VERSION ""

NS_ :

BS_:

BU_: ECM

BO_ 1483 ELATCH9: 32 Vector__XXX
 SG_ Ajar : 1|1@0+ (1,0) [0|1] "" ECM
 SG_ CRC_ELATCH9 : 191|8@0+ (1,0) [0|255] "-" ECM
 SG_ MessageCounter_ELATCH9 : 179|4@0+ (1,0) [0|15] "-" ECM
 SG_ Pawl : 15|1@0+ (1,0) [0|1] "" ECM
 SG_ Pre_Rest : 0|1@0+ (1,0) [0|1] "" ECM
 SG_ Rewind : 14|1@0+ (1,0) [0|1] "" ECM

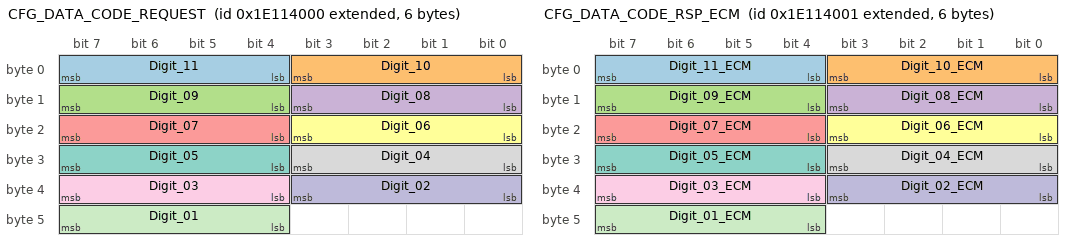
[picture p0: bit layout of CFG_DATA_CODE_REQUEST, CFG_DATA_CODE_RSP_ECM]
BO_ 2651930624 CFG_DATA_CODE_REQUEST: 6 Vector__XXX
 SG_ Digit_11 : 7|4@0+ (1,0) [0|15] "" ECM
 SG_ Digit_10 : 3|4@0+ (1,0) [0|15] "" ECM
 SG_ Digit_09 : 15|4@0+ (1,0) [0|15] "" ECM
 SG_ Digit_08 : 11|4@0+ (1,0) [0|15] "" ECM
 SG_ Digit_07 : 23|4@0+ (1,0) [0|15] "" ECM
 SG_ Digit_06 : 19|4@0+ (1,0) [0|15] "" ECM
 SG_ Digit_05 : 31|4@0+ (1,0) [0|15] "" ECM
 SG_ Digit_04 : 27|4@0+ (1,0) [0|15] "" ECM
 SG_ Digit_03 : 39|4@0+ (1,0) [0|15] "" ECM
 SG_ Digit_02 : 35|4@0+ (1,0) [0|15] "" ECM
 SG_ Digit_01 : 47|4@0+ (1,0) [0|15] "" ECM

BO_ 2651930625 CFG_DATA_CODE_RSP_ECM: 6 ECM
 SG_ Digit_11_ECM : 7|4@0+ (1,0) [0|15] "-"  Vector__XXX
 SG_ Digit_10_ECM : 3|4@0+ (1,0) [0|15] "-"  Vector__XXX
 SG_ Digit_09_ECM : 15|4@0+ (1,0) [0|15] "-"  Vector__XXX
 SG_ Digit_08_ECM : 11|4@0+ (1,0) [0|15] "-"  Vector__XXX
 SG_ Digit_07_ECM : 23|4@0+ (1,0) [0|15] "-"  Vector__XXX
 SG_ Digit_06_ECM : 19|4@0+ (1,0) [0|15] "-"  Vector__XXX
 SG_ Digit_05_ECM : 31|4@0+ (1,0) [0|15] "-"  Vector__XXX
 SG_ Digit_04_ECM : 27|4@0+ (1,0) [0|15] "-"  Vector__XXX
 SG_ Digit_03_ECM : 39|4@0+ (1,0) [0|15] "-"  Vector__XXX
 SG_ Digit_02_ECM : 35|4@0+ (1,0) [0|15] "-"  Vector__XXX
 SG_ Digit_01_ECM : 47|4@0+ (1,0) [0|15] "-"  Vector__XXX

BO_ 2564428017 DIAGNOSTIC_REQUEST_ECM: 8 Vector__XXX
 SG_ N_PDU_18DA10F1 : 7|64@0+ (1,0) [0|0] "" ECM

BO_ 2564554481 DIAGNOSTIC_REQUEST_FUNCTIONAL: 8 Vector__XXX
 SG_ N_PDU_18DBFEF1 : 7|64@0+ (1,0) [0|0] "" ECM

BO_ 2564502513 DIAGNOSTIC_REQUEST_FUNC_OBD: 8 Vector__XXX
 SG_ N_PDU_18DB33F1 : 7|64@0+ (1,0) [0|0] "" ECM

BO_ 2564485392 DIAGNOSTIC_RESPONSE_ECM: 8 ECM
 SG_ N_PDU_18DAF110 : 7|64@0+ (1,0) [0|0] "" Vector__XXX

BO_ 1053 VIN: 32 Vector__XXX
 SG_ VIN_MSG : 75|2@0+ (1,0) [0|3] "" ECM
 SG_ VIN_DATA : 87|56@0+ (1,0) [0|72057594037927900] "" ECM

BO_ 1450 TRANSM_FD_4: 32 Vector__XXX
 SG_ TxDisengaged : 126|1@0+ (1,0) [0|1] "-"  ECM
 SG_ TransmissionFailSts : 87|1@0+ (1,0) [0|1] "-"  ECM
 SG_ ShiftModeSts : 94|1@0+ (1,0) [0|1] "-"  ECM
 SG_ ShiftLeverPosition : 111|4@0+ (1,0) [0|15] "-"  ECM
 SG_ ShiftInProgress : 114|1@0+ (1,0) [0|1] "-"  ECM
 SG_ MIReq : 127|1@0+ (1,0) [0|1] "-"  ECM
 SG_ LimpHomeSts : 112|1@0+ (1,0) [0|1] "-"  ECM
 SG_ GearEngaged : 107|4@0+ (1,0) [0|15] "-"  ECM
 SG_ CrankEnable : 113|1@0+ (1,0) [0|1] "-"  ECM
 SG_ ShiftMapNotAchieved : 121|1@0+ (1,0) [0|1] "-"  ECM
 SG_ MessageCounter_TRANSM4 : 179|4@0+ (1,0) [0|15] "-"  ECM
 SG_ CRC_TRANSM4 : 191|8@0+ (1,0) [0|255] "-"  ECM
 SG_ TxDisengaged_Fault : 118|1@0+ (1,0) [0|1] "-"  ECM
 SG_ Low_Mode_Sts : 181|2@0+ (1,0) [0|3] "" ECM

BO_ 520 TRANSM_FD_2: 32 Vector__XXX
 SG_ TurbineSpeed : 111|16@0+ (1,0) [0|65534] "RPM"  ECM
 SG_ TRNS_StpSt_FLT : 125|1@0+ (1,0) [0|1] "-"  ECM
 SG_ Trns_EMCC_Achvd : 96|1@0+ (1,0) [0|1] "-"  ECM
 SG_ TransReadyForESS : 124|1@0+ (1,0) [0|1] "-"  ECM
 SG_ TransmissionTemperature : 103|6@0+ (3,-40) [-40|149] "°C"  ECM
 SG_ OUTPUT_SPEED : 87|16@0+ (1,0) [0|65534] "RPM"  ECM
 SG_ APCM_Rq : 135|2@0+ (1,0) [0|2] "-"  ECM
 SG_ MessageCounter_TRANSM2 : 179|4@0+ (1,0) [0|15] "-"  ECM
 SG_ EngShutOffRq_TCM : 123|1@0+ (1,0) [0|1] "-"  ECM
 SG_ CRC_TRANSM2 : 191|8@0+ (1,0) [0|255] "-"  ECM
 SG_ Trans_ESS_Inhibit : 2|1@0+ (1,0) [0|1] "-"  ECM
 SG_ GearEngagedForDisplay : 15|5@0+ (1,0) [0|30] "-"  ECM
 SG_ AirFlowRequest_TCM : 22|7@0+ (1,0) [0|100] "%"  ECM

BO_ 1428 TELEMATIC_FD_5: 32 Vector__XXX
 SG_ GlobDrvMdRq : 7|5@0+ (1,0) [0|31] "" ECM

BO_ 156 TELEMATIC_FD_1: 32 Vector__XXX
 SG_ Year4_TLM : 127|4@0+ (1,0) [0|9] "-"  ECM
 SG_ Year3_TLM : 115|4@0+ (1,0) [0|9] "-"  ECM
 SG_ Year2_TLM : 119|4@0+ (1,0) [0|9] "-"  ECM
 SG_ Year1_TLM : 107|4@0+ (1,0) [0|2] "-"  ECM
 SG_ Month2_TLM : 111|4@0+ (1,0) [0|9] "-"  ECM
 SG_ Month1_TLM : 99|4@0+ (1,0) [0|1] "-"  ECM
 SG_ Minute2_TLM : 103|4@0+ (1,0) [0|9] "-"  ECM
 SG_ Minute1_TLM : 91|4@0+ (1,0) [0|5] "-"  ECM
 SG_ Hour2_TLM : 95|4@0+ (1,0) [0|9] "-"  ECM
 SG_ Hour1_TLM : 83|4@0+ (1,0) [0|2] "-"  ECM
 SG_ Day2_TLM : 87|4@0+ (1,0) [0|9] "-"  ECM
 SG_ Day1_TLM : 75|4@0+ (1,0) [0|3] "-"  ECM

BO_ 519 RFHUB_FD_1: 32 Vector__XXX
 SG_ IgnPosSts : 85|3@0+ (1,0) [0|6] "-"  ECM
 SG_ MessageCounter_RFHUB1 : 179|4@0+ (1,0) [0|15] "-"  ECM
 SG_ CRC_RFHUB1 : 191|8@0+ (1,0) [0|255] "-"  ECM

BO_ 274 ORC_FD_3: 32 Vector__XXX
 SG_ LongAcceleration : 131|12@0+ (0.02,-40.96) [-40.96|40.92] "m/s^2"  ECM
 SG_ LatAcceleration : 147|12@0+ (0.02,-40.96) [-40.96|40.92] "m/s^2"  ECM
 SG_ MessageCounter_ORC3 : 179|4@0+ (1,0) [0|15] "-"  ECM
 SG_ LongAccelerationFailSts : 183|1@0+ (1,0) [0|1] "-"  ECM
 SG_ LatAccelerationFailSts : 182|1@0+ (1,0) [0|1] "-"  ECM
 SG_ CRC_ORC3 : 191|8@0+ (1,0) [0|255] "-"  ECM

BO_ 1954 ORC_FD_2: 32 Vector__XXX
 SG_ MessageCounter_ORC2 : 179|4@0+ (1,0) [0|15] "-"  ECM
 SG_ CRC_ORC2 : 191|8@0+ (1,0) [0|255] "-"  ECM
 SG_ DrvSbltUnFltr_1 : 119|8@0+ (0.1,0) [0|25.5] "mA"  ECM

BO_ 1058 OBD_CONTENT_FRAME: 32 ECM
 SG_ LoadOBD : 87|8@0+ (0.3922,0) [0|100] "%"  Vector__XXX
 SG_ InputsGDFail : 94|1@0+ (1,0) [0|1] "-"  Vector__XXX
 SG_ Inp_ICC_Fail : 117|1@0+ (1,0) [0|1] "-"  Vector__XXX
 SG_ IgnCntrTrue : 118|1@0+ (1,0) [0|1] "-"  Vector__XXX
 SG_ GenDenominator : 95|1@0+ (1,0) [0|1] "-"  Vector__XXX
 SG_ EngineOFFTime : 89|10@0+ (1,0) [0|1022] "min"  Vector__XXX
 SG_ CldStrtDenominator : 116|1@0+ (1,0) [0|1] "-"  Vector__XXX
 SG_ CarbWarmUp : 93|1@0+ (1,0) [0|1] "-"  Vector__XXX
 SG_ CARB_PERM : 119|1@0+ (1,0) [0|1] "-"  Vector__XXX
 SG_ AccelPdlPosn_OBD : 111|8@0+ (0.3922,0) [0|100] "%"  Vector__XXX
 SG_ OAT_PT_EstV : 60|1@0+ (1,0) [0|0] "-"  Vector__XXX
 SG_ OAT_PT_Est : 55|8@0+ (1,-64) [-64|191] "°C"  Vector__XXX
 SG_ LgsDiagStndCondMet : 59|1@0+ (1,0) [0|0] "-"  Vector__XXX
 SG_ LgsDiagStndCondFltPrs : 58|1@0+ (1,0) [0|0] "-"  Vector__XXX
 SG_ LgsDiagCldStrtCndMet : 57|1@0+ (1,0) [0|0] "-"  Vector__XXX
 SG_ LgsDiagCldStrtCndFltPr : 56|1@0+ (1,0) [0|0] "-"  Vector__XXX
 SG_ InpICCFuelEng_Fail : 7|1@0+ (1,0) [0|0] "-"  Vector__XXX
 SG_ IgnCntrFuelEngTrue : 6|1@0+ (1,0) [0|0] "-"  Vector__XXX
 SG_ EstCatCnvTmp : 47|8@0+ (5,0) [0|1270] "°C"  Vector__XXX
 SG_ EngOffTmPTV : 5|1@0+ (1,0) [0|0] "-"  Vector__XXX
 SG_ EngOffTmPT : 3|12@0+ (0.5,0) [0.5|2047.5] "min"  Vector__XXX
 SG_ EngLoad_OBD_ePT : 31|8@0+ (0.3922,0) [0|100] "%"  Vector__XXX
 SG_ EngIntAirTmpV : 4|1@0+ (1,0) [0|0] "-"  Vector__XXX
 SG_ EngIntAirTmp : 23|8@0+ (1,-40) [-40|214] "°C"  Vector__XXX
 SG_ ECM_HoodAjar : 91|2@0+ (1,0) [0|3] "-"  Vector__XXX
 SG_ BarPrsAbsV : 92|1@0+ (1,0) [0|0] "-"  Vector__XXX
 SG_ BarPrsAbs : 39|8@0+ (0.5,0) [0|127.5] "kPa"  Vector__XXX
 SG_ MessageCounter_OBDCONTENTFRAME : 179|4@0+ (1,0) [0|15] "-"  Vector__XXX
 SG_ CRC_OBDCONTENTFRAME : 191|8@0+ (1,0) [0|255] "-"  Vector__XXX

BO_ 600 IPC_FD_4: 32 Vector__XXX
 SG_ OilChgRst : 162|1@0+ (1,0) [0|1] "" ECM
 SG_ DisplayedSpeedLimSts : 119|8@0+ (1,0) [0|255] "" ECM

BO_ 1829 IPC_FD_1: 32 Vector__XXX
 SG_ TotalOdometer : 75|20@0+ (1,0) [0|1048575] "km"  ECM
 SG_ MessageCounter_IPC1 : 179|4@0+ (1,0) [0|15] "-"  ECM
 SG_ CRC_IPC1 : 191|8@0+ (1,0) [0|255] "-"  ECM

BO_ 1626 IMPACT_INFO: 32 Vector__XXX
 SG_ IMPACTConfirm : 81|1@0+ (1,0) [0|1] "-"  ECM
 SG_ IMPACTCommand : 80|1@0+ (1,0) [0|1] "-"  ECM
 SG_ IMPACTThreshold : 103|1@0+ (1,0) [0|1] "-"  ECM

BO_ 104 IMMO_CODE_RESPONSE: 32 Vector__XXX
 SG_ MKKey2org22 : 103|8@0+ (1,0) [0|255] "-"  ECM
 SG_ MKKey1org21 : 95|8@0+ (1,0) [0|255] "-"  ECM
 SG_ MKKey_6 : 135|8@0+ (1,0) [0|255] "-"  ECM
 SG_ MKKey_5 : 127|8@0+ (1,0) [0|255] "-"  ECM
 SG_ MKKey_4 : 119|8@0+ (1,0) [0|255] "-"  ECM
 SG_ MKKey_3 : 111|8@0+ (1,0) [0|255] "-"  ECM
 SG_ ControlEncodingRsp : 87|8@0+ (1,0) [0|255] "-"  ECM

BO_ 100 IMMO_CODE_REQUEST: 32 ECM
 SG_ rnd_4 : 135|8@0+ (1,0) [0|255] "-"  Vector__XXX
 SG_ rnd_3 : 127|8@0+ (1,0) [0|255] "-"  Vector__XXX
 SG_ rnd_2 : 119|8@0+ (1,0) [0|255] "-"  Vector__XXX
 SG_ rnd_1 : 111|8@0+ (1,0) [0|255] "-"  Vector__XXX
 SG_ f1_2 : 103|8@0+ (1,0) [0|255] "-"  Vector__XXX
 SG_ f1_1 : 95|8@0+ (1,0) [0|255] "-"  Vector__XXX
 SG_ ControlEncodingReq : 87|8@0+ (1,0) [0|255] "-"  Vector__XXX

BO_ 1955 IBS3_DATA_2: 32 Vector__XXX
 SG_ IBS3_T_BATT : 95|8@0+ (1,-40) [-40|105] "°C"  ECM
 SG_ IBS3_SOH_Q : 110|7@0+ (2,0) [0|252] "Ah"  ECM
 SG_ IBS3_SOC : 86|7@0+ (1,0) [0|100] "%"  ECM
 SG_ IBS3_TempFailStatus : 111|1@0+ (1,0) [0|1] "" ECM
 SG_ IBS3_SOH_Q_Accuracy : 119|1@0+ (1,0) [0|1] "" ECM
 SG_ IBS3_SOC_Accuracy : 87|1@0+ (1,0) [0|1] "" ECM
 SG_ IBS3_FLAG_DISCONNECT : 117|1@0+ (1,0) [0|1] "" ECM

BO_ 264 EPS_FD_1: 32 Vector__XXX
 SG_ LwsAngle : 7|16@0+ (0.1,-720) [-720|720] "°"  ECM
 SG_ LwsSpeed : 19|12@0+ (1,-2000) [-2000|2094] "°/s"  ECM
 SG_ MessageCounter_EPS1 : 179|4@0+ (1,0) [0|15] "-"  ECM
 SG_ CRC_EPS1 : 191|8@0+ (1,0) [0|255] "-"  ECM
 SG_ EngineFanRequestActivation : 38|1@0+ (1,0) [0|1] "-"  ECM

CM_ "Project_WL25_ProjectStandard_FD-CAN3 [CS00155_FD]";
CM_ SG_ 1483 Ajar "Driver Door Ajar Sensor for e-Latch.";
CM_ SG_ 1483 CRC_ELATCH9 "CRC according to SAE J1850 standard at each frame transmission.";
CM_ SG_ 1483 MessageCounter_ELATCH9 "This signal is a counter used for safety checks strategies. This counter is incremented of 1 (one) unit at each frame transmission.";
CM_ SG_ 1483 Pawl "Pawl Driver Door Sensor for e-Latch.";
CM_ SG_ 1483 Pre_Rest "Pre Rest Driver Door Sensor for e-Latch.";
CM_ SG_ 1483 Rewind "Pawl Driver Door Sensor for e-Latch.";
CM_ SG_ 100 ControlEncodingReq "This signal is used for IMMO communication";
CM_ SG_ 100 f1_1 "This signal is used for IMMO communication";
CM_ SG_ 100 f1_2 "This signal is used for IMMO communication";
CM_ SG_ 100 rnd_1 "This signal is used for IMMO communication";
CM_ SG_ 100 rnd_2 "This signal is used for IMMO communication";
CM_ SG_ 100 rnd_3 "This signal is used for IMMO communication";
CM_ SG_ 100 rnd_4 "This signal is used for IMMO communication";
CM_ SG_ 1058 AccelPdlPosn_OBD "Pedal value for OBD (ISO 15031-5.4 PID 49)";
CM_ SG_ 1058 CARB_PERM "Fault code for diagnostics.";
CM_ SG_ 1058 CarbWarmUp "CARB warmup criteria true.  The engine controller will set this bit when the engine coolant temp achieves the CARB warm-up criteria.";
CM_ SG_ 1058 CldStrtDenominator "Cold start denominator conditions are met [1]";
CM_ SG_ 1058 OAT_PT_EstV "Outside air temperature powertrain estimated validity; Invalid = [1]";
CM_ SG_ 1058 InpICCFuelEng_Fail "Second Ignition Cycle Counter Fault Present";
CM_ SG_ 1058 LgsDiagCldStrtCndFltPr "Legislated diagnostics cold start conditions fault present; true = [1]";
CM_ SG_ 1058 LgsDiagCldStrtCndMet "Legislated diagnostics cold start conditions met; true = [1]";
CM_ SG_ 1058 LgsDiagStndCondFltPrs "Legislated diagnostics standard conditions fault present";
CM_ SG_ 1058 LgsDiagStndCondMet "Legislated diagnostics standard conditions met";
CM_ SG_ 1058 OAT_PT_Est "Outside air temperature powertrain estimated";
CM_ SG_ 1058 EngIntAirTmpV "Engine Intake Air Temperature Validity; Invalid = [1]";
CM_ SG_ 1058 EngLoad_OBD_ePT "Load value for OBD (ISO 15031-5.4 PID 4)";
CM_ SG_ 1058 EngOffTmPT "Engine off time powertrain";
CM_ SG_ 1058 EngOffTmPTV "Engine off time powertrain validity (1=invalid)";
CM_ SG_ 1058 EstCatCnvTmp "Estimated catalytic converter temperature";
CM_ SG_ 1058 IgnCntrFuelEngTrue "Second Ignition Cycle Counter";
CM_ SG_ 1058 BarPrsAbs "Barometric pressure absolute";
CM_ SG_ 1058 BarPrsAbsV "Barometric Pressure Absolute Validity; Invalid = [1]";
CM_ SG_ 1058 ECM_HoodAjar "Diagnosed hood status for HVIL.";
CM_ SG_ 1058 EngIntAirTmp "Engine Intake Air Temperature";
CM_ SG_ 1058 MessageCounter_OBDCONTENTFRAME "This signal is a counter used for safety checks strategies. This counter is incremented of 1 (one) unit at each frame transmission.";
CM_ SG_ 264 EngineFanRequestActivation "This signal is used to activate the cooling fun by the electric power steering.";
CM_ SG_ 264 CRC_EPS1 "CRC according to SAE J1850 standard at each frame transmission.";
CM_ SG_ 264 MessageCounter_EPS1 "This signal is a counter used for safety checks strategies. This counter is incremented of 1 (one) unit at each frame transmission.";
CM_ SG_ 1058 CRC_OBDCONTENTFRAME "CRC according to SAE J1850 standard at each frame transmission.";
CM_ SG_ 1058 EngineOFFTime "The number of minutes the engine was off.";
CM_ SG_ 1058 GenDenominator "General denominator conditions are met.  The engine controller will set this bit when the conditions for setting the General Denominator are met for rate based diagnostics.";
CM_ SG_ 1058 IgnCntrTrue "Ignition cycle counter is true [1]";
CM_ SG_ 1058 Inp_ICC_Fail "Inputs to the Ign Cycle Cntr are in a Pend or MIL cond.";
CM_ SG_ 1058 InputsGDFail "General Denominator Requirements Achieved Validity. The engine controller sets this bit when any of the inputs to the General Denominator are in a pending or MIL fault.";
CM_ SG_ 1058 LoadOBD "Engine calculated load value in percentage of load.";
CM_ SG_ 2564485392 N_PDU_18DAF110 "This signal is used for diagnostic purposes";
CM_ SG_ 519 CRC_RFHUB1 "CRC according to SAE J1850 standard at each frame transmission.";
CM_ SG_ 519 MessageCounter_RFHUB1 "This signal is a counter used for safety checks strategies. This counter is incremented of 1 (one) unit at each frame transmission.";
CM_ SG_ 519 IgnPosSts "-";
CM_ SG_ 1428 GlobDrvMdRq "Global drive mode radio request";
CM_ SG_ 264 LwsSpeed "This signal indicates the steering speed value, counterclockwise positive.";
CM_ SG_ 264 LwsAngle "This signal indicates the steering angle value, counterclockwise positive.";
CM_ SG_ 1955 IBS3_FLAG_DISCONNECT "Battery disconnection flag";
CM_ SG_ 1955 IBS3_SOC_Accuracy "SOC accuracy status";
CM_ SG_ 1955 IBS3_SOH_Q_Accuracy "SOH_Q accuracy status";
CM_ SG_ 1955 IBS3_TempFailStatus "Failure of ASIC Temperature meas. (internal defect)";
CM_ SG_ 1955 IBS3_SOC "State of charge";
CM_ SG_ 1955 IBS3_SOH_Q "State of health related to capacity (energy)";
CM_ SG_ 1955 IBS3_T_BATT "Battery temperature";
CM_ SG_ 104 ControlEncodingRsp "This signal is used for IMMO communication";
CM_ SG_ 104 MKKey_3 "This signal is used for IMMO communication";
CM_ SG_ 104 MKKey_4 "This signal is used for IMMO communication";
CM_ SG_ 104 MKKey_5 "This signal is used for IMMO communication";
CM_ SG_ 104 MKKey_6 "This signal is used for IMMO communication";
CM_ SG_ 104 MKKey1org21 "This signal is used for IMMO communication";
CM_ SG_ 104 MKKey2org22 "This signal is used for IMMO communication";
CM_ SG_ 1626 IMPACTThreshold "Upon a crash, the ORC Calibration Threshold was either \"Met\" or \"Not_Met\".";
CM_ SG_ 1626 IMPACTCommand "This signal is used to indicate that a crash happened";
CM_ SG_ 1626 IMPACTConfirm "This signal is used to confirm that a crash happened";
CM_ SG_ 1829 CRC_IPC1 "CRC according to SAE J1850 standard at each frame transmission.";
CM_ SG_ 1829 MessageCounter_IPC1 "This signal is a counter used for safety checks strategies. This counter is incremented of 1 (one) unit at each frame transmission.";
CM_ SG_ 1829 TotalOdometer "Used to give information about the total odometer value in km.";
CM_ SG_ 600 DisplayedSpeedLimSts "This signal indicates the road sign of vehicle speed limit displayed by IPC";
CM_ SG_ 600 OilChgRst "This signal sends the reset command via the EVIC.";
CM_ SG_ 1954 DrvSbltUnFltr_1 "Driver seatbelt fault status - unfiltered";
CM_ SG_ 1954 CRC_ORC2 "CRC according to SAE J1850 standard at each frame transmission.";
CM_ SG_ 1954 MessageCounter_ORC2 "This signal is a counter used for safety checks strategies. This counter is incremented of 1 (one) unit at each frame transmission.";
CM_ SG_ 274 CRC_ORC3 "CRC according to SAE J1850 standard at each frame transmission.";
CM_ SG_ 274 LatAccelerationFailSts "This signal indicates the status of Lateral Acceleration Signal";
CM_ SG_ 274 LongAccelerationFailSts "This signal indicates the status of Longitudinal acceleration signal";
CM_ SG_ 274 MessageCounter_ORC3 "This signal is a counter used for safety checks strategies. This counter is incremented of 1 (one) unit at each frame transmission.";
CM_ SG_ 274 LatAcceleration "This signal indicates the Lateral Acceleration Value";
CM_ SG_ 274 LongAcceleration "This signal indicates the Longitudinal Acceleration Value";
CM_ SG_ 520 APCM_Rq "Auto position correction mode request";
CM_ SG_ 520 OUTPUT_SPEED "Activation request flag for P2 speed  profile";
CM_ SG_ 520 MessageCounter_TRANSM2 "This signal is a counter used for safety checks strategies. This counter is incremented of 1 (one) unit at each frame transmission.";
CM_ SG_ 520 CRC_TRANSM2 "CRC according to SAE J1850 standard at each frame transmission.";
CM_ SG_ 520 EngShutOffRq_TCM "TCM request engine shut off";
CM_ SG_ 520 AirFlowRequest_TCM "Request from TCM to activate AGS,Rad Fan";
CM_ SG_ 520 GearEngagedForDisplay "Transmission Gear engaged signal for Display on cluster.";
CM_ SG_ 520 Trans_ESS_Inhibit "ESS inhibit flag from transmission related to temperature warnings.";
CM_ SG_ 520 TransmissionTemperature "-";
CM_ SG_ 520 TransReadyForESS "-";
CM_ SG_ 520 Trns_EMCC_Achvd "-";
CM_ SG_ 520 TRNS_StpSt_FLT "-";
CM_ SG_ 520 TurbineSpeed "-";
CM_ SG_ 1450 Low_Mode_Sts "Signal Indicating L Mode Status";
CM_ SG_ 1450 MessageCounter_TRANSM4 "This signal is a counter used for safety checks strategies. This counter is incremented of 1 (one) unit at each frame transmission.";
CM_ SG_ 1450 ShiftMapNotAchieved "Transmission shift in progress";
CM_ SG_ 1450 CrankEnable "This signal is used to enable the cranking in safety condition";
CM_ SG_ 1450 GearEngaged "Current engaged gear.";
CM_ SG_ 1450 LimpHomeSts "This signal is used in case of those gearbox faults that limit the higher usable gear.";
CM_ SG_ 1450 TxDisengaged_Fault "Transmission is disengaged";
CM_ SG_ 1450 CRC_TRANSM4 "CRC according to SAE J1850 standard at each frame transmission.";
CM_ SG_ 1450 MIReq "This signal indicates that the gearbox has any EOBD errors.";
CM_ SG_ 1450 ShiftInProgress "Transmission shift in progress";
CM_ SG_ 1450 ShiftLeverPosition "This signal indicates the executed shift lever position.";
CM_ SG_ 1450 ShiftModeSts "This signal indicates the gear selector modality selected by driver (Manual or Automatic).";
CM_ SG_ 1450 TransmissionFailSts "This signal indicates if the TCM currently detects the failure or not (for TCM)";
CM_ SG_ 1450 TxDisengaged "Transmission is disengaged";
CM_ SG_ 1053 VIN_DATA "VIN Digits (8 bit ascii encoded)";
CM_ SG_ 1053 VIN_MSG "VIN Message Information";
CM_ SG_ 2564502513 N_PDU_18DB33F1 "This signal is used for diagnostic purposes";
CM_ SG_ 2564554481 N_PDU_18DBFEF1 "This signal is used for diagnostic purposes";
CM_ SG_ 2564428017 N_PDU_18DA10F1 "This signal is used for diagnostic purposes";
BA_DEF_ SG_ "GenSigTimeoutTime_ADCAM" INT 0 65535;
BA_DEF_ SG_ "GenSigTimeoutTime_EVCU2" INT 0 65535;
BA_DEF_ SG_ "GenSigTimeoutTime_VDCM" INT 0 65535;
BA_DEF_ SG_ "GenSigStartValue" INT 0 2147483647;
BA_DEF_ SG_ "GenSigInactiveValue" INT 0 2147483647;
BA_DEF_ SG_ "GenSigSendType" ENUM "NotUsed","OnWrite","OnWriteWithRepetition","OnChange","OnChangeWithRepetition","IfActive","IfActiveWithRepetition","NoSigSendType";
BA_DEF_ SG_ "SystemSignalLongSymbol" STRING ;
BA_DEF_ SG_ "GenSigTimeoutTime_AGSM" INT 0 65535;
BA_DEF_ SG_ "GenSigTimeoutTime_ASBS" INT 0 65535;
BA_DEF_ SG_ "GenSigTimeoutTime_BCM" INT 0 65535;
BA_DEF_ SG_ "GenSigTimeoutTime_BSM" INT 0 65535;
BA_DEF_ SG_ "GenSigTimeoutTime_CADM" INT 0 65535;
BA_DEF_ SG_ "GenSigTimeoutTime_DMSM" INT 0 65535;
BA_DEF_ SG_ "GenSigTimeoutTime_DTCM" INT 0 65535;
BA_DEF_ SG_ "GenSigTimeoutTime_ECM" INT 0 65535;
BA_DEF_ SG_ "GenSigTimeoutTime_ELSDM" INT 0 65535;
BA_DEF_ SG_ "GenSigTimeoutTime_ESL" INT 0 65535;
BA_DEF_ SG_ "GenSigTimeoutTime_GNMM" INT 0 65535;
BA_DEF_ SG_ "GenSigTimeoutTime_HCP" INT 0 65535;
BA_DEF_ SG_ "GenSigTimeoutTime_IPC" INT 0 65535;
BA_DEF_ SG_ "GenSigTimeoutTime_RFHM" INT 0 65535;
BA_DEF_ SG_ "GenSigTimeoutTime_SGW" INT 0 65535;
BA_DEF_ SG_ "GenSigTimeoutTime_TCM" INT 0 65535;
BA_DEF_ BO_ "DiagRequest" ENUM "No","Yes";
BA_DEF_ BO_ "Type" ENUM "P","C","PE","COC","PE_Cntrl","E","E_Cntrl","OC","S","BAF","DC","EM","MM","ISO-TP","-";
BA_DEF_ BO_ "DiagResponse" ENUM "No","Yes";
BA_DEF_ BO_ "NmMessage" ENUM "No","Yes";
BA_DEF_ BO_ "GenMsgSendType" ENUM "Cyclic","NotUsed","NotUsed","NotUsed","NotUsed","NotUsed","NotUsed","NotUsed","NoMsgSendType";
BA_DEF_ BO_ "GenMsgNrOfRepetition" INT 0 255;
BA_DEF_ BO_ "GenMsgILSupport" ENUM "No","Yes";
BA_DEF_ BO_ "GenMsgStartDelayTime" INT 0 65535;
BA_DEF_ BO_ "GenMsgCycleTimeFast" INT 0 65535;
BA_DEF_ BO_ "GenMsgCycleTime" INT 0 65535;
BA_DEF_ BO_ "GenMsgDelayTime" INT 0 65535;
BA_DEF_ BO_ "NmAsrMessage" ENUM "No","Yes";
BA_DEF_ BO_ "DiagState" ENUM "No","Yes";
BA_DEF_ BO_ "DiagConnection" HEX 0 65535;
BA_DEF_ BO_ "VFrameFormat" ENUM "StandardCAN","ExtendedCAN","reserved","reserved","reserved","reserved","reserved","reserved","reserved","reserved","reserved","reserved","reserved","reserved","StandardCAN_FD","ExtendedCAN_FD";
BA_DEF_ BO_ "CANFD_BRS" ENUM "0","1";
BA_DEF_ "Manufacturer" ENUM "DBAG","VAG","BWVAG","PAG","GM";
BA_DEF_ "NmType" STRING ;
BA_DEF_ "BusType" STRING ;
BA_DEF_ "Baudrate" INT 0 1000000;
BA_DEF_ "DBName" STRING ;
BA_DEF_ "NmAsrTimeoutTime" INT 1 65535;
BA_DEF_ "NmAsrWaitBusSleepTime" INT 1 65535;
BA_DEF_ "NmAsrRepeatMessageTime" INT 1 65535;
BA_DEF_ "NmAsrMessageCount" INT 1 256;
BA_DEF_ "NmAsrBaseAddress" HEX 235487232 2147483647;
BA_DEF_ "NmAsrCanMsgCycleTime" INT 1 65535;
BA_DEF_ "Version" HEX 0 255;
BA_DEF_ "VersionWeek" INT 0 53;
BA_DEF_ "VersionYear" INT 0 99;
BA_DEF_ BU_ "Description" STRING ;
BA_DEF_ BU_ "NmStationAddress" HEX 0 255;
BA_DEF_ BU_ "NmNode" ENUM "No","Yes";
BA_DEF_ BU_ "NmAsrNode" ENUM "No","Yes";
BA_DEF_ BU_ "NmAsrNodeIdentifier" HEX 0 255;
BA_DEF_ BU_ "NmAsrCanMsgReducedTime" INT 1 65535;
BA_DEF_ BU_ "NmNodeType" ENUM "+15_NotWakeable","+30_Wakeable","+30_NotWakeable","kMaster","kSlave15","kSlave30","none";
BA_DEF_ BU_ "NwmNodeType" ENUM "+15_NotWakeable","+30_Wakeable","+30_NotWakeable","kMaster","kSlave15","kSlave30","none";
BA_DEF_DEF_ "GenSigTimeoutTime_ADCAM" 2500;
BA_DEF_DEF_ "GenSigTimeoutTime_EVCU2" 2500;
BA_DEF_DEF_ "GenSigTimeoutTime_VDCM" 2500;
BA_DEF_DEF_ "GenSigStartValue" 0;
BA_DEF_DEF_ "GenSigInactiveValue" 0;
BA_DEF_DEF_ "GenSigSendType" "NoSigSendType";
BA_DEF_DEF_ "SystemSignalLongSymbol" "";
BA_DEF_DEF_ "GenSigTimeoutTime_AGSM" 2500;
BA_DEF_DEF_ "GenSigTimeoutTime_ASBS" 2500;
BA_DEF_DEF_ "GenSigTimeoutTime_BCM" 2500;
BA_DEF_DEF_ "GenSigTimeoutTime_BSM" 2500;
BA_DEF_DEF_ "GenSigTimeoutTime_CADM" 2500;
BA_DEF_DEF_ "GenSigTimeoutTime_DMSM" 2500;
BA_DEF_DEF_ "GenSigTimeoutTime_DTCM" 2500;
BA_DEF_DEF_ "GenSigTimeoutTime_ECM" 2500;
BA_DEF_DEF_ "GenSigTimeoutTime_ELSDM" 2500;
BA_DEF_DEF_ "GenSigTimeoutTime_ESL" 2500;
BA_DEF_DEF_ "GenSigTimeoutTime_GNMM" 2500;
BA_DEF_DEF_ "GenSigTimeoutTime_HCP" 2500;
BA_DEF_DEF_ "GenSigTimeoutTime_IPC" 2500;
BA_DEF_DEF_ "GenSigTimeoutTime_RFHM" 2500;
BA_DEF_DEF_ "GenSigTimeoutTime_SGW" 2500;
BA_DEF_DEF_ "GenSigTimeoutTime_TCM" 2500;
BA_DEF_DEF_ "DiagRequest" "No";
BA_DEF_DEF_ "Type" "-";
BA_DEF_DEF_ "DiagResponse" "No";
BA_DEF_DEF_ "NmMessage" "No";
BA_DEF_DEF_ "GenMsgSendType" "NoMsgSendType";
BA_DEF_DEF_ "GenMsgNrOfRepetition" 0;
BA_DEF_DEF_ "GenMsgILSupport" "No";
BA_DEF_DEF_ "GenMsgStartDelayTime" 0;
BA_DEF_DEF_ "GenMsgCycleTimeFast" 0;
BA_DEF_DEF_ "GenMsgCycleTime" 0;
BA_DEF_DEF_ "GenMsgDelayTime" 0;
BA_DEF_DEF_ "NmAsrMessage" "No";
BA_DEF_DEF_ "DiagState" "No";
BA_DEF_DEF_ "DiagConnection" 0;
BA_DEF_DEF_ "VFrameFormat" "StandardCAN_FD";
BA_DEF_DEF_ "CANFD_BRS" "0";
BA_DEF_DEF_ "Manufacturer" "DBAG";
BA_DEF_DEF_ "NmType" "";
BA_DEF_DEF_ "BusType" "CAN";
BA_DEF_DEF_ "Baudrate" 500000;
BA_DEF_DEF_ "DBName" "CAN";
BA_DEF_DEF_ "NmAsrTimeoutTime" 1000;
BA_DEF_DEF_ "NmAsrWaitBusSleepTime" 750;
BA_DEF_DEF_ "NmAsrRepeatMessageTime" 800;
BA_DEF_DEF_ "NmAsrMessageCount" 256;
BA_DEF_DEF_ "NmAsrBaseAddress" 506724352;
BA_DEF_DEF_ "NmAsrCanMsgCycleTime" 200;
BA_DEF_DEF_ "Version" 160;
BA_DEF_DEF_ "VersionWeek" 34;
BA_DEF_DEF_ "VersionYear" 25;
BA_DEF_DEF_ "Description" "";
BA_DEF_DEF_ "NmStationAddress" 0;
BA_DEF_DEF_ "NmNode" "Yes";
BA_DEF_DEF_ "NmAsrNode" "Yes";
BA_DEF_DEF_ "NmAsrNodeIdentifier" 0;
BA_DEF_DEF_ "NmAsrCanMsgReducedTime" 100;
BA_DEF_DEF_ "NmNodeType" "none";
BA_DEF_DEF_ "NwmNodeType" "none";
BA_ "NmType" "NmAsr";
BA_ "BusType" "CAN FD";
BA_ "DBName" "FDCAN3";
BA_ "NmAsrTimeoutTime" 8000;
BA_ "NmAsrWaitBusSleepTime" 1000;
BA_ "NmAsrRepeatMessageTime" 5000;
BA_ "NmAsrBaseAddress" 507002880;
BA_ "NmAsrCanMsgCycleTime" 1000;
BA_ "Description" BU_ ECM "Engine Control Module";
BA_ "NmStationAddress" BU_ ECM 1;
BA_ "NmAsrNodeIdentifier" BU_ ECM 1;
BA_ "NmAsrCanMsgReducedTime" BU_ ECM 575;
BA_ "NmNodeType" BU_ ECM 1;
BA_ "NwmNodeType" BU_ ECM 1;
BA_ "Type" BO_ 1483 3;
BA_ "GenMsgSendType" BO_ 1483 0;
BA_ "GenMsgNrOfRepetition" BO_ 1483 2;
BA_ "GenMsgILSupport" BO_ 1483 1;
BA_ "GenMsgCycleTime" BO_ 1483 1000;
BA_ "GenMsgDelayTime" BO_ 1483 20;
BA_ "CANFD_BRS" BO_ 1483 1;
BA_ "Type" BO_ 264 1;
BA_ "GenMsgSendType" BO_ 264 0;
BA_ "GenMsgILSupport" BO_ 264 1;
BA_ "GenMsgStartDelayTime" BO_ 264 5;
BA_ "GenMsgCycleTime" BO_ 264 10;
BA_ "CANFD_BRS" BO_ 264 1;
BA_ "Type" BO_ 1955 1;
BA_ "GenMsgSendType" BO_ 1955 0;
BA_ "GenMsgILSupport" BO_ 1955 1;
BA_ "GenMsgStartDelayTime" BO_ 1955 420;
BA_ "GenMsgCycleTime" BO_ 1955 1000;
BA_ "CANFD_BRS" BO_ 1955 1;
BA_ "Type" BO_ 104 11;
BA_ "GenMsgILSupport" BO_ 104 1;
BA_ "CANFD_BRS" BO_ 104 1;
BA_ "Type" BO_ 1626 10;
BA_ "GenMsgSendType" BO_ 1626 0;
BA_ "GenMsgILSupport" BO_ 1626 1;
BA_ "GenMsgStartDelayTime" BO_ 1626 55;
BA_ "GenMsgCycleTimeFast" BO_ 1626 10;
BA_ "GenMsgCycleTime" BO_ 1626 500;
BA_ "CANFD_BRS" BO_ 1626 1;
BA_ "Type" BO_ 1829 1;
BA_ "GenMsgSendType" BO_ 1829 0;
BA_ "GenMsgILSupport" BO_ 1829 1;
BA_ "GenMsgCycleTime" BO_ 1829 1000;
BA_ "CANFD_BRS" BO_ 1829 1;
BA_ "Type" BO_ 600 3;
BA_ "GenMsgSendType" BO_ 600 0;
BA_ "GenMsgNrOfRepetition" BO_ 600 2;
BA_ "GenMsgILSupport" BO_ 600 1;
BA_ "GenMsgCycleTimeFast" BO_ 600 20;
BA_ "GenMsgCycleTime" BO_ 600 100;
BA_ "GenMsgDelayTime" BO_ 600 20;
BA_ "CANFD_BRS" BO_ 600 1;
BA_ "Type" BO_ 1954 3;
BA_ "GenMsgSendType" BO_ 1954 0;
BA_ "GenMsgILSupport" BO_ 1954 1;
BA_ "GenMsgStartDelayTime" BO_ 1954 425;
BA_ "GenMsgCycleTime" BO_ 1954 1000;
BA_ "CANFD_BRS" BO_ 1954 1;
BA_ "Type" BO_ 274 1;
BA_ "GenMsgSendType" BO_ 274 0;
BA_ "GenMsgILSupport" BO_ 274 1;
BA_ "GenMsgStartDelayTime" BO_ 274 5;
BA_ "GenMsgCycleTime" BO_ 274 10;
BA_ "CANFD_BRS" BO_ 274 1;
BA_ "Type" BO_ 156 8;
BA_ "GenMsgILSupport" BO_ 156 1;
BA_ "CANFD_BRS" BO_ 156 1;
BA_ "Type" BO_ 520 1;
BA_ "GenMsgSendType" BO_ 520 0;
BA_ "GenMsgILSupport" BO_ 520 1;
BA_ "GenMsgCycleTime" BO_ 520 20;
BA_ "CANFD_BRS" BO_ 520 1;
BA_ "Type" BO_ 1450 3;
BA_ "GenMsgSendType" BO_ 1450 0;
BA_ "GenMsgNrOfRepetition" BO_ 1450 2;
BA_ "GenMsgILSupport" BO_ 1450 1;
BA_ "GenMsgCycleTimeFast" BO_ 1450 20;
BA_ "GenMsgCycleTime" BO_ 1450 1000;
BA_ "GenMsgDelayTime" BO_ 1450 20;
BA_ "CANFD_BRS" BO_ 1450 1;
BA_ "Type" BO_ 1053 1;
BA_ "GenMsgSendType" BO_ 1053 0;
BA_ "GenMsgILSupport" BO_ 1053 1;
BA_ "GenMsgStartDelayTime" BO_ 1053 95;
BA_ "GenMsgCycleTime" BO_ 1053 100;
BA_ "CANFD_BRS" BO_ 1053 1;
BA_ "Type" BO_ 2564502513 8;
BA_ "DiagState" BO_ 2564502513 1;
BA_ "DiagConnection" BO_ 2564502513 61747;
BA_ "VFrameFormat" BO_ 2564502513 1;
BA_ "Type" BO_ 2564554481 8;
BA_ "DiagState" BO_ 2564554481 1;
BA_ "DiagConnection" BO_ 2564554481 61950;
BA_ "VFrameFormat" BO_ 2564554481 1;
BA_ "DiagRequest" BO_ 2564428017 1;
BA_ "Type" BO_ 2564428017 8;
BA_ "DiagConnection" BO_ 2564428017 61712;
BA_ "VFrameFormat" BO_ 2564428017 1;
BA_ "Type" BO_ 2651930624 8;
BA_ "GenMsgILSupport" BO_ 2651930624 1;
BA_ "GenMsgDelayTime" BO_ 2651930624 10;
BA_ "VFrameFormat" BO_ 2651930624 15;
BA_ "CANFD_BRS" BO_ 2651930624 1;
BA_ "Type" BO_ 519 1;
BA_ "GenMsgSendType" BO_ 519 0;
BA_ "GenMsgILSupport" BO_ 519 1;
BA_ "GenMsgCycleTime" BO_ 519 20;
BA_ "CANFD_BRS" BO_ 519 1;
BA_ "Type" BO_ 1428 3;
BA_ "GenMsgSendType" BO_ 1428 0;
BA_ "GenMsgNrOfRepetition" BO_ 1428 2;
BA_ "GenMsgILSupport" BO_ 1428 1;
BA_ "GenMsgStartDelayTime" BO_ 1428 35;
BA_ "GenMsgCycleTimeFast" BO_ 1428 20;
BA_ "GenMsgCycleTime" BO_ 1428 1000;
BA_ "GenMsgDelayTime" BO_ 1428 20;
BA_ "CANFD_BRS" BO_ 1428 1;
BA_ "GenMsgILSupport" BO_ 2651930625 1;
BA_ "VFrameFormat" BO_ 2651930625 15;
BA_ "CANFD_BRS" BO_ 2651930625 1;
BA_ "Type" BO_ 100 8;
BA_ "GenMsgNrOfRepetition" BO_ 100 2;
BA_ "GenMsgILSupport" BO_ 100 1;
BA_ "GenMsgCycleTimeFast" BO_ 100 20;
BA_ "GenMsgDelayTime" BO_ 100 20;
BA_ "CANFD_BRS" BO_ 100 1;
BA_ "Type" BO_ 1058 1;
BA_ "GenMsgSendType" BO_ 1058 0;
BA_ "GenMsgILSupport" BO_ 1058 1;
BA_ "GenMsgCycleTime" BO_ 1058 100;
BA_ "CANFD_BRS" BO_ 1058 1;
BA_ "Type" BO_ 2564485392 8;
BA_ "DiagResponse" BO_ 2564485392 1;
BA_ "DiagConnection" BO_ 2564485392 61712;
BA_ "VFrameFormat" BO_ 2564485392 1;
BA_ "Type" BO_ 2651930625 11;
BA_ "GenSigSendType" SG_ 1483 Ajar 3;
BA_ "GenSigSendType" SG_ 1483 Pawl 3;
BA_ "GenSigSendType" SG_ 1483 Pre_Rest 3;
BA_ "GenSigSendType" SG_ 1483 Rewind 3;
BA_ "GenSigTimeoutTime_ADCAM" SG_ 1058 GenDenominator 0;
BA_ "GenSigTimeoutTime_EVCU2" SG_ 1058 GenDenominator 0;
BA_ "GenSigTimeoutTime_VDCM" SG_ 1058 GenDenominator 0;
BA_ "GenSigTimeoutTime_TCM" SG_ 1058 GenDenominator 0;
BA_ "GenSigTimeoutTime_ADCAM" SG_ 1058 IgnCntrTrue 0;
BA_ "GenSigTimeoutTime_EVCU2" SG_ 1058 IgnCntrTrue 0;
BA_ "GenSigTimeoutTime_VDCM" SG_ 1058 IgnCntrTrue 0;
BA_ "GenSigTimeoutTime_TCM" SG_ 1058 IgnCntrTrue 0;
BA_ "GenSigTimeoutTime_ADCAM" SG_ 1058 Inp_ICC_Fail 0;
BA_ "GenSigTimeoutTime_EVCU2" SG_ 1058 Inp_ICC_Fail 0;
BA_ "GenSigTimeoutTime_VDCM" SG_ 1058 Inp_ICC_Fail 0;
BA_ "GenSigTimeoutTime_TCM" SG_ 1058 Inp_ICC_Fail 0;
BA_ "GenSigTimeoutTime_ADCAM" SG_ 1058 InputsGDFail 0;
BA_ "GenSigTimeoutTime_EVCU2" SG_ 1058 InputsGDFail 0;
BA_ "GenSigTimeoutTime_VDCM" SG_ 1058 InputsGDFail 0;
BA_ "GenSigTimeoutTime_TCM" SG_ 1058 InputsGDFail 0;
BA_ "GenSigTimeoutTime_ADCAM" SG_ 1058 LoadOBD 0;
BA_ "GenSigTimeoutTime_EVCU2" SG_ 1058 LoadOBD 0;
BA_ "GenSigTimeoutTime_VDCM" SG_ 1058 LoadOBD 0;
BA_ "GenSigTimeoutTime_TCM" SG_ 1058 LoadOBD 0;
BA_ "GenSigTimeoutTime_AGSM" SG_ 1058 AccelPdlPosn_OBD 0;
BA_ "GenSigTimeoutTime_ASBS" SG_ 1058 AccelPdlPosn_OBD 0;
BA_ "GenSigTimeoutTime_BCM" SG_ 1058 AccelPdlPosn_OBD 0;
BA_ "GenSigTimeoutTime_CADM" SG_ 1058 AccelPdlPosn_OBD 0;
BA_ "GenSigTimeoutTime_DMSM" SG_ 1058 AccelPdlPosn_OBD 0;
BA_ "GenSigTimeoutTime_DTCM" SG_ 1058 AccelPdlPosn_OBD 0;
BA_ "GenSigTimeoutTime_ECM" SG_ 1058 AccelPdlPosn_OBD 0;
BA_ "GenSigTimeoutTime_ELSDM" SG_ 1058 AccelPdlPosn_OBD 0;
BA_ "GenSigTimeoutTime_ESL" SG_ 1058 AccelPdlPosn_OBD 0;
BA_ "GenSigTimeoutTime_GNMM" SG_ 1058 AccelPdlPosn_OBD 0;
BA_ "GenSigTimeoutTime_IPC" SG_ 1058 AccelPdlPosn_OBD 0;
BA_ "GenSigTimeoutTime_RFHM" SG_ 1058 AccelPdlPosn_OBD 0;
BA_ "GenSigTimeoutTime_AGSM" SG_ 1058 CARB_PERM 0;
BA_ "GenSigTimeoutTime_ASBS" SG_ 1058 CARB_PERM 0;
BA_ "GenSigTimeoutTime_BCM" SG_ 1058 CARB_PERM 0;
BA_ "GenSigTimeoutTime_CADM" SG_ 1058 CARB_PERM 0;
BA_ "GenSigTimeoutTime_DMSM" SG_ 1058 CARB_PERM 0;
BA_ "GenSigTimeoutTime_DTCM" SG_ 1058 CARB_PERM 0;
BA_ "GenSigTimeoutTime_ECM" SG_ 1058 CARB_PERM 0;
BA_ "GenSigTimeoutTime_ELSDM" SG_ 1058 CARB_PERM 0;
BA_ "GenSigTimeoutTime_ESL" SG_ 1058 CARB_PERM 0;
BA_ "GenSigTimeoutTime_GNMM" SG_ 1058 CARB_PERM 0;
BA_ "GenSigTimeoutTime_IPC" SG_ 1058 CARB_PERM 0;
BA_ "GenSigTimeoutTime_RFHM" SG_ 1058 CARB_PERM 0;
BA_ "GenSigTimeoutTime_SGW" SG_ 1058 CARB_PERM 0;
BA_ "GenSigTimeoutTime_AGSM" SG_ 1058 CarbWarmUp 0;
BA_ "GenSigTimeoutTime_ASBS" SG_ 1058 CarbWarmUp 0;
BA_ "GenSigTimeoutTime_BCM" SG_ 1058 CarbWarmUp 0;
BA_ "GenSigTimeoutTime_BSM" SG_ 1058 CarbWarmUp 0;
BA_ "GenSigTimeoutTime_CADM" SG_ 1058 CarbWarmUp 0;
BA_ "GenSigTimeoutTime_DMSM" SG_ 1058 CarbWarmUp 0;
BA_ "GenSigTimeoutTime_DTCM" SG_ 1058 CarbWarmUp 0;
BA_ "GenSigTimeoutTime_ECM" SG_ 1058 CarbWarmUp 0;
BA_ "GenSigTimeoutTime_ELSDM" SG_ 1058 CarbWarmUp 0;
BA_ "GenSigTimeoutTime_ESL" SG_ 1058 CarbWarmUp 0;
BA_ "GenSigTimeoutTime_GNMM" SG_ 1058 CarbWarmUp 0;
BA_ "GenSigTimeoutTime_HCP" SG_ 1058 CarbWarmUp 0;
BA_ "GenSigTimeoutTime_IPC" SG_ 1058 CarbWarmUp 0;
BA_ "GenSigTimeoutTime_RFHM" SG_ 1058 CarbWarmUp 0;
BA_ "GenSigTimeoutTime_SGW" SG_ 1058 CarbWarmUp 0;
BA_ "GenSigTimeoutTime_AGSM" SG_ 1058 CldStrtDenominator 0;
BA_ "GenSigTimeoutTime_ASBS" SG_ 1058 CldStrtDenominator 0;
BA_ "GenSigTimeoutTime_BCM" SG_ 1058 CldStrtDenominator 0;
BA_ "GenSigTimeoutTime_BSM" SG_ 1058 CldStrtDenominator 0;
BA_ "GenSigTimeoutTime_CADM" SG_ 1058 CldStrtDenominator 0;
BA_ "GenSigTimeoutTime_DMSM" SG_ 1058 CldStrtDenominator 0;
BA_ "GenSigTimeoutTime_DTCM" SG_ 1058 CldStrtDenominator 0;
BA_ "GenSigTimeoutTime_ECM" SG_ 1058 CldStrtDenominator 0;
BA_ "GenSigTimeoutTime_ELSDM" SG_ 1058 CldStrtDenominator 0;
BA_ "GenSigTimeoutTime_ESL" SG_ 1058 CldStrtDenominator 0;
BA_ "GenSigTimeoutTime_GNMM" SG_ 1058 CldStrtDenominator 0;
BA_ "GenSigTimeoutTime_HCP" SG_ 1058 CldStrtDenominator 0;
BA_ "GenSigTimeoutTime_IPC" SG_ 1058 CldStrtDenominator 0;
BA_ "GenSigTimeoutTime_RFHM" SG_ 1058 CldStrtDenominator 0;
BA_ "GenSigTimeoutTime_SGW" SG_ 1058 CldStrtDenominator 0;
BA_ "GenSigTimeoutTime_TCM" SG_ 1058 CldStrtDenominator 0;
BA_ "GenSigTimeoutTime_AGSM" SG_ 1058 OAT_PT_EstV 0;
BA_ "GenSigTimeoutTime_ASBS" SG_ 1058 OAT_PT_EstV 0;
BA_ "GenSigTimeoutTime_BCM" SG_ 1058 OAT_PT_EstV 0;
BA_ "GenSigTimeoutTime_BSM" SG_ 1058 OAT_PT_EstV 0;
BA_ "GenSigTimeoutTime_CADM" SG_ 1058 OAT_PT_EstV 0;
BA_ "GenSigTimeoutTime_DMSM" SG_ 1058 OAT_PT_EstV 0;
BA_ "GenSigTimeoutTime_DTCM" SG_ 1058 OAT_PT_EstV 0;
BA_ "GenSigTimeoutTime_ECM" SG_ 1058 OAT_PT_EstV 0;
BA_ "GenSigTimeoutTime_ELSDM" SG_ 1058 OAT_PT_EstV 0;
BA_ "GenSigTimeoutTime_ESL" SG_ 1058 OAT_PT_EstV 0;
BA_ "GenSigTimeoutTime_GNMM" SG_ 1058 OAT_PT_EstV 0;
BA_ "GenSigTimeoutTime_IPC" SG_ 1058 OAT_PT_EstV 0;
BA_ "GenSigTimeoutTime_RFHM" SG_ 1058 OAT_PT_EstV 0;
BA_ "GenSigTimeoutTime_SGW" SG_ 1058 OAT_PT_EstV 0;
BA_ "GenSigTimeoutTime_TCM" SG_ 1058 OAT_PT_EstV 0;
BA_ "GenSigTimeoutTime_AGSM" SG_ 1058 InpICCFuelEng_Fail 0;
BA_ "GenSigTimeoutTime_ASBS" SG_ 1058 InpICCFuelEng_Fail 0;
BA_ "GenSigTimeoutTime_BCM" SG_ 1058 InpICCFuelEng_Fail 0;
BA_ "GenSigTimeoutTime_BSM" SG_ 1058 InpICCFuelEng_Fail 0;
BA_ "GenSigTimeoutTime_CADM" SG_ 1058 InpICCFuelEng_Fail 0;
BA_ "GenSigTimeoutTime_DMSM" SG_ 1058 InpICCFuelEng_Fail 0;
BA_ "GenSigTimeoutTime_DTCM" SG_ 1058 InpICCFuelEng_Fail 0;
BA_ "GenSigTimeoutTime_ECM" SG_ 1058 InpICCFuelEng_Fail 0;
BA_ "GenSigTimeoutTime_ELSDM" SG_ 1058 InpICCFuelEng_Fail 0;
BA_ "GenSigTimeoutTime_ESL" SG_ 1058 InpICCFuelEng_Fail 0;
BA_ "GenSigTimeoutTime_GNMM" SG_ 1058 InpICCFuelEng_Fail 0;
BA_ "GenSigTimeoutTime_IPC" SG_ 1058 InpICCFuelEng_Fail 0;
BA_ "GenSigTimeoutTime_RFHM" SG_ 1058 InpICCFuelEng_Fail 0;
BA_ "GenSigTimeoutTime_SGW" SG_ 1058 InpICCFuelEng_Fail 0;
BA_ "GenSigTimeoutTime_TCM" SG_ 1058 InpICCFuelEng_Fail 0;
BA_ "GenSigTimeoutTime_AGSM" SG_ 1058 LgsDiagCldStrtCndFltPr 0;
BA_ "GenSigTimeoutTime_ASBS" SG_ 1058 LgsDiagCldStrtCndFltPr 0;
BA_ "GenSigTimeoutTime_BCM" SG_ 1058 LgsDiagCldStrtCndFltPr 0;
BA_ "GenSigTimeoutTime_BSM" SG_ 1058 LgsDiagCldStrtCndFltPr 0;
BA_ "GenSigTimeoutTime_CADM" SG_ 1058 LgsDiagCldStrtCndFltPr 0;
BA_ "GenSigTimeoutTime_DMSM" SG_ 1058 LgsDiagCldStrtCndFltPr 0;
BA_ "GenSigTimeoutTime_DTCM" SG_ 1058 LgsDiagCldStrtCndFltPr 0;
BA_ "GenSigTimeoutTime_ECM" SG_ 1058 LgsDiagCldStrtCndFltPr 0;
BA_ "GenSigTimeoutTime_ELSDM" SG_ 1058 LgsDiagCldStrtCndFltPr 0;
BA_ "GenSigTimeoutTime_ESL" SG_ 1058 LgsDiagCldStrtCndFltPr 0;
BA_ "GenSigTimeoutTime_GNMM" SG_ 1058 LgsDiagCldStrtCndFltPr 0;
BA_ "GenSigTimeoutTime_IPC" SG_ 1058 LgsDiagCldStrtCndFltPr 0;
BA_ "GenSigTimeoutTime_RFHM" SG_ 1058 LgsDiagCldStrtCndFltPr 0;
BA_ "GenSigTimeoutTime_SGW" SG_ 1058 LgsDiagCldStrtCndFltPr 0;
BA_ "GenSigTimeoutTime_TCM" SG_ 1058 LgsDiagCldStrtCndFltPr 0;
BA_ "GenSigTimeoutTime_AGSM" SG_ 1058 LgsDiagCldStrtCndMet 0;
BA_ "GenSigTimeoutTime_ASBS" SG_ 1058 LgsDiagCldStrtCndMet 0;
BA_ "GenSigTimeoutTime_BCM" SG_ 1058 LgsDiagCldStrtCndMet 0;
BA_ "GenSigTimeoutTime_BSM" SG_ 1058 LgsDiagCldStrtCndMet 0;
BA_ "GenSigTimeoutTime_CADM" SG_ 1058 LgsDiagCldStrtCndMet 0;
BA_ "GenSigTimeoutTime_DMSM" SG_ 1058 LgsDiagCldStrtCndMet 0;
BA_ "GenSigTimeoutTime_DTCM" SG_ 1058 LgsDiagCldStrtCndMet 0;
BA_ "GenSigTimeoutTime_ECM" SG_ 1058 LgsDiagCldStrtCndMet 0;
BA_ "GenSigTimeoutTime_ELSDM" SG_ 1058 LgsDiagCldStrtCndMet 0;
BA_ "GenSigTimeoutTime_ESL" SG_ 1058 LgsDiagCldStrtCndMet 0;
BA_ "GenSigTimeoutTime_GNMM" SG_ 1058 LgsDiagCldStrtCndMet 0;
BA_ "GenSigTimeoutTime_IPC" SG_ 1058 LgsDiagCldStrtCndMet 0;
BA_ "GenSigTimeoutTime_RFHM" SG_ 1058 LgsDiagCldStrtCndMet 0;
BA_ "GenSigTimeoutTime_SGW" SG_ 1058 LgsDiagCldStrtCndMet 0;
BA_ "GenSigTimeoutTime_TCM" SG_ 1058 LgsDiagCldStrtCndMet 0;
BA_ "GenSigTimeoutTime_AGSM" SG_ 1058 LgsDiagStndCondFltPrs 0;
BA_ "GenSigTimeoutTime_ASBS" SG_ 1058 LgsDiagStndCondFltPrs 0;
BA_ "GenSigTimeoutTime_BCM" SG_ 1058 LgsDiagStndCondFltPrs 0;
BA_ "GenSigTimeoutTime_BSM" SG_ 1058 LgsDiagStndCondFltPrs 0;
BA_ "GenSigTimeoutTime_CADM" SG_ 1058 LgsDiagStndCondFltPrs 0;
BA_ "GenSigTimeoutTime_DMSM" SG_ 1058 LgsDiagStndCondFltPrs 0;
BA_ "GenSigTimeoutTime_DTCM" SG_ 1058 LgsDiagStndCondFltPrs 0;
BA_ "GenSigTimeoutTime_ECM" SG_ 1058 LgsDiagStndCondFltPrs 0;
BA_ "GenSigTimeoutTime_ELSDM" SG_ 1058 LgsDiagStndCondFltPrs 0;
BA_ "GenSigTimeoutTime_ESL" SG_ 1058 LgsDiagStndCondFltPrs 0;
BA_ "GenSigTimeoutTime_GNMM" SG_ 1058 LgsDiagStndCondFltPrs 0;
BA_ "GenSigTimeoutTime_IPC" SG_ 1058 LgsDiagStndCondFltPrs 0;
BA_ "GenSigTimeoutTime_RFHM" SG_ 1058 LgsDiagStndCondFltPrs 0;
BA_ "GenSigTimeoutTime_SGW" SG_ 1058 LgsDiagStndCondFltPrs 0;
BA_ "GenSigTimeoutTime_TCM" SG_ 1058 LgsDiagStndCondFltPrs 0;
BA_ "GenSigTimeoutTime_AGSM" SG_ 1058 LgsDiagStndCondMet 0;
BA_ "GenSigTimeoutTime_ASBS" SG_ 1058 LgsDiagStndCondMet 0;
BA_ "GenSigTimeoutTime_BCM" SG_ 1058 LgsDiagStndCondMet 0;
BA_ "GenSigTimeoutTime_BSM" SG_ 1058 LgsDiagStndCondMet 0;
BA_ "GenSigTimeoutTime_CADM" SG_ 1058 LgsDiagStndCondMet 0;
BA_ "GenSigTimeoutTime_DMSM" SG_ 1058 LgsDiagStndCondMet 0;
BA_ "GenSigTimeoutTime_DTCM" SG_ 1058 LgsDiagStndCondMet 0;
BA_ "GenSigTimeoutTime_ECM" SG_ 1058 LgsDiagStndCondMet 0;
BA_ "GenSigTimeoutTime_ELSDM" SG_ 1058 LgsDiagStndCondMet 0;
BA_ "GenSigTimeoutTime_ESL" SG_ 1058 LgsDiagStndCondMet 0;
BA_ "GenSigTimeoutTime_GNMM" SG_ 1058 LgsDiagStndCondMet 0;
BA_ "GenSigTimeoutTime_IPC" SG_ 1058 LgsDiagStndCondMet 0;
BA_ "GenSigTimeoutTime_RFHM" SG_ 1058 LgsDiagStndCondMet 0;
BA_ "GenSigTimeoutTime_SGW" SG_ 1058 LgsDiagStndCondMet 0;
BA_ "GenSigTimeoutTime_TCM" SG_ 1058 LgsDiagStndCondMet 0;
BA_ "GenSigTimeoutTime_AGSM" SG_ 1058 OAT_PT_Est 0;
BA_ "GenSigTimeoutTime_ASBS" SG_ 1058 OAT_PT_Est 0;
BA_ "GenSigTimeoutTime_BCM" SG_ 1058 OAT_PT_Est 0;
BA_ "GenSigTimeoutTime_BSM" SG_ 1058 OAT_PT_Est 0;
BA_ "GenSigTimeoutTime_CADM" SG_ 1058 OAT_PT_Est 0;
BA_ "GenSigTimeoutTime_DMSM" SG_ 1058 OAT_PT_Est 0;
BA_ "GenSigTimeoutTime_DTCM" SG_ 1058 OAT_PT_Est 0;
BA_ "GenSigTimeoutTime_ECM" SG_ 1058 OAT_PT_Est 0;
BA_ "GenSigTimeoutTime_ELSDM" SG_ 1058 OAT_PT_Est 0;
BA_ "GenSigTimeoutTime_ESL" SG_ 1058 OAT_PT_Est 0;
BA_ "GenSigTimeoutTime_GNMM" SG_ 1058 OAT_PT_Est 0;
BA_ "GenSigTimeoutTime_IPC" SG_ 1058 OAT_PT_Est 0;
BA_ "GenSigTimeoutTime_RFHM" SG_ 1058 OAT_PT_Est 0;
BA_ "GenSigTimeoutTime_SGW" SG_ 1058 OAT_PT_Est 0;
BA_ "GenSigTimeoutTime_TCM" SG_ 1058 OAT_PT_Est 0;
BA_ "GenSigTimeoutTime_AGSM" SG_ 1058 EngIntAirTmpV 0;
BA_ "GenSigTimeoutTime_ASBS" SG_ 1058 EngIntAirTmpV 0;
BA_ "GenSigTimeoutTime_BCM" SG_ 1058 EngIntAirTmpV 0;
BA_ "GenSigTimeoutTime_BSM" SG_ 1058 EngIntAirTmpV 0;
BA_ "GenSigTimeoutTime_CADM" SG_ 1058 EngIntAirTmpV 0;
BA_ "GenSigTimeoutTime_DMSM" SG_ 1058 EngIntAirTmpV 0;
BA_ "GenSigTimeoutTime_DTCM" SG_ 1058 EngIntAirTmpV 0;
BA_ "GenSigTimeoutTime_ECM" SG_ 1058 EngIntAirTmpV 0;
BA_ "GenSigTimeoutTime_ELSDM" SG_ 1058 EngIntAirTmpV 0;
BA_ "GenSigTimeoutTime_ESL" SG_ 1058 EngIntAirTmpV 0;
BA_ "GenSigTimeoutTime_GNMM" SG_ 1058 EngIntAirTmpV 0;
BA_ "GenSigTimeoutTime_IPC" SG_ 1058 EngIntAirTmpV 0;
BA_ "GenSigTimeoutTime_RFHM" SG_ 1058 EngIntAirTmpV 0;
BA_ "GenSigTimeoutTime_SGW" SG_ 1058 EngIntAirTmpV 0;
BA_ "GenSigTimeoutTime_TCM" SG_ 1058 EngIntAirTmpV 0;
BA_ "GenSigTimeoutTime_AGSM" SG_ 1058 EngLoad_OBD_ePT 0;
BA_ "GenSigTimeoutTime_ASBS" SG_ 1058 EngLoad_OBD_ePT 0;
BA_ "GenSigTimeoutTime_BCM" SG_ 1058 EngLoad_OBD_ePT 0;
BA_ "GenSigTimeoutTime_BSM" SG_ 1058 EngLoad_OBD_ePT 0;
BA_ "GenSigTimeoutTime_CADM" SG_ 1058 EngLoad_OBD_ePT 0;
BA_ "GenSigTimeoutTime_DMSM" SG_ 1058 EngLoad_OBD_ePT 0;
BA_ "GenSigTimeoutTime_DTCM" SG_ 1058 EngLoad_OBD_ePT 0;
BA_ "GenSigTimeoutTime_ECM" SG_ 1058 EngLoad_OBD_ePT 0;
BA_ "GenSigTimeoutTime_ELSDM" SG_ 1058 EngLoad_OBD_ePT 0;
BA_ "GenSigTimeoutTime_ESL" SG_ 1058 EngLoad_OBD_ePT 0;
BA_ "GenSigTimeoutTime_GNMM" SG_ 1058 EngLoad_OBD_ePT 0;
BA_ "GenSigTimeoutTime_IPC" SG_ 1058 EngLoad_OBD_ePT 0;
BA_ "GenSigTimeoutTime_RFHM" SG_ 1058 EngLoad_OBD_ePT 0;
BA_ "GenSigTimeoutTime_SGW" SG_ 1058 EngLoad_OBD_ePT 0;
BA_ "GenSigTimeoutTime_TCM" SG_ 1058 EngLoad_OBD_ePT 0;
BA_ "GenSigTimeoutTime_AGSM" SG_ 1058 EngOffTmPT 0;
BA_ "GenSigTimeoutTime_ASBS" SG_ 1058 EngOffTmPT 0;
BA_ "GenSigTimeoutTime_BCM" SG_ 1058 EngOffTmPT 0;
BA_ "GenSigTimeoutTime_BSM" SG_ 1058 EngOffTmPT 0;
BA_ "GenSigTimeoutTime_CADM" SG_ 1058 EngOffTmPT 0;
BA_ "GenSigTimeoutTime_DMSM" SG_ 1058 EngOffTmPT 0;
BA_ "GenSigTimeoutTime_DTCM" SG_ 1058 EngOffTmPT 0;
BA_ "GenSigTimeoutTime_ECM" SG_ 1058 EngOffTmPT 0;
BA_ "GenSigTimeoutTime_ELSDM" SG_ 1058 EngOffTmPT 0;
BA_ "GenSigTimeoutTime_ESL" SG_ 1058 EngOffTmPT 0;
BA_ "GenSigTimeoutTime_GNMM" SG_ 1058 EngOffTmPT 0;
BA_ "GenSigTimeoutTime_IPC" SG_ 1058 EngOffTmPT 0;
BA_ "GenSigTimeoutTime_RFHM" SG_ 1058 EngOffTmPT 0;
BA_ "GenSigTimeoutTime_SGW" SG_ 1058 EngOffTmPT 0;
BA_ "GenSigTimeoutTime_TCM" SG_ 1058 EngOffTmPT 0;
BA_ "GenSigStartValue" SG_ 1058 EngOffTmPTV 1;
BA_ "GenSigTimeoutTime_AGSM" SG_ 1058 EngOffTmPTV 0;
BA_ "GenSigTimeoutTime_ASBS" SG_ 1058 EngOffTmPTV 0;
BA_ "GenSigTimeoutTime_BCM" SG_ 1058 EngOffTmPTV 0;
BA_ "GenSigTimeoutTime_BSM" SG_ 1058 EngOffTmPTV 0;
BA_ "GenSigTimeoutTime_CADM" SG_ 1058 EngOffTmPTV 0;
BA_ "GenSigTimeoutTime_DMSM" SG_ 1058 EngOffTmPTV 0;
BA_ "GenSigTimeoutTime_DTCM" SG_ 1058 EngOffTmPTV 0;
BA_ "GenSigTimeoutTime_ECM" SG_ 1058 EngOffTmPTV 0;
BA_ "GenSigTimeoutTime_ELSDM" SG_ 1058 EngOffTmPTV 0;
BA_ "GenSigTimeoutTime_ESL" SG_ 1058 EngOffTmPTV 0;
BA_ "GenSigTimeoutTime_GNMM" SG_ 1058 EngOffTmPTV 0;
BA_ "GenSigTimeoutTime_IPC" SG_ 1058 EngOffTmPTV 0;
BA_ "GenSigTimeoutTime_RFHM" SG_ 1058 EngOffTmPTV 0;
BA_ "GenSigTimeoutTime_SGW" SG_ 1058 EngOffTmPTV 0;
BA_ "GenSigTimeoutTime_TCM" SG_ 1058 EngOffTmPTV 0;
BA_ "GenSigTimeoutTime_AGSM" SG_ 1058 EstCatCnvTmp 0;
BA_ "GenSigTimeoutTime_ASBS" SG_ 1058 EstCatCnvTmp 0;
BA_ "GenSigTimeoutTime_BCM" SG_ 1058 EstCatCnvTmp 0;
BA_ "GenSigTimeoutTime_BSM" SG_ 1058 EstCatCnvTmp 0;
BA_ "GenSigTimeoutTime_CADM" SG_ 1058 EstCatCnvTmp 0;
BA_ "GenSigTimeoutTime_DMSM" SG_ 1058 EstCatCnvTmp 0;
BA_ "GenSigTimeoutTime_DTCM" SG_ 1058 EstCatCnvTmp 0;
BA_ "GenSigTimeoutTime_GNMM" SG_ 1955 IBS3_TempFailStatus 0;
BA_ "GenSigTimeoutTime_IPC" SG_ 1955 IBS3_TempFailStatus 0;
BA_ "GenSigTimeoutTime_RFHM" SG_ 1955 IBS3_TempFailStatus 0;
BA_ "GenSigTimeoutTime_TCM" SG_ 1955 IBS3_TempFailStatus 0;
BA_ "GenSigStartValue" SG_ 1955 IBS3_SOC 127;
BA_ "GenSigTimeoutTime_AGSM" SG_ 1955 IBS3_SOC 0;
BA_ "GenSigTimeoutTime_ASBS" SG_ 1955 IBS3_SOC 0;
BA_ "GenSigTimeoutTime_BCM" SG_ 1955 IBS3_SOC 0;
BA_ "GenSigTimeoutTime_BSM" SG_ 1955 IBS3_SOC 0;
BA_ "GenSigTimeoutTime_DMSM" SG_ 1955 IBS3_SOC 0;
BA_ "GenSigTimeoutTime_DTCM" SG_ 1955 IBS3_SOC 0;
BA_ "GenSigTimeoutTime_ELSDM" SG_ 1955 IBS3_SOC 0;
BA_ "GenSigTimeoutTime_ESL" SG_ 1955 IBS3_SOC 0;
BA_ "GenSigTimeoutTime_GNMM" SG_ 1955 IBS3_SOC 0;
BA_ "GenSigTimeoutTime_IPC" SG_ 1955 IBS3_SOC 0;
BA_ "GenSigTimeoutTime_TCM" SG_ 1955 IBS3_SOC 0;
BA_ "GenSigStartValue" SG_ 1955 IBS3_SOH_Q 127;
BA_ "GenSigTimeoutTime_AGSM" SG_ 1955 IBS3_SOH_Q 0;
BA_ "GenSigTimeoutTime_ASBS" SG_ 1955 IBS3_SOH_Q 0;
BA_ "GenSigTimeoutTime_BCM" SG_ 1955 IBS3_SOH_Q 0;
BA_ "GenSigTimeoutTime_BSM" SG_ 1955 IBS3_SOH_Q 0;
BA_ "GenSigTimeoutTime_CADM" SG_ 1955 IBS3_SOH_Q 0;
BA_ "GenSigTimeoutTime_DMSM" SG_ 1955 IBS3_SOH_Q 0;
BA_ "GenSigTimeoutTime_DTCM" SG_ 1955 IBS3_SOH_Q 0;
BA_ "GenSigTimeoutTime_ELSDM" SG_ 1955 IBS3_SOH_Q 0;
BA_ "GenSigTimeoutTime_ESL" SG_ 1955 IBS3_SOH_Q 0;
BA_ "GenSigTimeoutTime_GNMM" SG_ 1955 IBS3_SOH_Q 0;
BA_ "GenSigTimeoutTime_HCP" SG_ 1955 IBS3_SOH_Q 0;
BA_ "GenSigTimeoutTime_IPC" SG_ 1955 IBS3_SOH_Q 0;
BA_ "GenSigTimeoutTime_RFHM" SG_ 1955 IBS3_SOH_Q 0;
BA_ "GenSigTimeoutTime_SGW" SG_ 1955 IBS3_SOH_Q 0;
BA_ "GenSigTimeoutTime_TCM" SG_ 1955 IBS3_SOH_Q 0;
BA_ "GenSigStartValue" SG_ 1955 IBS3_T_BATT 255;
BA_ "GenSigTimeoutTime_AGSM" SG_ 1955 IBS3_T_BATT 0;
BA_ "GenSigTimeoutTime_ASBS" SG_ 1955 IBS3_T_BATT 0;
BA_ "GenSigTimeoutTime_BCM" SG_ 1955 IBS3_T_BATT 0;
BA_ "GenSigTimeoutTime_BSM" SG_ 1955 IBS3_T_BATT 0;
BA_ "GenSigTimeoutTime_CADM" SG_ 1955 IBS3_T_BATT 0;
BA_ "GenSigTimeoutTime_DMSM" SG_ 1955 IBS3_T_BATT 0;
BA_ "GenSigTimeoutTime_DTCM" SG_ 1955 IBS3_T_BATT 0;
BA_ "GenSigTimeoutTime_ELSDM" SG_ 1955 IBS3_T_BATT 0;
BA_ "GenSigTimeoutTime_ESL" SG_ 1955 IBS3_T_BATT 0;
BA_ "GenSigTimeoutTime_GNMM" SG_ 1955 IBS3_T_BATT 0;
BA_ "GenSigTimeoutTime_IPC" SG_ 1955 IBS3_T_BATT 0;
BA_ "GenSigTimeoutTime_RFHM" SG_ 1955 IBS3_T_BATT 0;
BA_ "GenSigTimeoutTime_TCM" SG_ 1955 IBS3_T_BATT 0;
BA_ "GenSigTimeoutTime_ADCAM" SG_ 104 ControlEncodingRsp 0;
BA_ "GenSigTimeoutTime_VDCM" SG_ 104 ControlEncodingRsp 0;
BA_ "GenSigTimeoutTime_ADCAM" SG_ 104 MKKey_3 0;
BA_ "GenSigTimeoutTime_VDCM" SG_ 104 MKKey_3 0;
BA_ "GenSigTimeoutTime_ADCAM" SG_ 104 MKKey_4 0;
BA_ "GenSigTimeoutTime_VDCM" SG_ 104 MKKey_4 0;
BA_ "GenSigTimeoutTime_ADCAM" SG_ 104 MKKey_5 0;
BA_ "GenSigTimeoutTime_VDCM" SG_ 104 MKKey_5 0;
BA_ "GenSigTimeoutTime_ADCAM" SG_ 104 MKKey_6 0;
BA_ "GenSigTimeoutTime_VDCM" SG_ 104 MKKey_6 0;
BA_ "GenSigTimeoutTime_ADCAM" SG_ 104 MKKey1org21 0;
BA_ "GenSigTimeoutTime_VDCM" SG_ 104 MKKey1org21 0;
BA_ "GenSigTimeoutTime_ADCAM" SG_ 104 MKKey2org22 0;
BA_ "GenSigTimeoutTime_VDCM" SG_ 104 MKKey2org22 0;
BA_ "GenSigSendType" SG_ 104 ControlEncodingRsp 1;
BA_ "GenSigTimeoutTime_AGSM" SG_ 104 ControlEncodingRsp 0;
BA_ "GenSigTimeoutTime_ASBS" SG_ 104 ControlEncodingRsp 0;
BA_ "GenSigTimeoutTime_BCM" SG_ 104 ControlEncodingRsp 0;
BA_ "GenSigTimeoutTime_BSM" SG_ 104 ControlEncodingRsp 0;
BA_ "GenSigTimeoutTime_CADM" SG_ 104 ControlEncodingRsp 0;
BA_ "GenSigTimeoutTime_DMSM" SG_ 104 ControlEncodingRsp 0;
BA_ "GenSigTimeoutTime_DTCM" SG_ 104 ControlEncodingRsp 0;
BA_ "GenSigTimeoutTime_ELSDM" SG_ 104 ControlEncodingRsp 0;
BA_ "GenSigTimeoutTime_ESL" SG_ 104 ControlEncodingRsp 0;
BA_ "GenSigTimeoutTime_GNMM" SG_ 104 ControlEncodingRsp 0;
BA_ "GenSigTimeoutTime_HCP" SG_ 104 ControlEncodingRsp 0;
BA_ "GenSigTimeoutTime_IPC" SG_ 104 ControlEncodingRsp 0;
BA_ "GenSigTimeoutTime_RFHM" SG_ 104 ControlEncodingRsp 0;
BA_ "GenSigTimeoutTime_SGW" SG_ 104 ControlEncodingRsp 0;
BA_ "GenSigTimeoutTime_TCM" SG_ 104 ControlEncodingRsp 0;
BA_ "GenSigTimeoutTime_AGSM" SG_ 104 MKKey_3 0;
BA_ "GenSigTimeoutTime_ASBS" SG_ 104 MKKey_3 0;
BA_ "GenSigTimeoutTime_BCM" SG_ 104 MKKey_3 0;
BA_ "GenSigTimeoutTime_BSM" SG_ 104 MKKey_3 0;
BA_ "GenSigTimeoutTime_CADM" SG_ 104 MKKey_3 0;
BA_ "GenSigTimeoutTime_DMSM" SG_ 104 MKKey_3 0;
BA_ "GenSigTimeoutTime_DTCM" SG_ 104 MKKey_3 0;
BA_ "GenSigTimeoutTime_ELSDM" SG_ 104 MKKey_3 0;
BA_ "GenSigTimeoutTime_ESL" SG_ 104 MKKey_3 0;
BA_ "GenSigTimeoutTime_GNMM" SG_ 104 MKKey_3 0;
BA_ "GenSigTimeoutTime_HCP" SG_ 104 MKKey_3 0;
BA_ "GenSigTimeoutTime_IPC" SG_ 104 MKKey_3 0;
BA_ "GenSigTimeoutTime_RFHM" SG_ 104 MKKey_3 0;
BA_ "GenSigTimeoutTime_SGW" SG_ 104 MKKey_3 0;
BA_ "GenSigTimeoutTime_TCM" SG_ 104 MKKey_3 0;
BA_ "GenSigTimeoutTime_AGSM" SG_ 104 MKKey_4 0;
BA_ "GenSigTimeoutTime_ASBS" SG_ 104 MKKey_4 0;
BA_ "GenSigTimeoutTime_BCM" SG_ 104 MKKey_4 0;
BA_ "GenSigTimeoutTime_BSM" SG_ 104 MKKey_4 0;
BA_ "GenSigTimeoutTime_CADM" SG_ 104 MKKey_4 0;
BA_ "GenSigTimeoutTime_DMSM" SG_ 104 MKKey_4 0;
BA_ "GenSigTimeoutTime_DTCM" SG_ 104 MKKey_4 0;
BA_ "GenSigTimeoutTime_CADM" SG_ 2564502513 N_PDU_18DB33F1 0;
BA_ "GenSigTimeoutTime_DMSM" SG_ 2564502513 N_PDU_18DB33F1 0;
BA_ "GenSigTimeoutTime_DTCM" SG_ 2564502513 N_PDU_18DB33F1 0;
BA_ "GenSigTimeoutTime_ECM" SG_ 2564502513 N_PDU_18DB33F1 0;
BA_ "GenSigTimeoutTime_ELSDM" SG_ 2564502513 N_PDU_18DB33F1 0;
BA_ "GenSigTimeoutTime_ESL" SG_ 2564502513 N_PDU_18DB33F1 0;
BA_ "GenSigTimeoutTime_GNMM" SG_ 2564502513 N_PDU_18DB33F1 0;
BA_ "GenSigTimeoutTime_HCP" SG_ 2564502513 N_PDU_18DB33F1 0;
BA_ "GenSigTimeoutTime_IPC" SG_ 2564502513 N_PDU_18DB33F1 0;
BA_ "GenSigTimeoutTime_RFHM" SG_ 2564502513 N_PDU_18DB33F1 0;
BA_ "GenSigTimeoutTime_SGW" SG_ 2564502513 N_PDU_18DB33F1 0;
BA_ "GenSigTimeoutTime_TCM" SG_ 2564502513 N_PDU_18DB33F1 0;
BA_ "GenSigTimeoutTime_ADCAM" SG_ 2564554481 N_PDU_18DBFEF1 0;
BA_ "GenSigTimeoutTime_EVCU2" SG_ 2564554481 N_PDU_18DBFEF1 0;
BA_ "GenSigTimeoutTime_VDCM" SG_ 2564554481 N_PDU_18DBFEF1 0;
BA_ "GenSigTimeoutTime_AGSM" SG_ 2564554481 N_PDU_18DBFEF1 0;
BA_ "GenSigTimeoutTime_ASBS" SG_ 2564554481 N_PDU_18DBFEF1 0;
BA_ "GenSigTimeoutTime_BCM" SG_ 2564554481 N_PDU_18DBFEF1 0;
BA_ "GenSigTimeoutTime_BSM" SG_ 2564554481 N_PDU_18DBFEF1 0;
BA_ "GenSigTimeoutTime_CADM" SG_ 2564554481 N_PDU_18DBFEF1 0;
BA_ "GenSigTimeoutTime_DMSM" SG_ 2564554481 N_PDU_18DBFEF1 0;
BA_ "GenSigTimeoutTime_DTCM" SG_ 2564554481 N_PDU_18DBFEF1 0;
BA_ "GenSigTimeoutTime_ECM" SG_ 2564554481 N_PDU_18DBFEF1 0;
BA_ "GenSigTimeoutTime_ELSDM" SG_ 2564554481 N_PDU_18DBFEF1 0;
BA_ "GenSigTimeoutTime_ESL" SG_ 2564554481 N_PDU_18DBFEF1 0;
BA_ "GenSigTimeoutTime_GNMM" SG_ 2564554481 N_PDU_18DBFEF1 0;
BA_ "GenSigTimeoutTime_HCP" SG_ 2564554481 N_PDU_18DBFEF1 0;
BA_ "GenSigTimeoutTime_IPC" SG_ 2564554481 N_PDU_18DBFEF1 0;
BA_ "GenSigTimeoutTime_RFHM" SG_ 2564554481 N_PDU_18DBFEF1 0;
BA_ "GenSigTimeoutTime_SGW" SG_ 2564554481 N_PDU_18DBFEF1 0;
BA_ "GenSigTimeoutTime_TCM" SG_ 2564554481 N_PDU_18DBFEF1 0;
BA_ "GenSigTimeoutTime_ADCAM" SG_ 2564428017 N_PDU_18DA10F1 0;
BA_ "GenSigTimeoutTime_EVCU2" SG_ 2564428017 N_PDU_18DA10F1 0;
BA_ "GenSigTimeoutTime_VDCM" SG_ 2564428017 N_PDU_18DA10F1 0;
BA_ "GenSigTimeoutTime_AGSM" SG_ 2564428017 N_PDU_18DA10F1 0;
BA_ "GenSigTimeoutTime_ASBS" SG_ 2564428017 N_PDU_18DA10F1 0;
BA_ "GenSigTimeoutTime_BCM" SG_ 2564428017 N_PDU_18DA10F1 0;
BA_ "GenSigTimeoutTime_BSM" SG_ 2564428017 N_PDU_18DA10F1 0;
BA_ "GenSigTimeoutTime_CADM" SG_ 2564428017 N_PDU_18DA10F1 0;
BA_ "GenSigTimeoutTime_DMSM" SG_ 2564428017 N_PDU_18DA10F1 0;
BA_ "GenSigTimeoutTime_DTCM" SG_ 2564428017 N_PDU_18DA10F1 0;
BA_ "GenSigTimeoutTime_ECM" SG_ 2564428017 N_PDU_18DA10F1 0;
BA_ "GenSigTimeoutTime_ELSDM" SG_ 2564428017 N_PDU_18DA10F1 0;
BA_ "GenSigTimeoutTime_ESL" SG_ 2564428017 N_PDU_18DA10F1 0;
BA_ "GenSigTimeoutTime_GNMM" SG_ 2564428017 N_PDU_18DA10F1 0;
BA_ "GenSigTimeoutTime_HCP" SG_ 2564428017 N_PDU_18DA10F1 0;
BA_ "GenSigTimeoutTime_IPC" SG_ 2564428017 N_PDU_18DA10F1 0;
BA_ "GenSigTimeoutTime_RFHM" SG_ 2564428017 N_PDU_18DA10F1 0;
BA_ "GenSigTimeoutTime_SGW" SG_ 2564428017 N_PDU_18DA10F1 0;
BA_ "GenSigTimeoutTime_TCM" SG_ 2564428017 N_PDU_18DA10F1 0;
BA_ "GenSigTimeoutTime_ESL" SG_ 2651930624 Digit_01 0;
BA_ "GenSigTimeoutTime_ESL" SG_ 2651930624 Digit_02 0;
BA_ "GenSigTimeoutTime_ESL" SG_ 2651930624 Digit_03 0;
BA_ "GenSigTimeoutTime_ESL" SG_ 2651930624 Digit_04 0;
BA_ "GenSigTimeoutTime_ESL" SG_ 2651930624 Digit_05 0;
BA_ "GenSigTimeoutTime_ESL" SG_ 2651930624 Digit_06 0;
BA_ "GenSigTimeoutTime_ESL" SG_ 2651930624 Digit_07 0;
BA_ "GenSigTimeoutTime_ESL" SG_ 2651930624 Digit_08 0;
BA_ "GenSigTimeoutTime_ESL" SG_ 2651930624 Digit_09 0;
BA_ "GenSigTimeoutTime_ESL" SG_ 2651930624 Digit_10 0;
BA_ "GenSigTimeoutTime_ESL" SG_ 2651930624 Digit_11 0;
BA_ "GenSigTimeoutTime_BCM" SG_ 2651930624 Digit_01 0;
BA_ "GenSigTimeoutTime_BCM" SG_ 2651930624 Digit_02 0;
BA_ "GenSigTimeoutTime_BCM" SG_ 2651930624 Digit_03 0;
BA_ "GenSigTimeoutTime_BCM" SG_ 2651930624 Digit_04 0;
BA_ "GenSigTimeoutTime_BCM" SG_ 2651930624 Digit_05 0;
BA_ "GenSigTimeoutTime_BCM" SG_ 2651930624 Digit_06 0;
BA_ "GenSigTimeoutTime_BCM" SG_ 2651930624 Digit_07 0;
BA_ "GenSigTimeoutTime_BCM" SG_ 2651930624 Digit_08 0;
BA_ "GenSigTimeoutTime_BCM" SG_ 2651930624 Digit_09 0;
BA_ "GenSigTimeoutTime_BCM" SG_ 2651930624 Digit_10 0;
BA_ "GenSigTimeoutTime_BCM" SG_ 2651930624 Digit_11 0;
BA_ "GenSigTimeoutTime_ADCAM" SG_ 100 ControlEncodingReq 0;
BA_ "GenSigTimeoutTime_EVCU2" SG_ 100 ControlEncodingReq 0;
BA_ "GenSigTimeoutTime_VDCM" SG_ 100 ControlEncodingReq 0;
BA_ "GenSigTimeoutTime_ADCAM" SG_ 100 f1_1 0;
BA_ "GenSigTimeoutTime_EVCU2" SG_ 100 f1_1 0;
BA_ "GenSigTimeoutTime_VDCM" SG_ 100 f1_1 0;
BA_ "GenSigTimeoutTime_ADCAM" SG_ 100 f1_2 0;
BA_ "GenSigTimeoutTime_EVCU2" SG_ 100 f1_2 0;
BA_ "GenSigTimeoutTime_VDCM" SG_ 100 f1_2 0;
BA_ "GenSigTimeoutTime_ADCAM" SG_ 100 rnd_1 0;
BA_ "GenSigTimeoutTime_EVCU2" SG_ 100 rnd_1 0;
BA_ "GenSigTimeoutTime_VDCM" SG_ 100 rnd_1 0;
BA_ "GenSigTimeoutTime_ADCAM" SG_ 100 rnd_2 0;
BA_ "GenSigTimeoutTime_EVCU2" SG_ 100 rnd_2 0;
BA_ "GenSigTimeoutTime_VDCM" SG_ 100 rnd_2 0;
BA_ "GenSigTimeoutTime_ADCAM" SG_ 100 rnd_3 0;
BA_ "GenSigTimeoutTime_EVCU2" SG_ 100 rnd_3 0;
BA_ "GenSigTimeoutTime_VDCM" SG_ 100 rnd_3 0;
BA_ "GenSigTimeoutTime_ADCAM" SG_ 100 rnd_4 0;
BA_ "GenSigTimeoutTime_EVCU2" SG_ 100 rnd_4 0;
BA_ "GenSigTimeoutTime_VDCM" SG_ 100 rnd_4 0;
BA_ "GenSigSendType" SG_ 100 ControlEncodingReq 1;
BA_ "GenSigTimeoutTime_AGSM" SG_ 100 ControlEncodingReq 0;
BA_ "GenSigTimeoutTime_ASBS" SG_ 100 ControlEncodingReq 0;
BA_ "GenSigTimeoutTime_BSM" SG_ 100 ControlEncodingReq 0;
BA_ "GenSigTimeoutTime_CADM" SG_ 100 ControlEncodingReq 0;
BA_ "GenSigTimeoutTime_DMSM" SG_ 100 ControlEncodingReq 0;
BA_ "GenSigTimeoutTime_DTCM" SG_ 100 ControlEncodingReq 0;
BA_ "GenSigTimeoutTime_ECM" SG_ 100 ControlEncodingReq 0;
BA_ "GenSigTimeoutTime_ELSDM" SG_ 100 ControlEncodingReq 0;
BA_ "GenSigTimeoutTime_ESL" SG_ 100 ControlEncodingReq 0;
BA_ "GenSigTimeoutTime_GNMM" SG_ 100 ControlEncodingReq 0;
BA_ "GenSigTimeoutTime_HCP" SG_ 100 ControlEncodingReq 0;
BA_ "GenSigTimeoutTime_IPC" SG_ 100 ControlEncodingReq 0;
BA_ "GenSigTimeoutTime_RFHM" SG_ 100 ControlEncodingReq 0;
BA_ "GenSigTimeoutTime_SGW" SG_ 100 ControlEncodingReq 0;
BA_ "GenSigTimeoutTime_TCM" SG_ 100 ControlEncodingReq 0;
BA_ "GenSigTimeoutTime_AGSM" SG_ 100 f1_1 0;
BA_ "GenSigTimeoutTime_ASBS" SG_ 100 f1_1 0;
BA_ "GenSigTimeoutTime_BSM" SG_ 100 f1_1 0;
BA_ "GenSigTimeoutTime_CADM" SG_ 100 f1_1 0;
BA_ "GenSigTimeoutTime_DMSM" SG_ 100 f1_1 0;
BA_ "GenSigTimeoutTime_DTCM" SG_ 100 f1_1 0;
BA_ "GenSigTimeoutTime_ECM" SG_ 100 f1_1 0;
BA_ "GenSigTimeoutTime_ELSDM" SG_ 100 f1_1 0;
BA_ "GenSigTimeoutTime_ESL" SG_ 100 f1_1 0;
BA_ "GenSigTimeoutTime_GNMM" SG_ 100 f1_1 0;
BA_ "GenSigTimeoutTime_HCP" SG_ 100 f1_1 0;
BA_ "GenSigTimeoutTime_IPC" SG_ 100 f1_1 0;
BA_ "GenSigTimeoutTime_RFHM" SG_ 100 f1_1 0;
BA_ "GenSigTimeoutTime_SGW" SG_ 100 f1_1 0;
BA_ "GenSigTimeoutTime_TCM" SG_ 100 f1_1 0;
BA_ "GenSigTimeoutTime_AGSM" SG_ 100 f1_2 0;
BA_ "GenSigTimeoutTime_ASBS" SG_ 100 f1_2 0;
BA_ "GenSigTimeoutTime_BSM" SG_ 100 f1_2 0;
BA_ "GenSigTimeoutTime_CADM" SG_ 100 f1_2 0;
BA_ "GenSigTimeoutTime_DMSM" SG_ 100 f1_2 0;
BA_ "GenSigTimeoutTime_DTCM" SG_ 100 f1_2 0;
BA_ "GenSigTimeoutTime_ECM" SG_ 100 f1_2 0;
BA_ "GenSigTimeoutTime_ELSDM" SG_ 100 f1_2 0;
BA_ "GenSigTimeoutTime_ESL" SG_ 100 f1_2 0;
BA_ "GenSigTimeoutTime_GNMM" SG_ 100 f1_2 0;
BA_ "GenSigTimeoutTime_HCP" SG_ 100 f1_2 0;
BA_ "GenSigTimeoutTime_IPC" SG_ 100 f1_2 0;
BA_ "GenSigTimeoutTime_RFHM" SG_ 100 f1_2 0;
BA_ "GenSigTimeoutTime_SGW" SG_ 100 f1_2 0;
BA_ "GenSigTimeoutTime_TCM" SG_ 100 f1_2 0;
BA_ "GenSigTimeoutTime_AGSM" SG_ 100 rnd_1 0;
BA_ "GenSigTimeoutTime_ASBS" SG_ 100 rnd_1 0;
BA_ "GenSigTimeoutTime_BSM" SG_ 100 rnd_1 0;
BA_ "GenSigTimeoutTime_CADM" SG_ 100 rnd_1 0;
BA_ "GenSigTimeoutTime_DMSM" SG_ 100 rnd_1 0;
BA_ "GenSigTimeoutTime_DTCM" SG_ 100 rnd_1 0;
BA_ "GenSigTimeoutTime_ECM" SG_ 100 rnd_1 0;
BA_ "GenSigTimeoutTime_ELSDM" SG_ 100 rnd_1 0;
BA_ "GenSigTimeoutTime_ESL" SG_ 100 rnd_1 0;
BA_ "GenSigTimeoutTime_GNMM" SG_ 100 rnd_1 0;
BA_ "GenSigTimeoutTime_HCP" SG_ 100 rnd_1 0;
BA_ "GenSigTimeoutTime_IPC" SG_ 100 rnd_1 0;
BA_ "GenSigTimeoutTime_RFHM" SG_ 100 rnd_1 0;
BA_ "GenSigTimeoutTime_SGW" SG_ 100 rnd_1 0;
BA_ "GenSigTimeoutTime_TCM" SG_ 100 rnd_1 0;
BA_ "GenSigTimeoutTime_AGSM" SG_ 100 rnd_2 0;
BA_ "GenSigTimeoutTime_ASBS" SG_ 100 rnd_2 0;
BA_ "GenSigTimeoutTime_BSM" SG_ 100 rnd_2 0;
BA_ "GenSigTimeoutTime_CADM" SG_ 100 rnd_2 0;
BA_ "GenSigTimeoutTime_DMSM" SG_ 100 rnd_2 0;
BA_ "GenSigTimeoutTime_DTCM" SG_ 100 rnd_2 0;
BA_ "GenSigTimeoutTime_ECM" SG_ 100 rnd_2 0;
BA_ "GenSigTimeoutTime_ELSDM" SG_ 100 rnd_2 0;
BA_ "GenSigTimeoutTime_ESL" SG_ 100 rnd_2 0;
BA_ "GenSigTimeoutTime_GNMM" SG_ 100 rnd_2 0;
BA_ "GenSigTimeoutTime_HCP" SG_ 100 rnd_2 0;
BA_ "GenSigTimeoutTime_IPC" SG_ 100 rnd_2 0;
BA_ "GenSigTimeoutTime_RFHM" SG_ 100 rnd_2 0;
BA_ "GenSigTimeoutTime_SGW" SG_ 100 rnd_2 0;
BA_ "GenSigTimeoutTime_TCM" SG_ 100 rnd_2 0;
BA_ "GenSigTimeoutTime_AGSM" SG_ 100 rnd_3 0;
BA_ "GenSigTimeoutTime_ASBS" SG_ 100 rnd_3 0;
BA_ "GenSigTimeoutTime_BSM" SG_ 100 rnd_3 0;
BA_ "GenSigTimeoutTime_CADM" SG_ 100 rnd_3 0;
BA_ "GenSigTimeoutTime_DMSM" SG_ 100 rnd_3 0;
BA_ "GenSigTimeoutTime_ADCAM" SG_ 519 CRC_RFHUB1 0;
BA_ "GenSigTimeoutTime_VDCM" SG_ 519 CRC_RFHUB1 0;
BA_ "GenSigTimeoutTime_AGSM" SG_ 519 CRC_RFHUB1 0;
BA_ "GenSigTimeoutTime_BCM" SG_ 519 CRC_RFHUB1 0;
BA_ "GenSigTimeoutTime_BSM" SG_ 519 CRC_RFHUB1 0;
BA_ "GenSigTimeoutTime_DTCM" SG_ 519 CRC_RFHUB1 0;
BA_ "GenSigTimeoutTime_ESL" SG_ 519 CRC_RFHUB1 0;
BA_ "GenSigTimeoutTime_IPC" SG_ 519 CRC_RFHUB1 0;
BA_ "GenSigTimeoutTime_RFHM" SG_ 519 CRC_RFHUB1 0;
BA_ "GenSigTimeoutTime_SGW" SG_ 519 CRC_RFHUB1 0;
BA_ "GenSigTimeoutTime_ADCAM" SG_ 519 MessageCounter_RFHUB1 0;
BA_ "GenSigTimeoutTime_VDCM" SG_ 519 MessageCounter_RFHUB1 0;
BA_ "GenSigTimeoutTime_AGSM" SG_ 519 MessageCounter_RFHUB1 0;
BA_ "GenSigTimeoutTime_BCM" SG_ 519 MessageCounter_RFHUB1 0;
BA_ "GenSigTimeoutTime_BSM" SG_ 519 MessageCounter_RFHUB1 0;
BA_ "GenSigTimeoutTime_DTCM" SG_ 519 MessageCounter_RFHUB1 0;
BA_ "GenSigTimeoutTime_ESL" SG_ 519 MessageCounter_RFHUB1 0;
BA_ "GenSigTimeoutTime_IPC" SG_ 519 MessageCounter_RFHUB1 0;
BA_ "GenSigTimeoutTime_RFHM" SG_ 519 MessageCounter_RFHUB1 0;
BA_ "GenSigTimeoutTime_SGW" SG_ 519 MessageCounter_RFHUB1 0;
BA_ "GenSigTimeoutTime_ADCAM" SG_ 519 IgnPosSts 0;
BA_ "GenSigTimeoutTime_EVCU2" SG_ 519 IgnPosSts 0;
BA_ "GenSigTimeoutTime_VDCM" SG_ 519 IgnPosSts 0;
BA_ "GenSigTimeoutTime_AGSM" SG_ 519 IgnPosSts 0;
BA_ "GenSigTimeoutTime_BSM" SG_ 519 IgnPosSts 0;
BA_ "GenSigTimeoutTime_DTCM" SG_ 519 IgnPosSts 0;
BA_ "GenSigTimeoutTime_ESL" SG_ 519 IgnPosSts 0;
BA_ "GenSigTimeoutTime_IPC" SG_ 519 IgnPosSts 0;
BA_ "GenSigTimeoutTime_RFHM" SG_ 519 IgnPosSts 0;
BA_ "GenSigTimeoutTime_TCM" SG_ 519 IgnPosSts 0;
BA_ "GenSigTimeoutTime_ADCAM" SG_ 1428 GlobDrvMdRq 0;
BA_ "GenSigTimeoutTime_VDCM" SG_ 1428 GlobDrvMdRq 0;
BA_ "GenSigSendType" SG_ 1428 GlobDrvMdRq 3;
BA_ "GenSigTimeoutTime_AGSM" SG_ 1428 GlobDrvMdRq 0;
BA_ "GenSigTimeoutTime_BCM" SG_ 1428 GlobDrvMdRq 0;
BA_ "GenSigTimeoutTime_BSM" SG_ 1428 GlobDrvMdRq 0;
BA_ "GenSigTimeoutTime_ESL" SG_ 1428 GlobDrvMdRq 0;
BA_ "GenSigTimeoutTime_IPC" SG_ 1428 GlobDrvMdRq 0;
BA_ "GenSigTimeoutTime_RFHM" SG_ 1428 GlobDrvMdRq 0;
BA_ "GenSigTimeoutTime_SGW" SG_ 1428 GlobDrvMdRq 0;
BA_ "GenSigTimeoutTime_TCM" SG_ 1428 GlobDrvMdRq 0;
BA_ "GenSigTimeoutTime_DTCM" SG_ 100 rnd_3 0;
BA_ "GenSigTimeoutTime_ECM" SG_ 100 rnd_3 0;
BA_ "GenSigTimeoutTime_ELSDM" SG_ 100 rnd_3 0;
BA_ "GenSigTimeoutTime_ESL" SG_ 100 rnd_3 0;
BA_ "GenSigTimeoutTime_GNMM" SG_ 100 rnd_3 0;
BA_ "GenSigTimeoutTime_HCP" SG_ 100 rnd_3 0;
BA_ "GenSigTimeoutTime_IPC" SG_ 100 rnd_3 0;
BA_ "GenSigTimeoutTime_RFHM" SG_ 100 rnd_3 0;
BA_ "GenSigTimeoutTime_SGW" SG_ 100 rnd_3 0;
BA_ "GenSigTimeoutTime_TCM" SG_ 100 rnd_3 0;
BA_ "GenSigTimeoutTime_AGSM" SG_ 100 rnd_4 0;
BA_ "GenSigTimeoutTime_ASBS" SG_ 100 rnd_4 0;
BA_ "GenSigTimeoutTime_BSM" SG_ 100 rnd_4 0;
BA_ "GenSigTimeoutTime_CADM" SG_ 100 rnd_4 0;
BA_ "GenSigTimeoutTime_DMSM" SG_ 100 rnd_4 0;
BA_ "GenSigTimeoutTime_DTCM" SG_ 100 rnd_4 0;
BA_ "GenSigTimeoutTime_ECM" SG_ 100 rnd_4 0;
BA_ "GenSigTimeoutTime_ELSDM" SG_ 100 rnd_4 0;
BA_ "GenSigTimeoutTime_ESL" SG_ 100 rnd_4 0;
BA_ "GenSigTimeoutTime_GNMM" SG_ 100 rnd_4 0;
BA_ "GenSigTimeoutTime_HCP" SG_ 100 rnd_4 0;
BA_ "GenSigTimeoutTime_IPC" SG_ 100 rnd_4 0;
BA_ "GenSigTimeoutTime_RFHM" SG_ 100 rnd_4 0;
BA_ "GenSigTimeoutTime_SGW" SG_ 100 rnd_4 0;
BA_ "GenSigTimeoutTime_TCM" SG_ 100 rnd_4 0;
BA_ "GenSigTimeoutTime_ADCAM" SG_ 1058 AccelPdlPosn_OBD 0;
BA_ "GenSigTimeoutTime_EVCU2" SG_ 1058 AccelPdlPosn_OBD 0;
BA_ "GenSigTimeoutTime_VDCM" SG_ 1058 AccelPdlPosn_OBD 0;
BA_ "GenSigTimeoutTime_SGW" SG_ 1058 AccelPdlPosn_OBD 0;
BA_ "GenSigTimeoutTime_TCM" SG_ 1058 AccelPdlPosn_OBD 0;
BA_ "GenSigTimeoutTime_ADCAM" SG_ 1058 CARB_PERM 0;
BA_ "GenSigTimeoutTime_EVCU2" SG_ 1058 CARB_PERM 0;
BA_ "GenSigTimeoutTime_VDCM" SG_ 1058 CARB_PERM 0;
BA_ "GenSigTimeoutTime_TCM" SG_ 1058 CARB_PERM 0;
BA_ "GenSigTimeoutTime_ADCAM" SG_ 1058 CarbWarmUp 0;
BA_ "GenSigTimeoutTime_VDCM" SG_ 1058 CarbWarmUp 0;
BA_ "GenSigTimeoutTime_TCM" SG_ 1058 CarbWarmUp 0;
BA_ "GenSigTimeoutTime_ADCAM" SG_ 1058 CldStrtDenominator 0;
BA_ "GenSigTimeoutTime_EVCU2" SG_ 1058 CldStrtDenominator 0;
BA_ "GenSigTimeoutTime_VDCM" SG_ 1058 CldStrtDenominator 0;
BA_ "GenSigTimeoutTime_ADCAM" SG_ 1058 LgsDiagCldStrtCndFltPr 0;
BA_ "GenSigTimeoutTime_VDCM" SG_ 1058 LgsDiagCldStrtCndFltPr 0;
BA_ "GenSigTimeoutTime_ADCAM" SG_ 1058 LgsDiagCldStrtCndMet 0;
BA_ "GenSigTimeoutTime_VDCM" SG_ 1058 LgsDiagCldStrtCndMet 0;
BA_ "GenSigTimeoutTime_ADCAM" SG_ 1058 MessageCounter_OBDCONTENTFRAME 0;
BA_ "GenSigTimeoutTime_EVCU2" SG_ 1058 MessageCounter_OBDCONTENTFRAME 0;
BA_ "GenSigTimeoutTime_VDCM" SG_ 1058 MessageCounter_OBDCONTENTFRAME 0;
BA_ "GenSigTimeoutTime_TCM" SG_ 1058 MessageCounter_OBDCONTENTFRAME 0;
BA_ "GenSigTimeoutTime_ADCAM" SG_ 1058 CRC_OBDCONTENTFRAME 0;
BA_ "GenSigTimeoutTime_EVCU2" SG_ 1058 CRC_OBDCONTENTFRAME 0;
BA_ "GenSigTimeoutTime_VDCM" SG_ 1058 CRC_OBDCONTENTFRAME 0;
BA_ "GenSigTimeoutTime_TCM" SG_ 1058 CRC_OBDCONTENTFRAME 0;
BA_ "GenSigTimeoutTime_ADCAM" SG_ 1058 EngineOFFTime 0;
BA_ "GenSigTimeoutTime_EVCU2" SG_ 1058 EngineOFFTime 0;
BA_ "GenSigTimeoutTime_VDCM" SG_ 1058 EngineOFFTime 0;
BA_ "GenSigTimeoutTime_TCM" SG_ 1058 EngineOFFTime 0;
BA_ "GenSigTimeoutTime_ECM" SG_ 1058 EstCatCnvTmp 0;
BA_ "GenSigTimeoutTime_ELSDM" SG_ 1058 EstCatCnvTmp 0;
BA_ "GenSigTimeoutTime_ESL" SG_ 1058 EstCatCnvTmp 0;
BA_ "GenSigTimeoutTime_GNMM" SG_ 1058 EstCatCnvTmp 0;
BA_ "GenSigTimeoutTime_IPC" SG_ 1058 EstCatCnvTmp 0;
BA_ "GenSigTimeoutTime_RFHM" SG_ 1058 EstCatCnvTmp 0;
BA_ "GenSigTimeoutTime_SGW" SG_ 1058 EstCatCnvTmp 0;
BA_ "GenSigTimeoutTime_TCM" SG_ 1058 EstCatCnvTmp 0;
BA_ "GenSigTimeoutTime_AGSM" SG_ 1058 IgnCntrFuelEngTrue 0;
BA_ "GenSigTimeoutTime_ASBS" SG_ 1058 IgnCntrFuelEngTrue 0;
BA_ "GenSigTimeoutTime_BCM" SG_ 1058 IgnCntrFuelEngTrue 0;
BA_ "GenSigTimeoutTime_BSM" SG_ 1058 IgnCntrFuelEngTrue 0;
BA_ "GenSigTimeoutTime_CADM" SG_ 1058 IgnCntrFuelEngTrue 0;
BA_ "GenSigTimeoutTime_DMSM" SG_ 1058 IgnCntrFuelEngTrue 0;
BA_ "GenSigTimeoutTime_DTCM" SG_ 1058 IgnCntrFuelEngTrue 0;
BA_ "GenSigTimeoutTime_ECM" SG_ 1058 IgnCntrFuelEngTrue 0;
BA_ "GenSigTimeoutTime_ELSDM" SG_ 1058 IgnCntrFuelEngTrue 0;
BA_ "GenSigTimeoutTime_ESL" SG_ 1058 IgnCntrFuelEngTrue 0;
BA_ "GenSigTimeoutTime_GNMM" SG_ 1058 IgnCntrFuelEngTrue 0;
BA_ "GenSigTimeoutTime_IPC" SG_ 1058 IgnCntrFuelEngTrue 0;
BA_ "GenSigTimeoutTime_RFHM" SG_ 1058 IgnCntrFuelEngTrue 0;
BA_ "GenSigTimeoutTime_SGW" SG_ 1058 IgnCntrFuelEngTrue 0;
BA_ "GenSigTimeoutTime_TCM" SG_ 1058 IgnCntrFuelEngTrue 0;
BA_ "GenSigTimeoutTime_AGSM" SG_ 1058 BarPrsAbs 0;
BA_ "GenSigTimeoutTime_ASBS" SG_ 1058 BarPrsAbs 0;
BA_ "GenSigTimeoutTime_BCM" SG_ 1058 BarPrsAbs 0;
BA_ "GenSigTimeoutTime_BSM" SG_ 1058 BarPrsAbs 0;
BA_ "GenSigTimeoutTime_CADM" SG_ 1058 BarPrsAbs 0;
BA_ "GenSigTimeoutTime_DMSM" SG_ 1058 BarPrsAbs 0;
BA_ "GenSigTimeoutTime_DTCM" SG_ 1058 BarPrsAbs 0;
BA_ "GenSigTimeoutTime_ECM" SG_ 1058 BarPrsAbs 0;
BA_ "GenSigTimeoutTime_ELSDM" SG_ 1058 BarPrsAbs 0;
BA_ "GenSigTimeoutTime_ESL" SG_ 1058 BarPrsAbs 0;
BA_ "GenSigTimeoutTime_GNMM" SG_ 1058 BarPrsAbs 0;
BA_ "GenSigTimeoutTime_IPC" SG_ 1058 BarPrsAbs 0;
BA_ "GenSigTimeoutTime_RFHM" SG_ 1058 BarPrsAbs 0;
BA_ "GenSigTimeoutTime_SGW" SG_ 1058 BarPrsAbs 0;
BA_ "GenSigTimeoutTime_TCM" SG_ 1058 BarPrsAbs 0;
BA_ "GenSigTimeoutTime_AGSM" SG_ 1058 BarPrsAbsV 0;
BA_ "GenSigTimeoutTime_ASBS" SG_ 1058 BarPrsAbsV 0;
BA_ "GenSigTimeoutTime_BCM" SG_ 1058 BarPrsAbsV 0;
BA_ "GenSigTimeoutTime_BSM" SG_ 1058 BarPrsAbsV 0;
BA_ "GenSigTimeoutTime_CADM" SG_ 1058 BarPrsAbsV 0;
BA_ "GenSigTimeoutTime_DMSM" SG_ 1058 BarPrsAbsV 0;
BA_ "GenSigTimeoutTime_DTCM" SG_ 1058 BarPrsAbsV 0;
BA_ "GenSigTimeoutTime_ECM" SG_ 1058 BarPrsAbsV 0;
BA_ "GenSigTimeoutTime_ELSDM" SG_ 1058 BarPrsAbsV 0;
BA_ "GenSigTimeoutTime_ESL" SG_ 1058 BarPrsAbsV 0;
BA_ "GenSigTimeoutTime_GNMM" SG_ 1058 BarPrsAbsV 0;
BA_ "GenSigTimeoutTime_IPC" SG_ 1058 BarPrsAbsV 0;
BA_ "GenSigTimeoutTime_RFHM" SG_ 1058 BarPrsAbsV 0;
BA_ "GenSigTimeoutTime_SGW" SG_ 1058 BarPrsAbsV 0;
BA_ "GenSigTimeoutTime_TCM" SG_ 1058 BarPrsAbsV 0;
BA_ "GenSigTimeoutTime_AGSM" SG_ 1058 ECM_HoodAjar 0;
BA_ "GenSigTimeoutTime_ASBS" SG_ 1058 ECM_HoodAjar 0;
BA_ "GenSigTimeoutTime_BCM" SG_ 1058 ECM_HoodAjar 0;
BA_ "GenSigTimeoutTime_BSM" SG_ 1058 ECM_HoodAjar 0;
BA_ "GenSigTimeoutTime_CADM" SG_ 1058 ECM_HoodAjar 0;
BA_ "GenSigTimeoutTime_DMSM" SG_ 1058 ECM_HoodAjar 0;
BA_ "GenSigTimeoutTime_DTCM" SG_ 1058 ECM_HoodAjar 0;
BA_ "GenSigTimeoutTime_ECM" SG_ 1058 ECM_HoodAjar 0;
BA_ "GenSigTimeoutTime_ELSDM" SG_ 1058 ECM_HoodAjar 0;
BA_ "GenSigTimeoutTime_ESL" SG_ 1058 ECM_HoodAjar 0;
BA_ "GenSigTimeoutTime_GNMM" SG_ 1058 ECM_HoodAjar 0;
BA_ "GenSigTimeoutTime_IPC" SG_ 1058 ECM_HoodAjar 0;
BA_ "GenSigTimeoutTime_RFHM" SG_ 1058 ECM_HoodAjar 0;
BA_ "GenSigTimeoutTime_SGW" SG_ 1058 ECM_HoodAjar 0;
BA_ "GenSigTimeoutTime_TCM" SG_ 1058 ECM_HoodAjar 0;
BA_ "GenSigTimeoutTime_AGSM" SG_ 1058 EngIntAirTmp 0;
BA_ "GenSigTimeoutTime_ASBS" SG_ 1058 EngIntAirTmp 0;
BA_ "GenSigTimeoutTime_BCM" SG_ 1058 EngIntAirTmp 0;
BA_ "GenSigTimeoutTime_BSM" SG_ 1058 EngIntAirTmp 0;
BA_ "GenSigTimeoutTime_CADM" SG_ 1058 EngIntAirTmp 0;
BA_ "GenSigTimeoutTime_DMSM" SG_ 1058 EngIntAirTmp 0;
BA_ "GenSigTimeoutTime_DTCM" SG_ 1058 EngIntAirTmp 0;
BA_ "GenSigTimeoutTime_ECM" SG_ 1058 EngIntAirTmp 0;
BA_ "GenSigTimeoutTime_ELSDM" SG_ 1058 EngIntAirTmp 0;
BA_ "GenSigTimeoutTime_ESL" SG_ 1058 EngIntAirTmp 0;
BA_ "GenSigTimeoutTime_GNMM" SG_ 1058 EngIntAirTmp 0;
BA_ "GenSigTimeoutTime_IPC" SG_ 1058 EngIntAirTmp 0;
BA_ "GenSigTimeoutTime_RFHM" SG_ 1058 EngIntAirTmp 0;
BA_ "GenSigTimeoutTime_SGW" SG_ 1058 EngIntAirTmp 0;
BA_ "GenSigTimeoutTime_TCM" SG_ 1058 EngIntAirTmp 0;
BA_ "GenSigTimeoutTime_AGSM" SG_ 1058 MessageCounter_OBDCONTENTFRAME 0;
BA_ "GenSigTimeoutTime_ASBS" SG_ 1058 MessageCounter_OBDCONTENTFRAME 0;
BA_ "GenSigTimeoutTime_BCM" SG_ 1058 MessageCounter_OBDCONTENTFRAME 0;
BA_ "GenSigTimeoutTime_CADM" SG_ 1058 MessageCounter_OBDCONTENTFRAME 0;
BA_ "GenSigTimeoutTime_DMSM" SG_ 1058 MessageCounter_OBDCONTENTFRAME 0;
BA_ "GenSigTimeoutTime_DTCM" SG_ 1058 MessageCounter_OBDCONTENTFRAME 0;
BA_ "GenSigTimeoutTime_ECM" SG_ 1058 MessageCounter_OBDCONTENTFRAME 0;
BA_ "GenSigTimeoutTime_ELSDM" SG_ 1058 MessageCounter_OBDCONTENTFRAME 0;
BA_ "GenSigTimeoutTime_ESL" SG_ 1058 MessageCounter_OBDCONTENTFRAME 0;
BA_ "GenSigTimeoutTime_GNMM" SG_ 1058 MessageCounter_OBDCONTENTFRAME 0;
BA_ "GenSigTimeoutTime_IPC" SG_ 1058 MessageCounter_OBDCONTENTFRAME 0;
BA_ "GenSigTimeoutTime_RFHM" SG_ 1058 MessageCounter_OBDCONTENTFRAME 0;
BA_ "GenSigTimeoutTime_SGW" SG_ 1058 MessageCounter_OBDCONTENTFRAME 0;
BA_ "GenSigTimeoutTime_AGSM" SG_ 1058 CRC_OBDCONTENTFRAME 0;
BA_ "GenSigTimeoutTime_ASBS" SG_ 1058 CRC_OBDCONTENTFRAME 0;
BA_ "GenSigTimeoutTime_BCM" SG_ 1058 CRC_OBDCONTENTFRAME 0;
BA_ "GenSigTimeoutTime_CADM" SG_ 1058 CRC_OBDCONTENTFRAME 0;
BA_ "GenSigTimeoutTime_DMSM" SG_ 1058 CRC_OBDCONTENTFRAME 0;
BA_ "GenSigTimeoutTime_DTCM" SG_ 1058 CRC_OBDCONTENTFRAME 0;
BA_ "GenSigTimeoutTime_ECM" SG_ 1058 CRC_OBDCONTENTFRAME 0;
BA_ "GenSigTimeoutTime_ELSDM" SG_ 1058 CRC_OBDCONTENTFRAME 0;
BA_ "GenSigTimeoutTime_ESL" SG_ 1058 CRC_OBDCONTENTFRAME 0;
BA_ "GenSigTimeoutTime_GNMM" SG_ 1058 CRC_OBDCONTENTFRAME 0;
BA_ "GenSigTimeoutTime_IPC" SG_ 1058 CRC_OBDCONTENTFRAME 0;
BA_ "GenSigTimeoutTime_RFHM" SG_ 1058 CRC_OBDCONTENTFRAME 0;
BA_ "GenSigTimeoutTime_SGW" SG_ 1058 CRC_OBDCONTENTFRAME 0;
BA_ "GenSigStartValue" SG_ 1058 EngineOFFTime 1023;
BA_ "GenSigTimeoutTime_AGSM" SG_ 1058 EngineOFFTime 0;
BA_ "GenSigTimeoutTime_ASBS" SG_ 1058 EngineOFFTime 0;
BA_ "GenSigTimeoutTime_BCM" SG_ 1058 EngineOFFTime 0;
BA_ "GenSigTimeoutTime_BSM" SG_ 1058 EngineOFFTime 0;
BA_ "GenSigTimeoutTime_CADM" SG_ 1058 EngineOFFTime 0;
BA_ "GenSigTimeoutTime_DMSM" SG_ 1058 EngineOFFTime 0;
BA_ "GenSigTimeoutTime_DTCM" SG_ 1058 EngineOFFTime 0;
BA_ "GenSigTimeoutTime_ECM" SG_ 1058 EngineOFFTime 0;
BA_ "GenSigTimeoutTime_ELSDM" SG_ 1058 EngineOFFTime 0;
BA_ "GenSigTimeoutTime_ESL" SG_ 1058 EngineOFFTime 0;
BA_ "GenSigTimeoutTime_GNMM" SG_ 1058 EngineOFFTime 0;
BA_ "GenSigTimeoutTime_HCP" SG_ 1058 EngineOFFTime 0;
BA_ "GenSigTimeoutTime_IPC" SG_ 1058 EngineOFFTime 0;
BA_ "GenSigTimeoutTime_RFHM" SG_ 1058 EngineOFFTime 0;
BA_ "GenSigTimeoutTime_SGW" SG_ 1058 EngineOFFTime 0;
BA_ "GenSigTimeoutTime_AGSM" SG_ 1058 GenDenominator 0;
BA_ "GenSigTimeoutTime_ASBS" SG_ 1058 GenDenominator 0;
BA_ "GenSigTimeoutTime_BCM" SG_ 1058 GenDenominator 0;
BA_ "GenSigTimeoutTime_BSM" SG_ 1058 GenDenominator 0;
BA_ "GenSigTimeoutTime_CADM" SG_ 1058 GenDenominator 0;
BA_ "GenSigTimeoutTime_DMSM" SG_ 1058 GenDenominator 0;
BA_ "GenSigTimeoutTime_DTCM" SG_ 1058 GenDenominator 0;
BA_ "GenSigTimeoutTime_ECM" SG_ 1058 GenDenominator 0;
BA_ "GenSigTimeoutTime_ELSDM" SG_ 1058 GenDenominator 0;
BA_ "GenSigTimeoutTime_ESL" SG_ 1058 GenDenominator 0;
BA_ "GenSigTimeoutTime_GNMM" SG_ 1058 GenDenominator 0;
BA_ "GenSigTimeoutTime_IPC" SG_ 1058 GenDenominator 0;
BA_ "GenSigTimeoutTime_RFHM" SG_ 1058 GenDenominator 0;
BA_ "GenSigTimeoutTime_SGW" SG_ 1058 GenDenominator 0;
BA_ "GenSigTimeoutTime_AGSM" SG_ 1058 IgnCntrTrue 0;
BA_ "GenSigTimeoutTime_ASBS" SG_ 1058 IgnCntrTrue 0;
BA_ "GenSigTimeoutTime_BCM" SG_ 1058 IgnCntrTrue 0;
BA_ "GenSigTimeoutTime_BSM" SG_ 1058 IgnCntrTrue 0;
BA_ "GenSigTimeoutTime_CADM" SG_ 1058 IgnCntrTrue 0;
BA_ "GenSigTimeoutTime_DMSM" SG_ 1058 IgnCntrTrue 0;
BA_ "GenSigTimeoutTime_DTCM" SG_ 1058 IgnCntrTrue 0;
BA_ "GenSigTimeoutTime_ECM" SG_ 1058 IgnCntrTrue 0;
BA_ "GenSigTimeoutTime_ELSDM" SG_ 1058 IgnCntrTrue 0;
BA_ "GenSigTimeoutTime_ESL" SG_ 1058 IgnCntrTrue 0;
BA_ "GenSigTimeoutTime_GNMM" SG_ 1058 IgnCntrTrue 0;
BA_ "GenSigTimeoutTime_IPC" SG_ 1058 IgnCntrTrue 0;
BA_ "GenSigTimeoutTime_RFHM" SG_ 1058 IgnCntrTrue 0;
BA_ "GenSigTimeoutTime_SGW" SG_ 1058 IgnCntrTrue 0;
BA_ "GenSigTimeoutTime_AGSM" SG_ 1058 Inp_ICC_Fail 0;
BA_ "GenSigTimeoutTime_ASBS" SG_ 1058 Inp_ICC_Fail 0;
BA_ "GenSigTimeoutTime_BCM" SG_ 1058 Inp_ICC_Fail 0;
BA_ "GenSigTimeoutTime_BSM" SG_ 1058 Inp_ICC_Fail 0;
BA_ "GenSigTimeoutTime_CADM" SG_ 1058 Inp_ICC_Fail 0;
BA_ "GenSigTimeoutTime_DMSM" SG_ 1058 Inp_ICC_Fail 0;
BA_ "GenSigTimeoutTime_DTCM" SG_ 1058 Inp_ICC_Fail 0;
BA_ "GenSigTimeoutTime_ECM" SG_ 1058 Inp_ICC_Fail 0;
BA_ "GenSigTimeoutTime_ELSDM" SG_ 1058 Inp_ICC_Fail 0;
BA_ "GenSigTimeoutTime_ESL" SG_ 1058 Inp_ICC_Fail 0;
BA_ "GenSigTimeoutTime_GNMM" SG_ 1058 Inp_ICC_Fail 0;
BA_ "GenSigTimeoutTime_IPC" SG_ 1058 Inp_ICC_Fail 0;
BA_ "GenSigTimeoutTime_RFHM" SG_ 1058 Inp_ICC_Fail 0;
BA_ "GenSigTimeoutTime_SGW" SG_ 1058 Inp_ICC_Fail 0;
BA_ "GenSigTimeoutTime_AGSM" SG_ 1058 InputsGDFail 0;
BA_ "GenSigTimeoutTime_ASBS" SG_ 1058 InputsGDFail 0;
BA_ "GenSigTimeoutTime_BCM" SG_ 1058 InputsGDFail 0;
BA_ "GenSigTimeoutTime_BSM" SG_ 1058 InputsGDFail 0;
BA_ "GenSigTimeoutTime_CADM" SG_ 1058 InputsGDFail 0;
BA_ "GenSigTimeoutTime_DMSM" SG_ 1058 InputsGDFail 0;
BA_ "GenSigTimeoutTime_DTCM" SG_ 1058 InputsGDFail 0;
BA_ "GenSigTimeoutTime_ECM" SG_ 1058 InputsGDFail 0;
BA_ "GenSigTimeoutTime_ELSDM" SG_ 1058 InputsGDFail 0;
BA_ "GenSigTimeoutTime_ESL" SG_ 1058 InputsGDFail 0;
BA_ "GenSigTimeoutTime_GNMM" SG_ 1058 InputsGDFail 0;
BA_ "GenSigTimeoutTime_HCP" SG_ 1058 InputsGDFail 0;
BA_ "GenSigTimeoutTime_IPC" SG_ 1058 InputsGDFail 0;
BA_ "GenSigTimeoutTime_RFHM" SG_ 1058 InputsGDFail 0;
BA_ "GenSigTimeoutTime_SGW" SG_ 1058 InputsGDFail 0;
BA_ "GenSigTimeoutTime_AGSM" SG_ 1058 LoadOBD 0;
BA_ "GenSigTimeoutTime_ASBS" SG_ 1058 LoadOBD 0;
BA_ "GenSigTimeoutTime_BCM" SG_ 1058 LoadOBD 0;
BA_ "GenSigTimeoutTime_CADM" SG_ 1058 LoadOBD 0;
BA_ "GenSigTimeoutTime_DMSM" SG_ 1058 LoadOBD 0;
BA_ "GenSigTimeoutTime_DTCM" SG_ 1058 LoadOBD 0;
BA_ "GenSigTimeoutTime_ECM" SG_ 1058 LoadOBD 0;
BA_ "GenSigTimeoutTime_ELSDM" SG_ 1058 LoadOBD 0;
BA_ "GenSigTimeoutTime_ESL" SG_ 1058 LoadOBD 0;
BA_ "GenSigTimeoutTime_GNMM" SG_ 1058 LoadOBD 0;
BA_ "GenSigTimeoutTime_IPC" SG_ 1058 LoadOBD 0;
BA_ "GenSigTimeoutTime_RFHM" SG_ 1058 LoadOBD 0;
BA_ "GenSigTimeoutTime_ADCAM" SG_ 2564485392 N_PDU_18DAF110 0;
BA_ "GenSigTimeoutTime_EVCU2" SG_ 2564485392 N_PDU_18DAF110 0;
BA_ "GenSigTimeoutTime_VDCM" SG_ 2564485392 N_PDU_18DAF110 0;
BA_ "GenSigTimeoutTime_AGSM" SG_ 2564485392 N_PDU_18DAF110 0;
BA_ "GenSigTimeoutTime_ASBS" SG_ 2564485392 N_PDU_18DAF110 0;
BA_ "GenSigTimeoutTime_BCM" SG_ 2564485392 N_PDU_18DAF110 0;
BA_ "GenSigTimeoutTime_BSM" SG_ 2564485392 N_PDU_18DAF110 0;
BA_ "GenSigTimeoutTime_CADM" SG_ 2564485392 N_PDU_18DAF110 0;
BA_ "GenSigTimeoutTime_DMSM" SG_ 2564485392 N_PDU_18DAF110 0;
BA_ "GenSigTimeoutTime_DTCM" SG_ 2564485392 N_PDU_18DAF110 0;
BA_ "GenSigTimeoutTime_ECM" SG_ 2564485392 N_PDU_18DAF110 0;
BA_ "GenSigTimeoutTime_ELSDM" SG_ 2564485392 N_PDU_18DAF110 0;
BA_ "GenSigTimeoutTime_ESL" SG_ 2564485392 N_PDU_18DAF110 0;
BA_ "GenSigTimeoutTime_GNMM" SG_ 2564485392 N_PDU_18DAF110 0;
BA_ "GenSigTimeoutTime_HCP" SG_ 2564485392 N_PDU_18DAF110 0;
BA_ "GenSigTimeoutTime_IPC" SG_ 2564485392 N_PDU_18DAF110 0;
BA_ "GenSigTimeoutTime_RFHM" SG_ 2564485392 N_PDU_18DAF110 0;
BA_ "GenSigTimeoutTime_SGW" SG_ 2564485392 N_PDU_18DAF110 0;
BA_ "GenSigTimeoutTime_TCM" SG_ 2564485392 N_PDU_18DAF110 0;
BA_ "GenSigTimeoutTime_ADCAM" SG_ 2651930625 Digit_01_ECM 0;
BA_ "GenSigTimeoutTime_EVCU2" SG_ 2651930625 Digit_01_ECM 0;
BA_ "GenSigTimeoutTime_VDCM" SG_ 2651930625 Digit_01_ECM 0;
BA_ "GenSigTimeoutTime_ADCAM" SG_ 2651930625 Digit_02_ECM 0;
BA_ "GenSigTimeoutTime_EVCU2" SG_ 2651930625 Digit_02_ECM 0;
BA_ "GenSigTimeoutTime_VDCM" SG_ 2651930625 Digit_02_ECM 0;
BA_ "GenSigTimeoutTime_ADCAM" SG_ 2651930625 Digit_03_ECM 0;
BA_ "GenSigTimeoutTime_EVCU2" SG_ 2651930625 Digit_03_ECM 0;
BA_ "GenSigTimeoutTime_VDCM" SG_ 2651930625 Digit_03_ECM 0;
BA_ "GenSigTimeoutTime_ADCAM" SG_ 2651930625 Digit_04_ECM 0;
BA_ "GenSigTimeoutTime_EVCU2" SG_ 2651930625 Digit_04_ECM 0;
BA_ "GenSigTimeoutTime_VDCM" SG_ 2651930625 Digit_04_ECM 0;
BA_ "GenSigTimeoutTime_ADCAM" SG_ 2651930625 Digit_05_ECM 0;
BA_ "GenSigTimeoutTime_EVCU2" SG_ 2651930625 Digit_05_ECM 0;
BA_ "GenSigTimeoutTime_VDCM" SG_ 2651930625 Digit_05_ECM 0;
BA_ "GenSigTimeoutTime_ADCAM" SG_ 2651930625 Digit_06_ECM 0;
BA_ "GenSigTimeoutTime_EVCU2" SG_ 2651930625 Digit_06_ECM 0;
BA_ "GenSigTimeoutTime_VDCM" SG_ 2651930625 Digit_06_ECM 0;
BA_ "GenSigTimeoutTime_ADCAM" SG_ 2651930625 Digit_07_ECM 0;
BA_ "GenSigTimeoutTime_EVCU2" SG_ 2651930625 Digit_07_ECM 0;
BA_ "GenSigTimeoutTime_VDCM" SG_ 2651930625 Digit_07_ECM 0;
BA_ "GenSigTimeoutTime_ADCAM" SG_ 2651930625 Digit_08_ECM 0;
BA_ "GenSigTimeoutTime_EVCU2" SG_ 2651930625 Digit_08_ECM 0;
BA_ "GenSigTimeoutTime_VDCM" SG_ 2651930625 Digit_08_ECM 0;
BA_ "GenSigTimeoutTime_ADCAM" SG_ 2651930625 Digit_09_ECM 0;
BA_ "GenSigTimeoutTime_EVCU2" SG_ 2651930625 Digit_09_ECM 0;
BA_ "GenSigTimeoutTime_VDCM" SG_ 2651930625 Digit_09_ECM 0;
BA_ "GenSigTimeoutTime_ADCAM" SG_ 2651930625 Digit_10_ECM 0;
BA_ "GenSigTimeoutTime_EVCU2" SG_ 2651930625 Digit_10_ECM 0;
BA_ "GenSigTimeoutTime_VDCM" SG_ 2651930625 Digit_10_ECM 0;
BA_ "GenSigTimeoutTime_ADCAM" SG_ 2651930625 Digit_11_ECM 0;
BA_ "GenSigTimeoutTime_EVCU2" SG_ 2651930625 Digit_11_ECM 0;
BA_ "GenSigTimeoutTime_VDCM" SG_ 2651930625 Digit_11_ECM 0;
BA_ "GenSigSendType" SG_ 2651930625 Digit_01_ECM 1;
BA_ "GenSigTimeoutTime_AGSM" SG_ 2651930625 Digit_01_ECM 0;
BA_ "GenSigTimeoutTime_ASBS" SG_ 2651930625 Digit_01_ECM 0;
BA_ "GenSigTimeoutTime_BSM" SG_ 2651930625 Digit_01_ECM 0;
BA_ "GenSigTimeoutTime_CADM" SG_ 2651930625 Digit_01_ECM 0;
BA_ "GenSigTimeoutTime_DMSM" SG_ 2651930625 Digit_01_ECM 0;
BA_ "GenSigTimeoutTime_DTCM" SG_ 2651930625 Digit_01_ECM 0;
BA_ "GenSigTimeoutTime_ECM" SG_ 2651930625 Digit_01_ECM 0;
BA_ "GenSigTimeoutTime_ELSDM" SG_ 2651930625 Digit_01_ECM 0;
BA_ "GenSigTimeoutTime_ESL" SG_ 2651930625 Digit_01_ECM 0;
BA_ "GenSigTimeoutTime_GNMM" SG_ 2651930625 Digit_01_ECM 0;
BA_ "GenSigTimeoutTime_HCP" SG_ 2651930625 Digit_01_ECM 0;
BA_ "GenSigTimeoutTime_IPC" SG_ 2651930625 Digit_01_ECM 0;
BA_ "GenSigTimeoutTime_RFHM" SG_ 2651930625 Digit_01_ECM 0;
BA_ "GenSigTimeoutTime_SGW" SG_ 2651930625 Digit_01_ECM 0;
BA_ "GenSigTimeoutTime_TCM" SG_ 2651930625 Digit_01_ECM 0;
BA_ "GenSigTimeoutTime_AGSM" SG_ 2651930625 Digit_02_ECM 0;
BA_ "GenSigTimeoutTime_ASBS" SG_ 2651930625 Digit_02_ECM 0;
BA_ "GenSigTimeoutTime_BSM" SG_ 2651930625 Digit_02_ECM 0;
BA_ "GenSigTimeoutTime_CADM" SG_ 2651930625 Digit_02_ECM 0;
BA_ "GenSigTimeoutTime_DMSM" SG_ 2651930625 Digit_02_ECM 0;
BA_ "GenSigTimeoutTime_DTCM" SG_ 2651930625 Digit_02_ECM 0;
BA_ "GenSigTimeoutTime_ECM" SG_ 2651930625 Digit_02_ECM 0;
BA_ "GenSigTimeoutTime_ELSDM" SG_ 2651930625 Digit_02_ECM 0;
BA_ "GenSigTimeoutTime_ESL" SG_ 2651930625 Digit_02_ECM 0;
BA_ "GenSigTimeoutTime_GNMM" SG_ 2651930625 Digit_02_ECM 0;
BA_ "GenSigTimeoutTime_HCP" SG_ 2651930625 Digit_02_ECM 0;
BA_ "GenSigTimeoutTime_IPC" SG_ 2651930625 Digit_02_ECM 0;
BA_ "GenSigTimeoutTime_RFHM" SG_ 2651930625 Digit_02_ECM 0;
BA_ "GenSigTimeoutTime_SGW" SG_ 2651930625 Digit_02_ECM 0;
BA_ "GenSigTimeoutTime_TCM" SG_ 2651930625 Digit_02_ECM 0;
BA_ "GenSigTimeoutTime_AGSM" SG_ 2651930625 Digit_03_ECM 0;
BA_ "GenSigTimeoutTime_ASBS" SG_ 2651930625 Digit_03_ECM 0;
BA_ "GenSigTimeoutTime_BSM" SG_ 2651930625 Digit_03_ECM 0;
BA_ "GenSigTimeoutTime_CADM" SG_ 2651930625 Digit_03_ECM 0;
BA_ "GenSigTimeoutTime_DMSM" SG_ 2651930625 Digit_03_ECM 0;
BA_ "GenSigTimeoutTime_DTCM" SG_ 2651930625 Digit_03_ECM 0;
BA_ "GenSigTimeoutTime_ECM" SG_ 2651930625 Digit_03_ECM 0;
BA_ "GenSigTimeoutTime_ELSDM" SG_ 2651930625 Digit_03_ECM 0;
BA_ "GenSigTimeoutTime_ESL" SG_ 2651930625 Digit_03_ECM 0;
BA_ "GenSigTimeoutTime_GNMM" SG_ 2651930625 Digit_03_ECM 0;
BA_ "GenSigTimeoutTime_HCP" SG_ 2651930625 Digit_03_ECM 0;
BA_ "GenSigTimeoutTime_IPC" SG_ 2651930625 Digit_03_ECM 0;
BA_ "GenSigTimeoutTime_RFHM" SG_ 2651930625 Digit_03_ECM 0;
BA_ "GenSigTimeoutTime_SGW" SG_ 2651930625 Digit_03_ECM 0;
BA_ "GenSigTimeoutTime_TCM" SG_ 2651930625 Digit_03_ECM 0;
BA_ "GenSigTimeoutTime_AGSM" SG_ 2651930625 Digit_04_ECM 0;
BA_ "GenSigTimeoutTime_ASBS" SG_ 2651930625 Digit_04_ECM 0;
BA_ "GenSigTimeoutTime_BSM" SG_ 2651930625 Digit_04_ECM 0;
BA_ "GenSigTimeoutTime_CADM" SG_ 2651930625 Digit_04_ECM 0;
BA_ "GenSigTimeoutTime_DMSM" SG_ 2651930625 Digit_04_ECM 0;
BA_ "GenSigTimeoutTime_DTCM" SG_ 2651930625 Digit_04_ECM 0;
BA_ "GenSigTimeoutTime_ECM" SG_ 2651930625 Digit_04_ECM 0;
BA_ "GenSigTimeoutTime_ELSDM" SG_ 2651930625 Digit_04_ECM 0;
BA_ "GenSigTimeoutTime_ESL" SG_ 2651930625 Digit_04_ECM 0;
BA_ "GenSigTimeoutTime_GNMM" SG_ 2651930625 Digit_04_ECM 0;
BA_ "GenSigTimeoutTime_HCP" SG_ 2651930625 Digit_04_ECM 0;
BA_ "GenSigTimeoutTime_IPC" SG_ 2651930625 Digit_04_ECM 0;
BA_ "GenSigTimeoutTime_RFHM" SG_ 2651930625 Digit_04_ECM 0;
BA_ "GenSigTimeoutTime_SGW" SG_ 2651930625 Digit_04_ECM 0;
BA_ "GenSigTimeoutTime_TCM" SG_ 2651930625 Digit_04_ECM 0;
BA_ "GenSigTimeoutTime_AGSM" SG_ 2651930625 Digit_05_ECM 0;
BA_ "GenSigTimeoutTime_ASBS" SG_ 2651930625 Digit_05_ECM 0;
BA_ "GenSigTimeoutTime_BSM" SG_ 2651930625 Digit_05_ECM 0;
BA_ "GenSigTimeoutTime_CADM" SG_ 2651930625 Digit_05_ECM 0;
BA_ "GenSigTimeoutTime_DMSM" SG_ 2651930625 Digit_05_ECM 0;
BA_ "GenSigTimeoutTime_DTCM" SG_ 2651930625 Digit_05_ECM 0;
BA_ "GenSigTimeoutTime_ECM" SG_ 2651930625 Digit_05_ECM 0;
BA_ "GenSigTimeoutTime_ELSDM" SG_ 2651930625 Digit_05_ECM 0;
BA_ "GenSigTimeoutTime_ESL" SG_ 2651930625 Digit_05_ECM 0;
BA_ "GenSigTimeoutTime_GNMM" SG_ 2651930625 Digit_05_ECM 0;
BA_ "GenSigTimeoutTime_HCP" SG_ 2651930625 Digit_05_ECM 0;
BA_ "GenSigTimeoutTime_IPC" SG_ 2651930625 Digit_05_ECM 0;
BA_ "GenSigTimeoutTime_RFHM" SG_ 2651930625 Digit_05_ECM 0;
BA_ "GenSigTimeoutTime_SGW" SG_ 2651930625 Digit_05_ECM 0;
BA_ "GenSigTimeoutTime_TCM" SG_ 2651930625 Digit_05_ECM 0;
BA_ "GenSigTimeoutTime_AGSM" SG_ 2651930625 Digit_06_ECM 0;
BA_ "GenSigTimeoutTime_ASBS" SG_ 2651930625 Digit_06_ECM 0;
BA_ "GenSigTimeoutTime_BSM" SG_ 2651930625 Digit_06_ECM 0;
BA_ "GenSigTimeoutTime_CADM" SG_ 2651930625 Digit_06_ECM 0;
BA_ "GenSigTimeoutTime_DMSM" SG_ 2651930625 Digit_06_ECM 0;
BA_ "GenSigTimeoutTime_DTCM" SG_ 2651930625 Digit_06_ECM 0;
BA_ "GenSigTimeoutTime_ECM" SG_ 2651930625 Digit_06_ECM 0;
BA_ "GenSigTimeoutTime_ELSDM" SG_ 2651930625 Digit_06_ECM 0;
BA_ "GenSigTimeoutTime_ESL" SG_ 2651930625 Digit_06_ECM 0;
BA_ "GenSigTimeoutTime_GNMM" SG_ 2651930625 Digit_06_ECM 0;
BA_ "GenSigTimeoutTime_HCP" SG_ 2651930625 Digit_06_ECM 0;
BA_ "GenSigTimeoutTime_IPC" SG_ 2651930625 Digit_06_ECM 0;
BA_ "GenSigTimeoutTime_RFHM" SG_ 2651930625 Digit_06_ECM 0;
BA_ "GenSigTimeoutTime_SGW" SG_ 2651930625 Digit_06_ECM 0;
BA_ "GenSigTimeoutTime_TCM" SG_ 2651930625 Digit_06_ECM 0;
BA_ "GenSigTimeoutTime_AGSM" SG_ 2651930625 Digit_07_ECM 0;
BA_ "GenSigTimeoutTime_ASBS" SG_ 2651930625 Digit_07_ECM 0;
BA_ "GenSigTimeoutTime_BSM" SG_ 2651930625 Digit_07_ECM 0;
BA_ "GenSigTimeoutTime_CADM" SG_ 2651930625 Digit_07_ECM 0;
BA_ "GenSigTimeoutTime_DMSM" SG_ 2651930625 Digit_07_ECM 0;
BA_ "GenSigTimeoutTime_DTCM" SG_ 2651930625 Digit_07_ECM 0;
BA_ "GenSigTimeoutTime_ECM" SG_ 2651930625 Digit_07_ECM 0;
BA_ "GenSigTimeoutTime_ELSDM" SG_ 2651930625 Digit_07_ECM 0;
BA_ "GenSigTimeoutTime_ESL" SG_ 2651930625 Digit_07_ECM 0;
BA_ "GenSigTimeoutTime_GNMM" SG_ 2651930625 Digit_07_ECM 0;
BA_ "GenSigTimeoutTime_HCP" SG_ 2651930625 Digit_07_ECM 0;
BA_ "GenSigTimeoutTime_IPC" SG_ 2651930625 Digit_07_ECM 0;
BA_ "GenSigTimeoutTime_RFHM" SG_ 2651930625 Digit_07_ECM 0;
BA_ "GenSigTimeoutTime_SGW" SG_ 2651930625 Digit_07_ECM 0;
BA_ "GenSigTimeoutTime_TCM" SG_ 2651930625 Digit_07_ECM 0;
BA_ "GenSigTimeoutTime_AGSM" SG_ 2651930625 Digit_08_ECM 0;
BA_ "GenSigTimeoutTime_ASBS" SG_ 2651930625 Digit_08_ECM 0;
BA_ "GenSigTimeoutTime_BSM" SG_ 2651930625 Digit_08_ECM 0;
BA_ "GenSigTimeoutTime_CADM" SG_ 2651930625 Digit_08_ECM 0;
BA_ "GenSigTimeoutTime_DMSM" SG_ 2651930625 Digit_08_ECM 0;
BA_ "GenSigTimeoutTime_DTCM" SG_ 2651930625 Digit_08_ECM 0;
BA_ "GenSigTimeoutTime_ECM" SG_ 2651930625 Digit_08_ECM 0;
BA_ "GenSigTimeoutTime_ELSDM" SG_ 2651930625 Digit_08_ECM 0;
BA_ "GenSigTimeoutTime_ESL" SG_ 2651930625 Digit_08_ECM 0;
BA_ "GenSigTimeoutTime_GNMM" SG_ 2651930625 Digit_08_ECM 0;
BA_ "GenSigTimeoutTime_HCP" SG_ 2651930625 Digit_08_ECM 0;
BA_ "GenSigTimeoutTime_IPC" SG_ 2651930625 Digit_08_ECM 0;
BA_ "GenSigTimeoutTime_RFHM" SG_ 2651930625 Digit_08_ECM 0;
BA_ "GenSigTimeoutTime_SGW" SG_ 2651930625 Digit_08_ECM 0;
BA_ "GenSigTimeoutTime_TCM" SG_ 2651930625 Digit_08_ECM 0;
BA_ "GenSigTimeoutTime_AGSM" SG_ 2651930625 Digit_09_ECM 0;
BA_ "GenSigTimeoutTime_ASBS" SG_ 2651930625 Digit_09_ECM 0;
BA_ "GenSigTimeoutTime_BSM" SG_ 2651930625 Digit_09_ECM 0;
BA_ "GenSigTimeoutTime_CADM" SG_ 2651930625 Digit_09_ECM 0;
BA_ "GenSigTimeoutTime_DMSM" SG_ 2651930625 Digit_09_ECM 0;
BA_ "GenSigTimeoutTime_DTCM" SG_ 2651930625 Digit_09_ECM 0;
BA_ "GenSigTimeoutTime_ECM" SG_ 2651930625 Digit_09_ECM 0;
BA_ "GenSigTimeoutTime_ELSDM" SG_ 2651930625 Digit_09_ECM 0;
BA_ "GenSigTimeoutTime_ESL" SG_ 2651930625 Digit_09_ECM 0;
BA_ "GenSigTimeoutTime_GNMM" SG_ 2651930625 Digit_09_ECM 0;
BA_ "GenSigTimeoutTime_HCP" SG_ 2651930625 Digit_09_ECM 0;
BA_ "GenSigTimeoutTime_IPC" SG_ 2651930625 Digit_09_ECM 0;
BA_ "GenSigTimeoutTime_RFHM" SG_ 2651930625 Digit_09_ECM 0;
BA_ "GenSigTimeoutTime_SGW" SG_ 2651930625 Digit_09_ECM 0;
BA_ "GenSigTimeoutTime_TCM" SG_ 2651930625 Digit_09_ECM 0;
BA_ "GenSigTimeoutTime_AGSM" SG_ 2651930625 Digit_10_ECM 0;
BA_ "GenSigTimeoutTime_ASBS" SG_ 2651930625 Digit_10_ECM 0;
BA_ "GenSigTimeoutTime_BSM" SG_ 2651930625 Digit_10_ECM 0;
BA_ "GenSigTimeoutTime_CADM" SG_ 2651930625 Digit_10_ECM 0;
BA_ "GenSigTimeoutTime_DMSM" SG_ 2651930625 Digit_10_ECM 0;
BA_ "GenSigTimeoutTime_DTCM" SG_ 2651930625 Digit_10_ECM 0;
BA_ "GenSigTimeoutTime_ECM" SG_ 2651930625 Digit_10_ECM 0;
BA_ "GenSigTimeoutTime_ELSDM" SG_ 2651930625 Digit_10_ECM 0;
BA_ "GenSigTimeoutTime_ESL" SG_ 2651930625 Digit_10_ECM 0;
BA_ "GenSigTimeoutTime_GNMM" SG_ 2651930625 Digit_10_ECM 0;
BA_ "GenSigTimeoutTime_HCP" SG_ 2651930625 Digit_10_ECM 0;
BA_ "GenSigTimeoutTime_IPC" SG_ 2651930625 Digit_10_ECM 0;
BA_ "GenSigTimeoutTime_RFHM" SG_ 2651930625 Digit_10_ECM 0;
BA_ "GenSigTimeoutTime_SGW" SG_ 2651930625 Digit_10_ECM 0;
BA_ "GenSigTimeoutTime_TCM" SG_ 2651930625 Digit_10_ECM 0;
BA_ "GenSigTimeoutTime_AGSM" SG_ 2651930625 Digit_11_ECM 0;
BA_ "GenSigTimeoutTime_ASBS" SG_ 2651930625 Digit_11_ECM 0;
BA_ "GenSigTimeoutTime_BSM" SG_ 2651930625 Digit_11_ECM 0;
BA_ "GenSigTimeoutTime_CADM" SG_ 2651930625 Digit_11_ECM 0;
BA_ "GenSigTimeoutTime_DMSM" SG_ 2651930625 Digit_11_ECM 0;
BA_ "GenSigTimeoutTime_DTCM" SG_ 2651930625 Digit_11_ECM 0;
BA_ "GenSigTimeoutTime_ECM" SG_ 2651930625 Digit_11_ECM 0;
BA_ "GenSigTimeoutTime_ELSDM" SG_ 2651930625 Digit_11_ECM 0;
BA_ "GenSigTimeoutTime_ESL" SG_ 2651930625 Digit_11_ECM 0;
BA_ "GenSigTimeoutTime_GNMM" SG_ 2651930625 Digit_11_ECM 0;
BA_ "GenSigTimeoutTime_HCP" SG_ 2651930625 Digit_11_ECM 0;
BA_ "GenSigTimeoutTime_IPC" SG_ 2651930625 Digit_11_ECM 0;
BA_ "GenSigTimeoutTime_RFHM" SG_ 2651930625 Digit_11_ECM 0;
BA_ "GenSigTimeoutTime_SGW" SG_ 2651930625 Digit_11_ECM 0;
BA_ "GenSigTimeoutTime_TCM" SG_ 2651930625 Digit_11_ECM 0;
BA_ "GenSigTimeoutTime_ESL" SG_ 264 LwsAngle 0;
BA_ "GenSigTimeoutTime_GNMM" SG_ 264 LwsAngle 0;
BA_ "GenSigTimeoutTime_HCP" SG_ 264 LwsAngle 0;
BA_ "GenSigTimeoutTime_RFHM" SG_ 264 LwsAngle 0;
BA_ "GenSigTimeoutTime_SGW" SG_ 264 LwsAngle 0;
BA_ "GenSigTimeoutTime_ADCAM" SG_ 1955 IBS3_FLAG_DISCONNECT 0;
BA_ "GenSigTimeoutTime_VDCM" SG_ 1955 IBS3_FLAG_DISCONNECT 0;
BA_ "GenSigTimeoutTime_ADCAM" SG_ 1955 IBS3_SOC_Accuracy 0;
BA_ "GenSigTimeoutTime_VDCM" SG_ 1955 IBS3_SOC_Accuracy 0;
BA_ "GenSigTimeoutTime_ADCAM" SG_ 1955 IBS3_SOH_Q_Accuracy 0;
BA_ "GenSigTimeoutTime_VDCM" SG_ 1955 IBS3_SOH_Q_Accuracy 0;
BA_ "GenSigTimeoutTime_ADCAM" SG_ 1955 IBS3_TempFailStatus 0;
BA_ "GenSigTimeoutTime_VDCM" SG_ 1955 IBS3_TempFailStatus 0;
BA_ "GenSigTimeoutTime_VDCM" SG_ 1955 IBS3_SOC 0;
BA_ "GenSigTimeoutTime_ADCAM" SG_ 1955 IBS3_SOH_Q 0;
BA_ "GenSigTimeoutTime_VDCM" SG_ 1955 IBS3_SOH_Q 0;
BA_ "GenSigTimeoutTime_ADCAM" SG_ 1955 IBS3_T_BATT 0;
BA_ "GenSigTimeoutTime_VDCM" SG_ 1955 IBS3_T_BATT 0;
BA_ "GenSigTimeoutTime_AGSM" SG_ 1955 IBS3_FLAG_DISCONNECT 0;
BA_ "GenSigTimeoutTime_ASBS" SG_ 1955 IBS3_FLAG_DISCONNECT 0;
BA_ "GenSigTimeoutTime_BCM" SG_ 1955 IBS3_FLAG_DISCONNECT 0;
BA_ "GenSigTimeoutTime_BSM" SG_ 1955 IBS3_FLAG_DISCONNECT 0;
BA_ "GenSigTimeoutTime_CADM" SG_ 1955 IBS3_FLAG_DISCONNECT 0;
BA_ "GenSigTimeoutTime_DMSM" SG_ 1955 IBS3_FLAG_DISCONNECT 0;
BA_ "GenSigTimeoutTime_DTCM" SG_ 1955 IBS3_FLAG_DISCONNECT 0;
BA_ "GenSigTimeoutTime_ELSDM" SG_ 1955 IBS3_FLAG_DISCONNECT 0;
BA_ "GenSigTimeoutTime_ESL" SG_ 1955 IBS3_FLAG_DISCONNECT 0;
BA_ "GenSigTimeoutTime_GNMM" SG_ 1955 IBS3_FLAG_DISCONNECT 0;
BA_ "GenSigTimeoutTime_HCP" SG_ 1955 IBS3_FLAG_DISCONNECT 0;
BA_ "GenSigTimeoutTime_IPC" SG_ 1955 IBS3_FLAG_DISCONNECT 0;
BA_ "GenSigTimeoutTime_RFHM" SG_ 1955 IBS3_FLAG_DISCONNECT 0;
BA_ "GenSigTimeoutTime_SGW" SG_ 1955 IBS3_FLAG_DISCONNECT 0;
BA_ "GenSigTimeoutTime_TCM" SG_ 1955 IBS3_FLAG_DISCONNECT 0;
BA_ "GenSigTimeoutTime_AGSM" SG_ 1955 IBS3_SOC_Accuracy 0;
BA_ "GenSigTimeoutTime_ASBS" SG_ 1955 IBS3_SOC_Accuracy 0;
BA_ "GenSigTimeoutTime_BCM" SG_ 1955 IBS3_SOC_Accuracy 0;
BA_ "GenSigTimeoutTime_BSM" SG_ 1955 IBS3_SOC_Accuracy 0;
BA_ "GenSigTimeoutTime_CADM" SG_ 1955 IBS3_SOC_Accuracy 0;
BA_ "GenSigTimeoutTime_DMSM" SG_ 1955 IBS3_SOC_Accuracy 0;
BA_ "GenSigTimeoutTime_DTCM" SG_ 1955 IBS3_SOC_Accuracy 0;
BA_ "GenSigTimeoutTime_ELSDM" SG_ 1955 IBS3_SOC_Accuracy 0;
BA_ "GenSigTimeoutTime_ESL" SG_ 1955 IBS3_SOC_Accuracy 0;
BA_ "GenSigTimeoutTime_GNMM" SG_ 1955 IBS3_SOC_Accuracy 0;
BA_ "GenSigTimeoutTime_IPC" SG_ 1955 IBS3_SOC_Accuracy 0;
BA_ "GenSigTimeoutTime_TCM" SG_ 1955 IBS3_SOC_Accuracy 0;
BA_ "GenSigTimeoutTime_AGSM" SG_ 1955 IBS3_SOH_Q_Accuracy 0;
BA_ "GenSigTimeoutTime_ASBS" SG_ 1955 IBS3_SOH_Q_Accuracy 0;
BA_ "GenSigTimeoutTime_BCM" SG_ 1955 IBS3_SOH_Q_Accuracy 0;
BA_ "GenSigTimeoutTime_BSM" SG_ 1955 IBS3_SOH_Q_Accuracy 0;
BA_ "GenSigTimeoutTime_CADM" SG_ 1955 IBS3_SOH_Q_Accuracy 0;
BA_ "GenSigTimeoutTime_DMSM" SG_ 1955 IBS3_SOH_Q_Accuracy 0;
BA_ "GenSigTimeoutTime_DTCM" SG_ 1955 IBS3_SOH_Q_Accuracy 0;
BA_ "GenSigTimeoutTime_ELSDM" SG_ 1955 IBS3_SOH_Q_Accuracy 0;
BA_ "GenSigTimeoutTime_ESL" SG_ 1955 IBS3_SOH_Q_Accuracy 0;
BA_ "GenSigTimeoutTime_GNMM" SG_ 1955 IBS3_SOH_Q_Accuracy 0;
BA_ "GenSigTimeoutTime_HCP" SG_ 1955 IBS3_SOH_Q_Accuracy 0;
BA_ "GenSigTimeoutTime_IPC" SG_ 1955 IBS3_SOH_Q_Accuracy 0;
BA_ "GenSigTimeoutTime_RFHM" SG_ 1955 IBS3_SOH_Q_Accuracy 0;
BA_ "GenSigTimeoutTime_SGW" SG_ 1955 IBS3_SOH_Q_Accuracy 0;
BA_ "GenSigTimeoutTime_TCM" SG_ 1955 IBS3_SOH_Q_Accuracy 0;
BA_ "GenSigTimeoutTime_AGSM" SG_ 1955 IBS3_TempFailStatus 0;
BA_ "GenSigTimeoutTime_ASBS" SG_ 1955 IBS3_TempFailStatus 0;
BA_ "GenSigTimeoutTime_BCM" SG_ 1955 IBS3_TempFailStatus 0;
BA_ "GenSigTimeoutTime_BSM" SG_ 1955 IBS3_TempFailStatus 0;
BA_ "GenSigTimeoutTime_CADM" SG_ 1955 IBS3_TempFailStatus 0;
BA_ "GenSigTimeoutTime_DMSM" SG_ 1955 IBS3_TempFailStatus 0;
BA_ "GenSigTimeoutTime_DTCM" SG_ 1955 IBS3_TempFailStatus 0;
BA_ "GenSigTimeoutTime_ELSDM" SG_ 1955 IBS3_TempFailStatus 0;
BA_ "GenSigTimeoutTime_ESL" SG_ 1955 IBS3_TempFailStatus 0;
BA_ "GenSigTimeoutTime_ELSDM" SG_ 104 MKKey_4 0;
BA_ "GenSigTimeoutTime_ESL" SG_ 104 MKKey_4 0;
BA_ "GenSigTimeoutTime_GNMM" SG_ 104 MKKey_4 0;
BA_ "GenSigTimeoutTime_HCP" SG_ 104 MKKey_4 0;
BA_ "GenSigTimeoutTime_IPC" SG_ 104 MKKey_4 0;
BA_ "GenSigTimeoutTime_RFHM" SG_ 104 MKKey_4 0;
BA_ "GenSigTimeoutTime_SGW" SG_ 104 MKKey_4 0;
BA_ "GenSigTimeoutTime_TCM" SG_ 104 MKKey_4 0;
BA_ "GenSigTimeoutTime_AGSM" SG_ 104 MKKey_5 0;
BA_ "GenSigTimeoutTime_ASBS" SG_ 104 MKKey_5 0;
BA_ "GenSigTimeoutTime_BCM" SG_ 104 MKKey_5 0;
BA_ "GenSigTimeoutTime_BSM" SG_ 104 MKKey_5 0;
BA_ "GenSigTimeoutTime_CADM" SG_ 104 MKKey_5 0;
BA_ "GenSigTimeoutTime_DMSM" SG_ 104 MKKey_5 0;
BA_ "GenSigTimeoutTime_DTCM" SG_ 104 MKKey_5 0;
BA_ "GenSigTimeoutTime_ELSDM" SG_ 104 MKKey_5 0;
BA_ "GenSigTimeoutTime_ESL" SG_ 104 MKKey_5 0;
BA_ "GenSigTimeoutTime_GNMM" SG_ 104 MKKey_5 0;
BA_ "GenSigTimeoutTime_HCP" SG_ 104 MKKey_5 0;
BA_ "GenSigTimeoutTime_IPC" SG_ 104 MKKey_5 0;
BA_ "GenSigTimeoutTime_RFHM" SG_ 104 MKKey_5 0;
BA_ "GenSigTimeoutTime_SGW" SG_ 104 MKKey_5 0;
BA_ "GenSigTimeoutTime_TCM" SG_ 104 MKKey_5 0;
BA_ "GenSigTimeoutTime_AGSM" SG_ 104 MKKey_6 0;
BA_ "GenSigTimeoutTime_ASBS" SG_ 104 MKKey_6 0;
BA_ "GenSigTimeoutTime_BCM" SG_ 104 MKKey_6 0;
BA_ "GenSigTimeoutTime_BSM" SG_ 104 MKKey_6 0;
BA_ "GenSigTimeoutTime_CADM" SG_ 104 MKKey_6 0;
BA_ "GenSigTimeoutTime_DMSM" SG_ 104 MKKey_6 0;
BA_ "GenSigTimeoutTime_DTCM" SG_ 104 MKKey_6 0;
BA_ "GenSigTimeoutTime_ELSDM" SG_ 104 MKKey_6 0;
BA_ "GenSigTimeoutTime_ESL" SG_ 104 MKKey_6 0;
BA_ "GenSigTimeoutTime_GNMM" SG_ 104 MKKey_6 0;
BA_ "GenSigTimeoutTime_HCP" SG_ 104 MKKey_6 0;
BA_ "GenSigTimeoutTime_IPC" SG_ 104 MKKey_6 0;
BA_ "GenSigTimeoutTime_RFHM" SG_ 104 MKKey_6 0;
BA_ "GenSigTimeoutTime_SGW" SG_ 104 MKKey_6 0;
BA_ "GenSigTimeoutTime_TCM" SG_ 104 MKKey_6 0;
BA_ "GenSigTimeoutTime_AGSM" SG_ 104 MKKey1org21 0;
BA_ "GenSigTimeoutTime_ASBS" SG_ 104 MKKey1org21 0;
BA_ "GenSigTimeoutTime_BCM" SG_ 104 MKKey1org21 0;
BA_ "GenSigTimeoutTime_BSM" SG_ 104 MKKey1org21 0;
BA_ "GenSigTimeoutTime_CADM" SG_ 104 MKKey1org21 0;
BA_ "GenSigTimeoutTime_DMSM" SG_ 104 MKKey1org21 0;
BA_ "GenSigTimeoutTime_DTCM" SG_ 104 MKKey1org21 0;
BA_ "GenSigTimeoutTime_ELSDM" SG_ 104 MKKey1org21 0;
BA_ "GenSigTimeoutTime_ESL" SG_ 104 MKKey1org21 0;
BA_ "GenSigTimeoutTime_GNMM" SG_ 104 MKKey1org21 0;
BA_ "GenSigTimeoutTime_HCP" SG_ 104 MKKey1org21 0;
BA_ "GenSigTimeoutTime_IPC" SG_ 104 MKKey1org21 0;
BA_ "GenSigTimeoutTime_RFHM" SG_ 104 MKKey1org21 0;
BA_ "GenSigTimeoutTime_SGW" SG_ 104 MKKey1org21 0;
BA_ "GenSigTimeoutTime_TCM" SG_ 104 MKKey1org21 0;
BA_ "GenSigTimeoutTime_AGSM" SG_ 104 MKKey2org22 0;
BA_ "GenSigTimeoutTime_ASBS" SG_ 104 MKKey2org22 0;
BA_ "GenSigTimeoutTime_BCM" SG_ 104 MKKey2org22 0;
BA_ "GenSigTimeoutTime_BSM" SG_ 104 MKKey2org22 0;
BA_ "GenSigTimeoutTime_CADM" SG_ 104 MKKey2org22 0;
BA_ "GenSigTimeoutTime_DMSM" SG_ 104 MKKey2org22 0;
BA_ "GenSigTimeoutTime_DTCM" SG_ 104 MKKey2org22 0;
BA_ "GenSigTimeoutTime_ELSDM" SG_ 104 MKKey2org22 0;
BA_ "GenSigTimeoutTime_ESL" SG_ 104 MKKey2org22 0;
BA_ "GenSigTimeoutTime_GNMM" SG_ 104 MKKey2org22 0;
BA_ "GenSigTimeoutTime_HCP" SG_ 104 MKKey2org22 0;
BA_ "GenSigTimeoutTime_IPC" SG_ 104 MKKey2org22 0;
BA_ "GenSigTimeoutTime_RFHM" SG_ 104 MKKey2org22 0;
BA_ "GenSigTimeoutTime_SGW" SG_ 104 MKKey2org22 0;
BA_ "GenSigTimeoutTime_TCM" SG_ 104 MKKey2org22 0;
BA_ "GenSigTimeoutTime_ADCAM" SG_ 1626 IMPACTThreshold 0;
BA_ "GenSigTimeoutTime_VDCM" SG_ 1626 IMPACTThreshold 0;
BA_ "GenSigTimeoutTime_ADCAM" SG_ 1626 IMPACTCommand 0;
BA_ "GenSigTimeoutTime_VDCM" SG_ 1626 IMPACTCommand 0;
BA_ "GenSigTimeoutTime_ADCAM" SG_ 1626 IMPACTConfirm 0;
BA_ "GenSigTimeoutTime_VDCM" SG_ 1626 IMPACTConfirm 0;
BA_ "GenSigTimeoutTime_AGSM" SG_ 1626 IMPACTThreshold 0;
BA_ "GenSigTimeoutTime_ASBS" SG_ 1626 IMPACTThreshold 0;
BA_ "GenSigTimeoutTime_BCM" SG_ 1626 IMPACTThreshold 0;
BA_ "GenSigTimeoutTime_BSM" SG_ 1626 IMPACTThreshold 0;
BA_ "GenSigTimeoutTime_CADM" SG_ 1626 IMPACTThreshold 0;
BA_ "GenSigTimeoutTime_DMSM" SG_ 1626 IMPACTThreshold 0;
BA_ "GenSigTimeoutTime_DTCM" SG_ 1626 IMPACTThreshold 0;
BA_ "GenSigTimeoutTime_ELSDM" SG_ 1626 IMPACTThreshold 0;
BA_ "GenSigTimeoutTime_ESL" SG_ 1626 IMPACTThreshold 0;
BA_ "GenSigTimeoutTime_GNMM" SG_ 1626 IMPACTThreshold 0;
BA_ "GenSigTimeoutTime_HCP" SG_ 1626 IMPACTThreshold 0;
BA_ "GenSigTimeoutTime_IPC" SG_ 1626 IMPACTThreshold 0;
BA_ "GenSigTimeoutTime_RFHM" SG_ 1626 IMPACTThreshold 0;
BA_ "GenSigTimeoutTime_SGW" SG_ 1626 IMPACTThreshold 0;
BA_ "GenSigTimeoutTime_TCM" SG_ 1626 IMPACTThreshold 0;
BA_ "GenSigSendType" SG_ 1626 IMPACTCommand 5;
BA_ "GenSigTimeoutTime_AGSM" SG_ 1626 IMPACTCommand 0;
BA_ "GenSigTimeoutTime_ASBS" SG_ 1626 IMPACTCommand 0;
BA_ "GenSigTimeoutTime_BCM" SG_ 1626 IMPACTCommand 0;
BA_ "GenSigTimeoutTime_BSM" SG_ 1626 IMPACTCommand 0;
BA_ "GenSigTimeoutTime_CADM" SG_ 1626 IMPACTCommand 0;
BA_ "GenSigTimeoutTime_DTCM" SG_ 1626 IMPACTCommand 0;
BA_ "GenSigTimeoutTime_ELSDM" SG_ 1626 IMPACTCommand 0;
BA_ "GenSigTimeoutTime_ESL" SG_ 1626 IMPACTCommand 0;
BA_ "GenSigTimeoutTime_GNMM" SG_ 1626 IMPACTCommand 0;
BA_ "GenSigTimeoutTime_IPC" SG_ 1626 IMPACTCommand 0;
BA_ "GenSigTimeoutTime_RFHM" SG_ 1626 IMPACTCommand 0;
BA_ "GenSigTimeoutTime_SGW" SG_ 1626 IMPACTCommand 0;
BA_ "GenSigTimeoutTime_TCM" SG_ 1626 IMPACTCommand 0;
BA_ "GenSigStartValue" SG_ 1626 IMPACTConfirm 1;
BA_ "GenSigInactiveValue" SG_ 1626 IMPACTConfirm 1;
BA_ "GenSigSendType" SG_ 1626 IMPACTConfirm 5;
BA_ "GenSigTimeoutTime_AGSM" SG_ 1626 IMPACTConfirm 0;
BA_ "GenSigTimeoutTime_ASBS" SG_ 1626 IMPACTConfirm 0;
BA_ "GenSigTimeoutTime_BCM" SG_ 1626 IMPACTConfirm 0;
BA_ "GenSigTimeoutTime_BSM" SG_ 1626 IMPACTConfirm 0;
BA_ "GenSigTimeoutTime_CADM" SG_ 1626 IMPACTConfirm 0;
BA_ "GenSigTimeoutTime_DTCM" SG_ 1626 IMPACTConfirm 0;
BA_ "GenSigTimeoutTime_ELSDM" SG_ 1626 IMPACTConfirm 0;
BA_ "GenSigTimeoutTime_ESL" SG_ 1626 IMPACTConfirm 0;
BA_ "GenSigTimeoutTime_GNMM" SG_ 1626 IMPACTConfirm 0;
BA_ "GenSigTimeoutTime_IPC" SG_ 1626 IMPACTConfirm 0;
BA_ "GenSigTimeoutTime_RFHM" SG_ 1626 IMPACTConfirm 0;
BA_ "GenSigTimeoutTime_EVCU2" SG_ 1626 IMPACTThreshold 0;
BA_ "GenSigTimeoutTime_ESL" SG_ 1829 CRC_IPC1 0;
BA_ "GenSigTimeoutTime_SGW" SG_ 1626 IMPACTConfirm 0;
BA_ "GenSigTimeoutTime_TCM" SG_ 1626 IMPACTConfirm 0;
BA_ "GenSigTimeoutTime_EVCU2" SG_ 1829 CRC_IPC1 0;
BA_ "GenSigTimeoutTime_VDCM" SG_ 1829 CRC_IPC1 0;
BA_ "GenSigTimeoutTime_EVCU2" SG_ 1829 MessageCounter_IPC1 0;
BA_ "GenSigTimeoutTime_VDCM" SG_ 1829 MessageCounter_IPC1 0;
BA_ "GenSigTimeoutTime_ESL" SG_ 1829 TotalOdometer 0;
BA_ "GenSigTimeoutTime_AGSM" SG_ 1829 CRC_IPC1 0;
BA_ "GenSigTimeoutTime_ASBS" SG_ 1829 CRC_IPC1 0;
BA_ "GenSigTimeoutTime_DTCM" SG_ 1829 CRC_IPC1 0;
BA_ "GenSigTimeoutTime_ELSDM" SG_ 1829 CRC_IPC1 0;
BA_ "GenSigTimeoutTime_GNMM" SG_ 1829 CRC_IPC1 0;
BA_ "GenSigTimeoutTime_HCP" SG_ 1829 CRC_IPC1 0;
BA_ "GenSigTimeoutTime_IPC" SG_ 1829 CRC_IPC1 0;
BA_ "GenSigTimeoutTime_RFHM" SG_ 1829 CRC_IPC1 0;
BA_ "GenSigTimeoutTime_SGW" SG_ 1829 CRC_IPC1 0;
BA_ "GenSigTimeoutTime_TCM" SG_ 1829 CRC_IPC1 0;
BA_ "GenSigTimeoutTime_AGSM" SG_ 1829 MessageCounter_IPC1 0;
BA_ "GenSigTimeoutTime_ASBS" SG_ 1829 MessageCounter_IPC1 0;
BA_ "GenSigTimeoutTime_DTCM" SG_ 1829 MessageCounter_IPC1 0;
BA_ "GenSigTimeoutTime_ELSDM" SG_ 1829 MessageCounter_IPC1 0;
BA_ "GenSigTimeoutTime_ESL" SG_ 1829 MessageCounter_IPC1 0;
BA_ "GenSigTimeoutTime_GNMM" SG_ 1829 MessageCounter_IPC1 0;
BA_ "GenSigTimeoutTime_HCP" SG_ 1829 MessageCounter_IPC1 0;
BA_ "GenSigTimeoutTime_IPC" SG_ 1829 MessageCounter_IPC1 0;
BA_ "GenSigTimeoutTime_RFHM" SG_ 1829 MessageCounter_IPC1 0;
BA_ "GenSigTimeoutTime_SGW" SG_ 1829 MessageCounter_IPC1 0;
BA_ "GenSigTimeoutTime_TCM" SG_ 1829 MessageCounter_IPC1 0;
BA_ "GenSigTimeoutTime_IPC" SG_ 1829 TotalOdometer 0;
BA_ "GenSigTimeoutTime_ADCAM" SG_ 600 OilChgRst 0;
BA_ "GenSigTimeoutTime_EVCU2" SG_ 600 OilChgRst 0;
BA_ "GenSigTimeoutTime_VDCM" SG_ 600 OilChgRst 0;
BA_ "GenSigSendType" SG_ 600 DisplayedSpeedLimSts 3;
BA_ "GenSigTimeoutTime_AGSM" SG_ 600 DisplayedSpeedLimSts 0;
BA_ "GenSigTimeoutTime_ASBS" SG_ 600 DisplayedSpeedLimSts 0;
BA_ "GenSigTimeoutTime_BCM" SG_ 600 DisplayedSpeedLimSts 0;
BA_ "GenSigTimeoutTime_BSM" SG_ 600 DisplayedSpeedLimSts 0;
BA_ "GenSigTimeoutTime_CADM" SG_ 600 DisplayedSpeedLimSts 0;
BA_ "GenSigTimeoutTime_DMSM" SG_ 600 DisplayedSpeedLimSts 0;
BA_ "GenSigTimeoutTime_DTCM" SG_ 600 DisplayedSpeedLimSts 0;
BA_ "GenSigTimeoutTime_ELSDM" SG_ 600 DisplayedSpeedLimSts 0;
BA_ "GenSigTimeoutTime_ESL" SG_ 600 DisplayedSpeedLimSts 0;
BA_ "GenSigTimeoutTime_GNMM" SG_ 600 DisplayedSpeedLimSts 0;
BA_ "GenSigTimeoutTime_HCP" SG_ 600 DisplayedSpeedLimSts 0;
BA_ "GenSigTimeoutTime_IPC" SG_ 600 DisplayedSpeedLimSts 0;
BA_ "GenSigTimeoutTime_RFHM" SG_ 600 DisplayedSpeedLimSts 0;
BA_ "GenSigTimeoutTime_TCM" SG_ 600 DisplayedSpeedLimSts 0;
BA_ "GenSigTimeoutTime_AGSM" SG_ 600 OilChgRst 0;
BA_ "GenSigTimeoutTime_ASBS" SG_ 600 OilChgRst 0;
BA_ "GenSigTimeoutTime_BCM" SG_ 600 OilChgRst 0;
BA_ "GenSigTimeoutTime_BSM" SG_ 600 OilChgRst 0;
BA_ "GenSigTimeoutTime_CADM" SG_ 600 OilChgRst 0;
BA_ "GenSigTimeoutTime_DMSM" SG_ 600 OilChgRst 0;
BA_ "GenSigTimeoutTime_DTCM" SG_ 600 OilChgRst 0;
BA_ "GenSigTimeoutTime_ELSDM" SG_ 600 OilChgRst 0;
BA_ "GenSigTimeoutTime_ESL" SG_ 600 OilChgRst 0;
BA_ "GenSigTimeoutTime_GNMM" SG_ 600 OilChgRst 0;
BA_ "GenSigTimeoutTime_HCP" SG_ 600 OilChgRst 0;
BA_ "GenSigTimeoutTime_IPC" SG_ 600 OilChgRst 0;
BA_ "GenSigTimeoutTime_RFHM" SG_ 600 OilChgRst 0;
BA_ "GenSigTimeoutTime_SGW" SG_ 600 OilChgRst 0;
BA_ "GenSigTimeoutTime_TCM" SG_ 600 OilChgRst 0;
BA_ "GenSigTimeoutTime_ADCAM" SG_ 1954 DrvSbltUnFltr_1 0;
BA_ "GenSigTimeoutTime_EVCU2" SG_ 1954 DrvSbltUnFltr_1 0;
BA_ "GenSigTimeoutTime_VDCM" SG_ 1954 DrvSbltUnFltr_1 0;
BA_ "GenSigTimeoutTime_ADCAM" SG_ 1954 CRC_ORC2 0;
BA_ "GenSigTimeoutTime_EVCU2" SG_ 1954 CRC_ORC2 0;
BA_ "GenSigTimeoutTime_VDCM" SG_ 1954 CRC_ORC2 0;
BA_ "GenSigTimeoutTime_ADCAM" SG_ 1954 MessageCounter_ORC2 0;
BA_ "GenSigTimeoutTime_EVCU2" SG_ 1954 MessageCounter_ORC2 0;
BA_ "GenSigTimeoutTime_VDCM" SG_ 1954 MessageCounter_ORC2 0;
BA_ "GenSigTimeoutTime_AGSM" SG_ 1954 DrvSbltUnFltr_1 0;
BA_ "GenSigTimeoutTime_ASBS" SG_ 1954 DrvSbltUnFltr_1 0;
BA_ "GenSigTimeoutTime_BCM" SG_ 1954 DrvSbltUnFltr_1 0;
BA_ "GenSigTimeoutTime_CADM" SG_ 1954 DrvSbltUnFltr_1 0;
BA_ "GenSigTimeoutTime_DMSM" SG_ 1954 DrvSbltUnFltr_1 0;
BA_ "GenSigTimeoutTime_DTCM" SG_ 1954 DrvSbltUnFltr_1 0;
BA_ "GenSigTimeoutTime_ELSDM" SG_ 1954 DrvSbltUnFltr_1 0;
BA_ "GenSigTimeoutTime_ESL" SG_ 1954 DrvSbltUnFltr_1 0;
BA_ "GenSigTimeoutTime_GNMM" SG_ 1954 DrvSbltUnFltr_1 0;
BA_ "GenSigTimeoutTime_HCP" SG_ 1954 DrvSbltUnFltr_1 0;
BA_ "GenSigTimeoutTime_IPC" SG_ 1954 DrvSbltUnFltr_1 0;
BA_ "GenSigTimeoutTime_RFHM" SG_ 1954 DrvSbltUnFltr_1 0;
BA_ "GenSigTimeoutTime_SGW" SG_ 1954 DrvSbltUnFltr_1 0;
BA_ "GenSigTimeoutTime_AGSM" SG_ 1954 CRC_ORC2 0;
BA_ "GenSigTimeoutTime_ASBS" SG_ 1954 CRC_ORC2 0;
BA_ "GenSigTimeoutTime_BCM" SG_ 1954 CRC_ORC2 0;
BA_ "GenSigTimeoutTime_CADM" SG_ 1954 CRC_ORC2 0;
BA_ "GenSigTimeoutTime_DMSM" SG_ 1954 CRC_ORC2 0;
BA_ "GenSigTimeoutTime_DTCM" SG_ 1954 CRC_ORC2 0;
BA_ "GenSigTimeoutTime_ELSDM" SG_ 1954 CRC_ORC2 0;
BA_ "GenSigTimeoutTime_ESL" SG_ 1954 CRC_ORC2 0;
BA_ "GenSigTimeoutTime_GNMM" SG_ 1954 CRC_ORC2 0;
BA_ "GenSigTimeoutTime_HCP" SG_ 1954 CRC_ORC2 0;
BA_ "GenSigTimeoutTime_IPC" SG_ 1954 CRC_ORC2 0;
BA_ "GenSigTimeoutTime_RFHM" SG_ 1954 CRC_ORC2 0;
BA_ "GenSigTimeoutTime_SGW" SG_ 1954 CRC_ORC2 0;
BA_ "GenSigTimeoutTime_AGSM" SG_ 1954 MessageCounter_ORC2 0;
BA_ "GenSigTimeoutTime_ASBS" SG_ 1954 MessageCounter_ORC2 0;
BA_ "GenSigTimeoutTime_BCM" SG_ 1954 MessageCounter_ORC2 0;
BA_ "GenSigTimeoutTime_CADM" SG_ 1954 MessageCounter_ORC2 0;
BA_ "GenSigTimeoutTime_DMSM" SG_ 1954 MessageCounter_ORC2 0;
BA_ "GenSigTimeoutTime_DTCM" SG_ 1954 MessageCounter_ORC2 0;
BA_ "GenSigTimeoutTime_ELSDM" SG_ 1954 MessageCounter_ORC2 0;
BA_ "GenSigTimeoutTime_ESL" SG_ 1954 MessageCounter_ORC2 0;
BA_ "GenSigTimeoutTime_GNMM" SG_ 1954 MessageCounter_ORC2 0;
BA_ "GenSigTimeoutTime_HCP" SG_ 1954 MessageCounter_ORC2 0;
BA_ "GenSigTimeoutTime_IPC" SG_ 1954 MessageCounter_ORC2 0;
BA_ "GenSigTimeoutTime_RFHM" SG_ 1954 MessageCounter_ORC2 0;
BA_ "GenSigTimeoutTime_SGW" SG_ 1954 MessageCounter_ORC2 0;
BA_ "GenSigTimeoutTime_ADCAM" SG_ 274 CRC_ORC3 0;
BA_ "GenSigTimeoutTime_VDCM" SG_ 274 CRC_ORC3 0;
BA_ "GenSigTimeoutTime_ADCAM" SG_ 274 LatAccelerationFailSts 0;
BA_ "GenSigTimeoutTime_VDCM" SG_ 274 LatAccelerationFailSts 0;
BA_ "GenSigTimeoutTime_ADCAM" SG_ 274 LongAccelerationFailSts 0;
BA_ "GenSigTimeoutTime_VDCM" SG_ 274 LongAccelerationFailSts 0;
BA_ "GenSigTimeoutTime_ADCAM" SG_ 274 MessageCounter_ORC3 0;
BA_ "GenSigTimeoutTime_VDCM" SG_ 274 MessageCounter_ORC3 0;
BA_ "GenSigTimeoutTime_ADCAM" SG_ 274 LatAcceleration 0;
BA_ "GenSigTimeoutTime_VDCM" SG_ 274 LatAcceleration 0;
BA_ "GenSigTimeoutTime_ADCAM" SG_ 274 LongAcceleration 0;
BA_ "GenSigTimeoutTime_VDCM" SG_ 274 LongAcceleration 0;
BA_ "GenSigTimeoutTime_AGSM" SG_ 274 CRC_ORC3 0;
BA_ "GenSigTimeoutTime_ASBS" SG_ 274 CRC_ORC3 0;
BA_ "GenSigTimeoutTime_BCM" SG_ 274 CRC_ORC3 0;
BA_ "GenSigTimeoutTime_BSM" SG_ 274 CRC_ORC3 0;
BA_ "GenSigTimeoutTime_CADM" SG_ 274 CRC_ORC3 0;
BA_ "GenSigTimeoutTime_DMSM" SG_ 274 CRC_ORC3 0;
BA_ "GenSigTimeoutTime_ELSDM" SG_ 274 CRC_ORC3 0;
BA_ "GenSigTimeoutTime_ESL" SG_ 274 CRC_ORC3 0;
BA_ "GenSigTimeoutTime_GNMM" SG_ 274 CRC_ORC3 0;
BA_ "GenSigTimeoutTime_IPC" SG_ 274 CRC_ORC3 0;
BA_ "GenSigTimeoutTime_RFHM" SG_ 274 CRC_ORC3 0;
BA_ "GenSigTimeoutTime_SGW" SG_ 274 CRC_ORC3 0;
BA_ "GenSigTimeoutTime_AGSM" SG_ 274 LatAccelerationFailSts 0;
BA_ "GenSigTimeoutTime_ASBS" SG_ 274 LatAccelerationFailSts 0;
BA_ "GenSigTimeoutTime_BCM" SG_ 274 LatAccelerationFailSts 0;
BA_ "GenSigTimeoutTime_BSM" SG_ 274 LatAccelerationFailSts 0;
BA_ "GenSigTimeoutTime_CADM" SG_ 274 LatAccelerationFailSts 0;
BA_ "GenSigTimeoutTime_DMSM" SG_ 274 LatAccelerationFailSts 0;
BA_ "GenSigTimeoutTime_ELSDM" SG_ 274 LatAccelerationFailSts 0;
BA_ "GenSigTimeoutTime_ESL" SG_ 274 LatAccelerationFailSts 0;
BA_ "GenSigTimeoutTime_GNMM" SG_ 274 LatAccelerationFailSts 0;
BA_ "GenSigTimeoutTime_HCP" SG_ 274 LatAccelerationFailSts 0;
BA_ "GenSigTimeoutTime_IPC" SG_ 274 LatAccelerationFailSts 0;
BA_ "GenSigTimeoutTime_RFHM" SG_ 274 LatAccelerationFailSts 0;
BA_ "GenSigTimeoutTime_SGW" SG_ 274 LatAccelerationFailSts 0;
BA_ "GenSigTimeoutTime_TCM" SG_ 274 LatAccelerationFailSts 0;
BA_ "GenSigTimeoutTime_AGSM" SG_ 274 LongAccelerationFailSts 0;
BA_ "GenSigTimeoutTime_ASBS" SG_ 274 LongAccelerationFailSts 0;
BA_ "GenSigTimeoutTime_BCM" SG_ 274 LongAccelerationFailSts 0;
BA_ "GenSigTimeoutTime_BSM" SG_ 274 LongAccelerationFailSts 0;
BA_ "GenSigTimeoutTime_CADM" SG_ 274 LongAccelerationFailSts 0;
BA_ "GenSigTimeoutTime_DMSM" SG_ 274 LongAccelerationFailSts 0;
BA_ "GenSigTimeoutTime_ELSDM" SG_ 274 LongAccelerationFailSts 0;
BA_ "GenSigTimeoutTime_ESL" SG_ 274 LongAccelerationFailSts 0;
BA_ "GenSigTimeoutTime_GNMM" SG_ 274 LongAccelerationFailSts 0;
BA_ "GenSigTimeoutTime_HCP" SG_ 274 LongAccelerationFailSts 0;
BA_ "GenSigTimeoutTime_IPC" SG_ 274 LongAccelerationFailSts 0;
BA_ "GenSigTimeoutTime_RFHM" SG_ 274 LongAccelerationFailSts 0;
BA_ "GenSigTimeoutTime_SGW" SG_ 274 LongAccelerationFailSts 0;
BA_ "GenSigTimeoutTime_TCM" SG_ 274 LongAccelerationFailSts 0;
BA_ "GenSigTimeoutTime_AGSM" SG_ 274 MessageCounter_ORC3 0;
BA_ "GenSigTimeoutTime_ASBS" SG_ 274 MessageCounter_ORC3 0;
BA_ "GenSigTimeoutTime_BCM" SG_ 274 MessageCounter_ORC3 0;
BA_ "GenSigTimeoutTime_BSM" SG_ 274 MessageCounter_ORC3 0;
BA_ "GenSigTimeoutTime_CADM" SG_ 274 MessageCounter_ORC3 0;
BA_ "GenSigTimeoutTime_DMSM" SG_ 274 MessageCounter_ORC3 0;
BA_ "GenSigTimeoutTime_ELSDM" SG_ 274 MessageCounter_ORC3 0;
BA_ "GenSigTimeoutTime_ESL" SG_ 274 MessageCounter_ORC3 0;
BA_ "GenSigTimeoutTime_GNMM" SG_ 274 MessageCounter_ORC3 0;
BA_ "GenSigTimeoutTime_IPC" SG_ 274 MessageCounter_ORC3 0;
BA_ "GenSigTimeoutTime_RFHM" SG_ 274 MessageCounter_ORC3 0;
BA_ "GenSigTimeoutTime_SGW" SG_ 274 MessageCounter_ORC3 0;
BA_ "GenSigStartValue" SG_ 274 LatAcceleration 4095;
BA_ "GenSigTimeoutTime_AGSM" SG_ 274 LatAcceleration 0;
BA_ "GenSigTimeoutTime_ASBS" SG_ 274 LatAcceleration 0;
BA_ "GenSigTimeoutTime_BCM" SG_ 274 LatAcceleration 0;
BA_ "GenSigTimeoutTime_BSM" SG_ 274 LatAcceleration 0;
BA_ "GenSigTimeoutTime_CADM" SG_ 274 LatAcceleration 0;
BA_ "GenSigTimeoutTime_DMSM" SG_ 274 LatAcceleration 0;
BA_ "GenSigTimeoutTime_ELSDM" SG_ 274 LatAcceleration 0;
BA_ "GenSigTimeoutTime_ESL" SG_ 274 LatAcceleration 0;
BA_ "GenSigTimeoutTime_GNMM" SG_ 274 LatAcceleration 0;
BA_ "GenSigTimeoutTime_HCP" SG_ 274 LatAcceleration 0;
BA_ "GenSigTimeoutTime_IPC" SG_ 274 LatAcceleration 0;
BA_ "GenSigTimeoutTime_RFHM" SG_ 274 LatAcceleration 0;
BA_ "GenSigTimeoutTime_SGW" SG_ 274 LatAcceleration 0;
BA_ "GenSigStartValue" SG_ 274 LongAcceleration 4095;
BA_ "GenSigTimeoutTime_AGSM" SG_ 274 LongAcceleration 0;
BA_ "GenSigTimeoutTime_ASBS" SG_ 274 LongAcceleration 0;
BA_ "GenSigTimeoutTime_BCM" SG_ 274 LongAcceleration 0;
BA_ "GenSigTimeoutTime_BSM" SG_ 274 LongAcceleration 0;
BA_ "GenSigTimeoutTime_CADM" SG_ 274 LongAcceleration 0;
BA_ "GenSigTimeoutTime_DMSM" SG_ 274 LongAcceleration 0;
BA_ "GenSigTimeoutTime_ELSDM" SG_ 274 LongAcceleration 0;
BA_ "GenSigTimeoutTime_ESL" SG_ 274 LongAcceleration 0;
BA_ "GenSigTimeoutTime_GNMM" SG_ 274 LongAcceleration 0;
BA_ "GenSigTimeoutTime_IPC" SG_ 274 LongAcceleration 0;
BA_ "GenSigTimeoutTime_RFHM" SG_ 274 LongAcceleration 0;
BA_ "GenSigTimeoutTime_SGW" SG_ 274 LongAcceleration 0;
BA_ "GenSigTimeoutTime_ADCAM" SG_ 156 Day1_TLM 0;
BA_ "GenSigTimeoutTime_VDCM" SG_ 156 Day1_TLM 0;
BA_ "GenSigTimeoutTime_IPC" SG_ 156 Day1_TLM 0;
BA_ "GenSigTimeoutTime_ADCAM" SG_ 156 Day2_TLM 0;
BA_ "GenSigTimeoutTime_VDCM" SG_ 156 Day2_TLM 0;
BA_ "GenSigTimeoutTime_IPC" SG_ 156 Day2_TLM 0;
BA_ "GenSigTimeoutTime_ADCAM" SG_ 156 Hour1_TLM 0;
BA_ "GenSigTimeoutTime_VDCM" SG_ 156 Hour1_TLM 0;
BA_ "GenSigTimeoutTime_ADCAM" SG_ 156 Hour2_TLM 0;
BA_ "GenSigTimeoutTime_VDCM" SG_ 156 Hour2_TLM 0;
BA_ "GenSigTimeoutTime_ADCAM" SG_ 156 Minute1_TLM 0;
BA_ "GenSigTimeoutTime_VDCM" SG_ 156 Minute1_TLM 0;
BA_ "GenSigTimeoutTime_ADCAM" SG_ 156 Minute2_TLM 0;
BA_ "GenSigTimeoutTime_VDCM" SG_ 156 Minute2_TLM 0;
BA_ "GenSigTimeoutTime_ADCAM" SG_ 156 Month1_TLM 0;
BA_ "GenSigTimeoutTime_VDCM" SG_ 156 Month1_TLM 0;
BA_ "GenSigTimeoutTime_IPC" SG_ 156 Month1_TLM 0;
BA_ "GenSigTimeoutTime_ADCAM" SG_ 156 Month2_TLM 0;
BA_ "GenSigTimeoutTime_VDCM" SG_ 156 Month2_TLM 0;
BA_ "GenSigTimeoutTime_IPC" SG_ 156 Month2_TLM 0;
BA_ "GenSigTimeoutTime_ADCAM" SG_ 156 Year1_TLM 0;
BA_ "GenSigTimeoutTime_VDCM" SG_ 156 Year1_TLM 0;
BA_ "GenSigTimeoutTime_IPC" SG_ 156 Year1_TLM 0;
BA_ "GenSigTimeoutTime_ADCAM" SG_ 156 Year2_TLM 0;
BA_ "GenSigTimeoutTime_VDCM" SG_ 156 Year2_TLM 0;
BA_ "GenSigTimeoutTime_IPC" SG_ 156 Year2_TLM 0;
BA_ "GenSigTimeoutTime_ADCAM" SG_ 156 Year3_TLM 0;
BA_ "GenSigTimeoutTime_VDCM" SG_ 156 Year3_TLM 0;
BA_ "GenSigTimeoutTime_IPC" SG_ 156 Year3_TLM 0;
BA_ "GenSigTimeoutTime_ADCAM" SG_ 156 Year4_TLM 0;
BA_ "GenSigTimeoutTime_VDCM" SG_ 156 Year4_TLM 0;
BA_ "GenSigTimeoutTime_IPC" SG_ 156 Year4_TLM 0;
BA_ "GenSigSendType" SG_ 156 Day1_TLM 1;
BA_ "GenSigTimeoutTime_AGSM" SG_ 156 Day1_TLM 0;
BA_ "GenSigTimeoutTime_ASBS" SG_ 156 Day1_TLM 0;
BA_ "GenSigTimeoutTime_BCM" SG_ 156 Day1_TLM 0;
BA_ "GenSigTimeoutTime_BSM" SG_ 156 Day1_TLM 0;
BA_ "GenSigTimeoutTime_CADM" SG_ 156 Day1_TLM 0;
BA_ "GenSigTimeoutTime_DMSM" SG_ 156 Day1_TLM 0;
BA_ "GenSigTimeoutTime_DTCM" SG_ 156 Day1_TLM 0;
BA_ "GenSigTimeoutTime_ELSDM" SG_ 156 Day1_TLM 0;
BA_ "GenSigTimeoutTime_ESL" SG_ 156 Day1_TLM 0;
BA_ "GenSigTimeoutTime_GNMM" SG_ 156 Day1_TLM 0;
BA_ "GenSigTimeoutTime_SGW" SG_ 156 Day1_TLM 0;
BA_ "GenSigTimeoutTime_TCM" SG_ 156 Day1_TLM 0;
BA_ "GenSigTimeoutTime_AGSM" SG_ 156 Day2_TLM 0;
BA_ "GenSigTimeoutTime_ASBS" SG_ 156 Day2_TLM 0;
BA_ "GenSigTimeoutTime_BCM" SG_ 156 Day2_TLM 0;
BA_ "GenSigTimeoutTime_BSM" SG_ 156 Day2_TLM 0;
BA_ "GenSigTimeoutTime_CADM" SG_ 156 Day2_TLM 0;
BA_ "GenSigTimeoutTime_DMSM" SG_ 156 Day2_TLM 0;
BA_ "GenSigTimeoutTime_DTCM" SG_ 156 Day2_TLM 0;
BA_ "GenSigTimeoutTime_ELSDM" SG_ 156 Day2_TLM 0;
BA_ "GenSigTimeoutTime_ESL" SG_ 156 Day2_TLM 0;
BA_ "GenSigTimeoutTime_GNMM" SG_ 156 Day2_TLM 0;
BA_ "GenSigTimeoutTime_SGW" SG_ 156 Day2_TLM 0;
BA_ "GenSigTimeoutTime_TCM" SG_ 156 Day2_TLM 0;
BA_ "GenSigTimeoutTime_AGSM" SG_ 156 Hour1_TLM 0;
BA_ "GenSigTimeoutTime_ASBS" SG_ 156 Hour1_TLM 0;
BA_ "GenSigTimeoutTime_BCM" SG_ 156 Hour1_TLM 0;
BA_ "GenSigTimeoutTime_BSM" SG_ 156 Hour1_TLM 0;
BA_ "GenSigTimeoutTime_CADM" SG_ 156 Hour1_TLM 0;
BA_ "GenSigTimeoutTime_DMSM" SG_ 156 Hour1_TLM 0;
BA_ "GenSigTimeoutTime_DTCM" SG_ 156 Hour1_TLM 0;
BA_ "GenSigTimeoutTime_ELSDM" SG_ 156 Hour1_TLM 0;
BA_ "GenSigTimeoutTime_ESL" SG_ 156 Hour1_TLM 0;
BA_ "GenSigTimeoutTime_GNMM" SG_ 156 Hour1_TLM 0;
BA_ "GenSigTimeoutTime_SGW" SG_ 156 Hour1_TLM 0;
BA_ "GenSigTimeoutTime_TCM" SG_ 156 Hour1_TLM 0;
BA_ "GenSigTimeoutTime_AGSM" SG_ 156 Hour2_TLM 0;
BA_ "GenSigTimeoutTime_ASBS" SG_ 156 Hour2_TLM 0;
BA_ "GenSigTimeoutTime_BCM" SG_ 156 Hour2_TLM 0;
BA_ "GenSigTimeoutTime_BSM" SG_ 156 Hour2_TLM 0;
BA_ "GenSigTimeoutTime_CADM" SG_ 156 Hour2_TLM 0;
BA_ "GenSigTimeoutTime_DMSM" SG_ 156 Hour2_TLM 0;
BA_ "GenSigTimeoutTime_DTCM" SG_ 156 Hour2_TLM 0;
BA_ "GenSigTimeoutTime_ELSDM" SG_ 156 Hour2_TLM 0;
BA_ "GenSigTimeoutTime_ESL" SG_ 156 Hour2_TLM 0;
BA_ "GenSigTimeoutTime_GNMM" SG_ 156 Hour2_TLM 0;
BA_ "GenSigTimeoutTime_SGW" SG_ 156 Hour2_TLM 0;
BA_ "GenSigTimeoutTime_TCM" SG_ 156 Hour2_TLM 0;
BA_ "GenSigTimeoutTime_AGSM" SG_ 156 Minute1_TLM 0;
BA_ "GenSigTimeoutTime_ASBS" SG_ 156 Minute1_TLM 0;
BA_ "GenSigTimeoutTime_BCM" SG_ 156 Minute1_TLM 0;
BA_ "GenSigTimeoutTime_BSM" SG_ 156 Minute1_TLM 0;
BA_ "GenSigTimeoutTime_CADM" SG_ 156 Minute1_TLM 0;
BA_ "GenSigTimeoutTime_DMSM" SG_ 156 Minute1_TLM 0;
BA_ "GenSigTimeoutTime_DTCM" SG_ 156 Minute1_TLM 0;
BA_ "GenSigTimeoutTime_ELSDM" SG_ 156 Minute1_TLM 0;
BA_ "GenSigTimeoutTime_ESL" SG_ 156 Minute1_TLM 0;
BA_ "GenSigTimeoutTime_GNMM" SG_ 156 Minute1_TLM 0;
BA_ "GenSigTimeoutTime_SGW" SG_ 156 Minute1_TLM 0;
BA_ "GenSigTimeoutTime_TCM" SG_ 156 Minute1_TLM 0;
BA_ "GenSigTimeoutTime_AGSM" SG_ 156 Minute2_TLM 0;
BA_ "GenSigTimeoutTime_ASBS" SG_ 156 Minute2_TLM 0;
BA_ "GenSigTimeoutTime_BCM" SG_ 156 Minute2_TLM 0;
BA_ "GenSigTimeoutTime_BSM" SG_ 156 Minute2_TLM 0;
BA_ "GenSigTimeoutTime_CADM" SG_ 156 Minute2_TLM 0;
BA_ "GenSigTimeoutTime_DMSM" SG_ 156 Minute2_TLM 0;
BA_ "GenSigTimeoutTime_DTCM" SG_ 156 Minute2_TLM 0;
BA_ "GenSigTimeoutTime_ELSDM" SG_ 156 Minute2_TLM 0;
BA_ "GenSigTimeoutTime_ESL" SG_ 156 Minute2_TLM 0;
BA_ "GenSigTimeoutTime_GNMM" SG_ 156 Minute2_TLM 0;
BA_ "GenSigTimeoutTime_SGW" SG_ 156 Minute2_TLM 0;
BA_ "GenSigTimeoutTime_TCM" SG_ 156 Minute2_TLM 0;
BA_ "GenSigTimeoutTime_AGSM" SG_ 156 Month1_TLM 0;
BA_ "GenSigTimeoutTime_ASBS" SG_ 156 Month1_TLM 0;
BA_ "GenSigTimeoutTime_BCM" SG_ 156 Month1_TLM 0;
BA_ "GenSigTimeoutTime_BSM" SG_ 156 Month1_TLM 0;
BA_ "GenSigTimeoutTime_CADM" SG_ 156 Month1_TLM 0;
BA_ "GenSigTimeoutTime_DMSM" SG_ 156 Month1_TLM 0;
BA_ "GenSigTimeoutTime_DTCM" SG_ 156 Month1_TLM 0;
BA_ "GenSigTimeoutTime_ELSDM" SG_ 156 Month1_TLM 0;
BA_ "GenSigTimeoutTime_ESL" SG_ 156 Month1_TLM 0;
BA_ "GenSigTimeoutTime_GNMM" SG_ 156 Month1_TLM 0;
BA_ "GenSigTimeoutTime_SGW" SG_ 156 Month1_TLM 0;
BA_ "GenSigTimeoutTime_TCM" SG_ 156 Month1_TLM 0;
BA_ "GenSigTimeoutTime_AGSM" SG_ 156 Month2_TLM 0;
BA_ "GenSigTimeoutTime_ASBS" SG_ 156 Month2_TLM 0;
BA_ "GenSigTimeoutTime_BCM" SG_ 156 Month2_TLM 0;
BA_ "GenSigTimeoutTime_BSM" SG_ 156 Month2_TLM 0;
BA_ "GenSigTimeoutTime_CADM" SG_ 156 Month2_TLM 0;
BA_ "GenSigTimeoutTime_DMSM" SG_ 156 Month2_TLM 0;
BA_ "GenSigTimeoutTime_DTCM" SG_ 156 Month2_TLM 0;
BA_ "GenSigTimeoutTime_ELSDM" SG_ 156 Month2_TLM 0;
BA_ "GenSigTimeoutTime_ESL" SG_ 156 Month2_TLM 0;
BA_ "GenSigTimeoutTime_GNMM" SG_ 156 Month2_TLM 0;
BA_ "GenSigTimeoutTime_SGW" SG_ 156 Month2_TLM 0;
BA_ "GenSigTimeoutTime_TCM" SG_ 156 Month2_TLM 0;
BA_ "GenSigTimeoutTime_ADCAM" SG_ 264 EngineFanRequestActivation 0;
BA_ "GenSigTimeoutTime_EVCU2" SG_ 264 EngineFanRequestActivation 0;
BA_ "GenSigTimeoutTime_VDCM" SG_ 264 EngineFanRequestActivation 0;
BA_ "GenSigTimeoutTime_ADCAM" SG_ 264 CRC_EPS1 0;
BA_ "GenSigTimeoutTime_VDCM" SG_ 264 CRC_EPS1 0;
BA_ "GenSigTimeoutTime_ADCAM" SG_ 264 MessageCounter_EPS1 0;
BA_ "GenSigTimeoutTime_VDCM" SG_ 264 MessageCounter_EPS1 0;
BA_ "GenSigTimeoutTime_ADCAM" SG_ 264 LwsSpeed 0;
BA_ "GenSigTimeoutTime_VDCM" SG_ 264 LwsSpeed 0;
BA_ "GenSigTimeoutTime_DTCM" SG_ 264 LwsSpeed 0;
BA_ "GenSigTimeoutTime_ADCAM" SG_ 264 LwsAngle 0;
BA_ "GenSigTimeoutTime_VDCM" SG_ 264 LwsAngle 0;
BA_ "GenSigTimeoutTime_AGSM" SG_ 264 EngineFanRequestActivation 0;
BA_ "GenSigTimeoutTime_ASBS" SG_ 264 EngineFanRequestActivation 0;
BA_ "GenSigTimeoutTime_BCM" SG_ 264 EngineFanRequestActivation 0;
BA_ "GenSigTimeoutTime_BSM" SG_ 264 EngineFanRequestActivation 0;
BA_ "GenSigTimeoutTime_CADM" SG_ 264 EngineFanRequestActivation 0;
BA_ "GenSigTimeoutTime_DMSM" SG_ 264 EngineFanRequestActivation 0;
BA_ "GenSigTimeoutTime_DTCM" SG_ 264 EngineFanRequestActivation 0;
BA_ "GenSigTimeoutTime_ELSDM" SG_ 264 EngineFanRequestActivation 0;
BA_ "GenSigTimeoutTime_ESL" SG_ 264 EngineFanRequestActivation 0;
BA_ "GenSigTimeoutTime_GNMM" SG_ 264 EngineFanRequestActivation 0;
BA_ "GenSigTimeoutTime_HCP" SG_ 264 EngineFanRequestActivation 0;
BA_ "GenSigTimeoutTime_IPC" SG_ 264 EngineFanRequestActivation 0;
BA_ "GenSigTimeoutTime_RFHM" SG_ 264 EngineFanRequestActivation 0;
BA_ "GenSigTimeoutTime_SGW" SG_ 264 EngineFanRequestActivation 0;
BA_ "GenSigTimeoutTime_TCM" SG_ 264 EngineFanRequestActivation 0;
BA_ "GenSigTimeoutTime_AGSM" SG_ 264 CRC_EPS1 0;
BA_ "GenSigTimeoutTime_ASBS" SG_ 264 CRC_EPS1 0;
BA_ "GenSigTimeoutTime_BCM" SG_ 264 CRC_EPS1 0;
BA_ "GenSigTimeoutTime_CADM" SG_ 264 CRC_EPS1 0;
BA_ "GenSigTimeoutTime_ELSDM" SG_ 264 CRC_EPS1 0;
BA_ "GenSigTimeoutTime_ESL" SG_ 264 CRC_EPS1 0;
BA_ "GenSigTimeoutTime_GNMM" SG_ 264 CRC_EPS1 0;
BA_ "GenSigTimeoutTime_HCP" SG_ 264 CRC_EPS1 0;
BA_ "GenSigTimeoutTime_IPC" SG_ 264 CRC_EPS1 0;
BA_ "GenSigTimeoutTime_RFHM" SG_ 264 CRC_EPS1 0;
BA_ "GenSigTimeoutTime_SGW" SG_ 264 CRC_EPS1 0;
BA_ "GenSigTimeoutTime_AGSM" SG_ 264 MessageCounter_EPS1 0;
BA_ "GenSigTimeoutTime_ASBS" SG_ 264 MessageCounter_EPS1 0;
BA_ "GenSigTimeoutTime_BCM" SG_ 264 MessageCounter_EPS1 0;
BA_ "GenSigTimeoutTime_CADM" SG_ 264 MessageCounter_EPS1 0;
BA_ "GenSigTimeoutTime_ELSDM" SG_ 264 MessageCounter_EPS1 0;
BA_ "GenSigTimeoutTime_ESL" SG_ 264 MessageCounter_EPS1 0;
BA_ "GenSigTimeoutTime_GNMM" SG_ 264 MessageCounter_EPS1 0;
BA_ "GenSigTimeoutTime_HCP" SG_ 264 MessageCounter_EPS1 0;
BA_ "GenSigTimeoutTime_IPC" SG_ 264 MessageCounter_EPS1 0;
BA_ "GenSigTimeoutTime_RFHM" SG_ 264 MessageCounter_EPS1 0;
BA_ "GenSigTimeoutTime_SGW" SG_ 264 MessageCounter_EPS1 0;
BA_ "GenSigTimeoutTime_AGSM" SG_ 264 LwsSpeed 0;
BA_ "GenSigTimeoutTime_ASBS" SG_ 264 LwsSpeed 0;
BA_ "GenSigTimeoutTime_BCM" SG_ 264 LwsSpeed 0;
BA_ "GenSigTimeoutTime_BSM" SG_ 264 LwsSpeed 0;
BA_ "GenSigTimeoutTime_CADM" SG_ 264 LwsSpeed 0;
BA_ "GenSigTimeoutTime_DMSM" SG_ 264 LwsSpeed 0;
BA_ "GenSigTimeoutTime_ELSDM" SG_ 264 LwsSpeed 0;
BA_ "GenSigTimeoutTime_ESL" SG_ 264 LwsSpeed 0;
BA_ "GenSigTimeoutTime_GNMM" SG_ 264 LwsSpeed 0;
BA_ "GenSigTimeoutTime_HCP" SG_ 264 LwsSpeed 0;
BA_ "GenSigTimeoutTime_IPC" SG_ 264 LwsSpeed 0;
BA_ "GenSigTimeoutTime_RFHM" SG_ 264 LwsSpeed 0;
BA_ "GenSigTimeoutTime_SGW" SG_ 264 LwsSpeed 0;
BA_ "GenSigTimeoutTime_TCM" SG_ 264 LwsSpeed 0;
BA_ "GenSigTimeoutTime_AGSM" SG_ 264 LwsAngle 0;
BA_ "GenSigTimeoutTime_ASBS" SG_ 264 LwsAngle 0;
BA_ "GenSigTimeoutTime_BCM" SG_ 264 LwsAngle 0;
BA_ "GenSigTimeoutTime_CADM" SG_ 264 LwsAngle 0;
BA_ "GenSigTimeoutTime_ELSDM" SG_ 264 LwsAngle 0;
BA_ "GenSigTimeoutTime_AGSM" SG_ 156 Year1_TLM 0;
BA_ "GenSigTimeoutTime_ASBS" SG_ 156 Year1_TLM 0;
BA_ "GenSigTimeoutTime_BCM" SG_ 156 Year1_TLM 0;
BA_ "GenSigTimeoutTime_BSM" SG_ 156 Year1_TLM 0;
BA_ "GenSigTimeoutTime_CADM" SG_ 156 Year1_TLM 0;
BA_ "GenSigTimeoutTime_DMSM" SG_ 156 Year1_TLM 0;
BA_ "GenSigTimeoutTime_DTCM" SG_ 156 Year1_TLM 0;
BA_ "GenSigTimeoutTime_ELSDM" SG_ 156 Year1_TLM 0;
BA_ "GenSigTimeoutTime_ESL" SG_ 156 Year1_TLM 0;
BA_ "GenSigTimeoutTime_GNMM" SG_ 156 Year1_TLM 0;
BA_ "GenSigTimeoutTime_SGW" SG_ 156 Year1_TLM 0;
BA_ "GenSigTimeoutTime_TCM" SG_ 156 Year1_TLM 0;
BA_ "GenSigTimeoutTime_AGSM" SG_ 156 Year2_TLM 0;
BA_ "GenSigTimeoutTime_ASBS" SG_ 156 Year2_TLM 0;
BA_ "GenSigTimeoutTime_BCM" SG_ 156 Year2_TLM 0;
BA_ "GenSigTimeoutTime_BSM" SG_ 156 Year2_TLM 0;
BA_ "GenSigTimeoutTime_CADM" SG_ 156 Year2_TLM 0;
BA_ "GenSigTimeoutTime_DMSM" SG_ 156 Year2_TLM 0;
BA_ "GenSigTimeoutTime_DTCM" SG_ 156 Year2_TLM 0;
BA_ "GenSigTimeoutTime_ELSDM" SG_ 156 Year2_TLM 0;
BA_ "GenSigTimeoutTime_ESL" SG_ 156 Year2_TLM 0;
BA_ "GenSigTimeoutTime_GNMM" SG_ 156 Year2_TLM 0;
BA_ "GenSigTimeoutTime_SGW" SG_ 156 Year2_TLM 0;
BA_ "GenSigTimeoutTime_TCM" SG_ 156 Year2_TLM 0;
BA_ "GenSigTimeoutTime_AGSM" SG_ 156 Year3_TLM 0;
BA_ "GenSigTimeoutTime_ASBS" SG_ 156 Year3_TLM 0;
BA_ "GenSigTimeoutTime_BCM" SG_ 156 Year3_TLM 0;
BA_ "GenSigTimeoutTime_BSM" SG_ 156 Year3_TLM 0;
BA_ "GenSigTimeoutTime_CADM" SG_ 156 Year3_TLM 0;
BA_ "GenSigTimeoutTime_DMSM" SG_ 156 Year3_TLM 0;
BA_ "GenSigTimeoutTime_DTCM" SG_ 156 Year3_TLM 0;
BA_ "GenSigTimeoutTime_ELSDM" SG_ 156 Year3_TLM 0;
BA_ "GenSigTimeoutTime_ESL" SG_ 156 Year3_TLM 0;
BA_ "GenSigTimeoutTime_GNMM" SG_ 156 Year3_TLM 0;
BA_ "GenSigTimeoutTime_SGW" SG_ 156 Year3_TLM 0;
BA_ "GenSigTimeoutTime_TCM" SG_ 156 Year3_TLM 0;
BA_ "GenSigTimeoutTime_AGSM" SG_ 156 Year4_TLM 0;
BA_ "GenSigTimeoutTime_ASBS" SG_ 156 Year4_TLM 0;
BA_ "GenSigTimeoutTime_BCM" SG_ 156 Year4_TLM 0;
BA_ "GenSigTimeoutTime_BSM" SG_ 156 Year4_TLM 0;
BA_ "GenSigTimeoutTime_CADM" SG_ 156 Year4_TLM 0;
BA_ "GenSigTimeoutTime_DMSM" SG_ 156 Year4_TLM 0;
BA_ "GenSigTimeoutTime_DTCM" SG_ 156 Year4_TLM 0;
BA_ "GenSigTimeoutTime_ELSDM" SG_ 156 Year4_TLM 0;
BA_ "GenSigTimeoutTime_ESL" SG_ 156 Year4_TLM 0;
BA_ "GenSigTimeoutTime_GNMM" SG_ 156 Year4_TLM 0;
BA_ "GenSigTimeoutTime_SGW" SG_ 156 Year4_TLM 0;
BA_ "GenSigTimeoutTime_TCM" SG_ 156 Year4_TLM 0;
BA_ "GenSigTimeoutTime_EVCU2" SG_ 520 MessageCounter_TRANSM2 0;
BA_ "GenSigTimeoutTime_VDCM" SG_ 520 MessageCounter_TRANSM2 0;
BA_ "GenSigTimeoutTime_BCM" SG_ 520 MessageCounter_TRANSM2 0;
BA_ "GenSigTimeoutTime_IPC" SG_ 520 MessageCounter_TRANSM2 0;
BA_ "GenSigTimeoutTime_EVCU2" SG_ 520 CRC_TRANSM2 0;
BA_ "GenSigTimeoutTime_VDCM" SG_ 520 CRC_TRANSM2 0;
BA_ "GenSigTimeoutTime_BCM" SG_ 520 CRC_TRANSM2 0;
BA_ "GenSigTimeoutTime_IPC" SG_ 520 CRC_TRANSM2 0;
BA_ "GenSigTimeoutTime_SGW" SG_ 520 CRC_TRANSM2 0;
BA_ "GenSigTimeoutTime_EVCU2" SG_ 520 GearEngagedForDisplay 0;
BA_ "GenSigTimeoutTime_VDCM" SG_ 520 GearEngagedForDisplay 0;
BA_ "GenSigTimeoutTime_ADCAM" SG_ 520 TransmissionTemperature 0;
BA_ "GenSigTimeoutTime_EVCU2" SG_ 520 TransmissionTemperature 0;
BA_ "GenSigTimeoutTime_VDCM" SG_ 520 TransmissionTemperature 0;
BA_ "GenSigTimeoutTime_ASBS" SG_ 520 APCM_Rq 0;
BA_ "GenSigTimeoutTime_BCM" SG_ 520 APCM_Rq 0;
BA_ "GenSigTimeoutTime_BSM" SG_ 520 APCM_Rq 0;
BA_ "GenSigTimeoutTime_CADM" SG_ 520 APCM_Rq 0;
BA_ "GenSigTimeoutTime_DMSM" SG_ 520 APCM_Rq 0;
BA_ "GenSigTimeoutTime_DTCM" SG_ 520 APCM_Rq 0;
BA_ "GenSigTimeoutTime_ELSDM" SG_ 520 APCM_Rq 0;
BA_ "GenSigTimeoutTime_ESL" SG_ 520 APCM_Rq 0;
BA_ "GenSigTimeoutTime_GNMM" SG_ 520 APCM_Rq 0;
BA_ "GenSigTimeoutTime_HCP" SG_ 520 APCM_Rq 0;
BA_ "GenSigTimeoutTime_IPC" SG_ 520 APCM_Rq 0;
BA_ "GenSigTimeoutTime_RFHM" SG_ 520 APCM_Rq 0;
BA_ "GenSigTimeoutTime_TCM" SG_ 520 APCM_Rq 0;
BA_ "GenSigStartValue" SG_ 520 OUTPUT_SPEED 65535;
BA_ "GenSigTimeoutTime_AGSM" SG_ 520 OUTPUT_SPEED 0;
BA_ "GenSigTimeoutTime_ASBS" SG_ 520 OUTPUT_SPEED 0;
BA_ "GenSigTimeoutTime_BCM" SG_ 520 OUTPUT_SPEED 0;
BA_ "GenSigTimeoutTime_CADM" SG_ 520 OUTPUT_SPEED 0;
BA_ "GenSigTimeoutTime_DMSM" SG_ 520 OUTPUT_SPEED 0;
BA_ "GenSigTimeoutTime_ELSDM" SG_ 520 OUTPUT_SPEED 0;
BA_ "GenSigTimeoutTime_ESL" SG_ 520 OUTPUT_SPEED 0;
BA_ "GenSigTimeoutTime_GNMM" SG_ 520 OUTPUT_SPEED 0;
BA_ "GenSigTimeoutTime_IPC" SG_ 520 OUTPUT_SPEED 0;
BA_ "GenSigTimeoutTime_RFHM" SG_ 520 OUTPUT_SPEED 0;
BA_ "GenSigTimeoutTime_TCM" SG_ 520 OUTPUT_SPEED 0;
BA_ "GenSigTimeoutTime_ASBS" SG_ 520 MessageCounter_TRANSM2 0;
BA_ "GenSigTimeoutTime_DMSM" SG_ 520 MessageCounter_TRANSM2 0;
BA_ "GenSigTimeoutTime_ELSDM" SG_ 520 MessageCounter_TRANSM2 0;
BA_ "GenSigTimeoutTime_ESL" SG_ 520 MessageCounter_TRANSM2 0;
BA_ "GenSigTimeoutTime_RFHM" SG_ 520 MessageCounter_TRANSM2 0;
BA_ "GenSigTimeoutTime_TCM" SG_ 520 MessageCounter_TRANSM2 0;
BA_ "GenSigTimeoutTime_ASBS" SG_ 520 CRC_TRANSM2 0;
BA_ "GenSigTimeoutTime_DMSM" SG_ 520 CRC_TRANSM2 0;
BA_ "GenSigTimeoutTime_ELSDM" SG_ 520 CRC_TRANSM2 0;
BA_ "GenSigTimeoutTime_ESL" SG_ 520 CRC_TRANSM2 0;
BA_ "GenSigTimeoutTime_RFHM" SG_ 520 CRC_TRANSM2 0;
BA_ "GenSigTimeoutTime_TCM" SG_ 520 CRC_TRANSM2 0;
BA_ "GenSigTimeoutTime_AGSM" SG_ 520 EngShutOffRq_TCM 0;
BA_ "GenSigTimeoutTime_ASBS" SG_ 520 EngShutOffRq_TCM 0;
BA_ "GenSigTimeoutTime_BCM" SG_ 520 EngShutOffRq_TCM 0;
BA_ "GenSigTimeoutTime_BSM" SG_ 520 EngShutOffRq_TCM 0;
BA_ "GenSigTimeoutTime_CADM" SG_ 520 EngShutOffRq_TCM 0;
BA_ "GenSigTimeoutTime_DMSM" SG_ 520 EngShutOffRq_TCM 0;
BA_ "GenSigTimeoutTime_DTCM" SG_ 520 EngShutOffRq_TCM 0;
BA_ "GenSigTimeoutTime_ELSDM" SG_ 520 EngShutOffRq_TCM 0;
BA_ "GenSigTimeoutTime_ESL" SG_ 520 EngShutOffRq_TCM 0;
BA_ "GenSigTimeoutTime_GNMM" SG_ 520 EngShutOffRq_TCM 0;
BA_ "GenSigTimeoutTime_IPC" SG_ 520 EngShutOffRq_TCM 0;
BA_ "GenSigTimeoutTime_RFHM" SG_ 520 EngShutOffRq_TCM 0;
BA_ "GenSigTimeoutTime_SGW" SG_ 520 EngShutOffRq_TCM 0;
BA_ "GenSigTimeoutTime_TCM" SG_ 520 EngShutOffRq_TCM 0;
BA_ "GenSigStartValue" SG_ 520 AirFlowRequest_TCM 127;
BA_ "GenSigTimeoutTime_AGSM" SG_ 520 AirFlowRequest_TCM 0;
BA_ "GenSigTimeoutTime_ASBS" SG_ 520 AirFlowRequest_TCM 0;
BA_ "GenSigTimeoutTime_BCM" SG_ 520 AirFlowRequest_TCM 0;
BA_ "GenSigTimeoutTime_BSM" SG_ 520 AirFlowRequest_TCM 0;
BA_ "GenSigTimeoutTime_CADM" SG_ 520 AirFlowRequest_TCM 0;
BA_ "GenSigTimeoutTime_DMSM" SG_ 520 AirFlowRequest_TCM 0;
BA_ "GenSigTimeoutTime_DTCM" SG_ 520 AirFlowRequest_TCM 0;
BA_ "GenSigTimeoutTime_ELSDM" SG_ 520 AirFlowRequest_TCM 0;
BA_ "GenSigTimeoutTime_ESL" SG_ 520 AirFlowRequest_TCM 0;
BA_ "GenSigTimeoutTime_GNMM" SG_ 520 AirFlowRequest_TCM 0;
BA_ "GenSigTimeoutTime_HCP" SG_ 520 AirFlowRequest_TCM 0;
BA_ "GenSigTimeoutTime_IPC" SG_ 520 AirFlowRequest_TCM 0;
BA_ "GenSigTimeoutTime_RFHM" SG_ 520 AirFlowRequest_TCM 0;
BA_ "GenSigTimeoutTime_SGW" SG_ 520 AirFlowRequest_TCM 0;
BA_ "GenSigTimeoutTime_TCM" SG_ 520 AirFlowRequest_TCM 0;
BA_ "GenSigStartValue" SG_ 520 GearEngagedForDisplay 31;
BA_ "GenSigTimeoutTime_ASBS" SG_ 520 GearEngagedForDisplay 0;
BA_ "GenSigTimeoutTime_DMSM" SG_ 520 GearEngagedForDisplay 0;
BA_ "GenSigTimeoutTime_ELSDM" SG_ 520 GearEngagedForDisplay 0;
BA_ "GenSigTimeoutTime_ESL" SG_ 520 GearEngagedForDisplay 0;
BA_ "GenSigTimeoutTime_TCM" SG_ 520 GearEngagedForDisplay 0;
BA_ "GenSigTimeoutTime_AGSM" SG_ 520 Trans_ESS_Inhibit 0;
BA_ "GenSigTimeoutTime_ASBS" SG_ 520 Trans_ESS_Inhibit 0;
BA_ "GenSigTimeoutTime_BCM" SG_ 520 Trans_ESS_Inhibit 0;
BA_ "GenSigTimeoutTime_BSM" SG_ 520 Trans_ESS_Inhibit 0;
BA_ "GenSigTimeoutTime_CADM" SG_ 520 Trans_ESS_Inhibit 0;
BA_ "GenSigTimeoutTime_DMSM" SG_ 520 Trans_ESS_Inhibit 0;
BA_ "GenSigTimeoutTime_DTCM" SG_ 520 Trans_ESS_Inhibit 0;
BA_ "GenSigTimeoutTime_ELSDM" SG_ 520 Trans_ESS_Inhibit 0;
BA_ "GenSigTimeoutTime_ESL" SG_ 520 Trans_ESS_Inhibit 0;
BA_ "GenSigTimeoutTime_GNMM" SG_ 520 Trans_ESS_Inhibit 0;
BA_ "GenSigTimeoutTime_HCP" SG_ 520 Trans_ESS_Inhibit 0;
BA_ "GenSigTimeoutTime_IPC" SG_ 520 Trans_ESS_Inhibit 0;
BA_ "GenSigTimeoutTime_RFHM" SG_ 520 Trans_ESS_Inhibit 0;
BA_ "GenSigTimeoutTime_SGW" SG_ 520 Trans_ESS_Inhibit 0;
BA_ "GenSigTimeoutTime_TCM" SG_ 520 Trans_ESS_Inhibit 0;
BA_ "GenSigTimeoutTime_AGSM" SG_ 520 TransmissionTemperature 0;
BA_ "GenSigTimeoutTime_ASBS" SG_ 520 TransmissionTemperature 0;
BA_ "GenSigTimeoutTime_BCM" SG_ 520 TransmissionTemperature 0;
BA_ "GenSigTimeoutTime_BSM" SG_ 520 TransmissionTemperature 0;
BA_ "GenSigTimeoutTime_CADM" SG_ 520 TransmissionTemperature 0;
BA_ "GenSigTimeoutTime_DMSM" SG_ 520 TransmissionTemperature 0;
BA_ "GenSigTimeoutTime_ELSDM" SG_ 520 TransmissionTemperature 0;
BA_ "GenSigTimeoutTime_ESL" SG_ 520 TransmissionTemperature 0;
BA_ "GenSigTimeoutTime_GNMM" SG_ 520 TransmissionTemperature 0;
BA_ "GenSigTimeoutTime_RFHM" SG_ 520 TransmissionTemperature 0;
BA_ "GenSigTimeoutTime_TCM" SG_ 520 TransmissionTemperature 0;
BA_ "GenSigTimeoutTime_AGSM" SG_ 520 TransReadyForESS 0;
BA_ "GenSigTimeoutTime_ASBS" SG_ 520 TransReadyForESS 0;
BA_ "GenSigTimeoutTime_BSM" SG_ 520 TransReadyForESS 0;
BA_ "GenSigTimeoutTime_CADM" SG_ 520 TransReadyForESS 0;
BA_ "GenSigTimeoutTime_DMSM" SG_ 520 TransReadyForESS 0;
BA_ "GenSigTimeoutTime_DTCM" SG_ 520 TransReadyForESS 0;
BA_ "GenSigTimeoutTime_ELSDM" SG_ 520 TransReadyForESS 0;
BA_ "GenSigTimeoutTime_ESL" SG_ 520 TransReadyForESS 0;
BA_ "GenSigTimeoutTime_GNMM" SG_ 520 TransReadyForESS 0;
BA_ "GenSigTimeoutTime_HCP" SG_ 520 TransReadyForESS 0;
BA_ "GenSigTimeoutTime_IPC" SG_ 520 TransReadyForESS 0;
BA_ "GenSigTimeoutTime_RFHM" SG_ 520 TransReadyForESS 0;
BA_ "GenSigTimeoutTime_SGW" SG_ 520 TransReadyForESS 0;
BA_ "GenSigTimeoutTime_TCM" SG_ 520 TransReadyForESS 0;
BA_ "GenSigTimeoutTime_AGSM" SG_ 520 Trns_EMCC_Achvd 0;
BA_ "GenSigTimeoutTime_ASBS" SG_ 520 Trns_EMCC_Achvd 0;
BA_ "GenSigTimeoutTime_BCM" SG_ 520 Trns_EMCC_Achvd 0;
BA_ "GenSigTimeoutTime_BSM" SG_ 520 Trns_EMCC_Achvd 0;
BA_ "GenSigTimeoutTime_CADM" SG_ 520 Trns_EMCC_Achvd 0;
BA_ "GenSigTimeoutTime_DMSM" SG_ 520 Trns_EMCC_Achvd 0;
BA_ "GenSigTimeoutTime_DTCM" SG_ 520 Trns_EMCC_Achvd 0;
BA_ "GenSigTimeoutTime_ELSDM" SG_ 520 Trns_EMCC_Achvd 0;
BA_ "GenSigTimeoutTime_ESL" SG_ 520 Trns_EMCC_Achvd 0;
BA_ "GenSigTimeoutTime_GNMM" SG_ 520 Trns_EMCC_Achvd 0;
BA_ "GenSigTimeoutTime_IPC" SG_ 520 Trns_EMCC_Achvd 0;
BA_ "GenSigTimeoutTime_RFHM" SG_ 520 Trns_EMCC_Achvd 0;
BA_ "GenSigTimeoutTime_TCM" SG_ 520 Trns_EMCC_Achvd 0;
BA_ "GenSigStartValue" SG_ 520 TRNS_StpSt_FLT 1;
BA_ "GenSigTimeoutTime_AGSM" SG_ 520 TRNS_StpSt_FLT 0;
BA_ "GenSigTimeoutTime_ASBS" SG_ 520 TRNS_StpSt_FLT 0;
BA_ "GenSigTimeoutTime_BCM" SG_ 520 TRNS_StpSt_FLT 0;
BA_ "GenSigTimeoutTime_BSM" SG_ 520 TRNS_StpSt_FLT 0;
BA_ "GenSigTimeoutTime_CADM" SG_ 520 TRNS_StpSt_FLT 0;
BA_ "GenSigTimeoutTime_DMSM" SG_ 520 TRNS_StpSt_FLT 0;
BA_ "GenSigTimeoutTime_DTCM" SG_ 520 TRNS_StpSt_FLT 0;
BA_ "GenSigTimeoutTime_ELSDM" SG_ 520 TRNS_StpSt_FLT 0;
BA_ "GenSigTimeoutTime_ESL" SG_ 520 TRNS_StpSt_FLT 0;
BA_ "GenSigTimeoutTime_GNMM" SG_ 520 TRNS_StpSt_FLT 0;
BA_ "GenSigTimeoutTime_HCP" SG_ 520 TRNS_StpSt_FLT 0;
BA_ "GenSigTimeoutTime_IPC" SG_ 520 TRNS_StpSt_FLT 0;
BA_ "GenSigTimeoutTime_RFHM" SG_ 520 TRNS_StpSt_FLT 0;
BA_ "GenSigTimeoutTime_SGW" SG_ 520 TRNS_StpSt_FLT 0;
BA_ "GenSigTimeoutTime_TCM" SG_ 520 TRNS_StpSt_FLT 0;
BA_ "GenSigStartValue" SG_ 520 TurbineSpeed 65535;
BA_ "GenSigTimeoutTime_AGSM" SG_ 520 TurbineSpeed 0;
BA_ "GenSigTimeoutTime_ASBS" SG_ 520 TurbineSpeed 0;
BA_ "GenSigTimeoutTime_BCM" SG_ 520 TurbineSpeed 0;
BA_ "GenSigTimeoutTime_BSM" SG_ 520 TurbineSpeed 0;
BA_ "GenSigTimeoutTime_CADM" SG_ 520 TurbineSpeed 0;
BA_ "GenSigTimeoutTime_DMSM" SG_ 520 TurbineSpeed 0;
BA_ "GenSigTimeoutTime_DTCM" SG_ 520 TurbineSpeed 0;
BA_ "GenSigTimeoutTime_ELSDM" SG_ 520 TurbineSpeed 0;
BA_ "GenSigTimeoutTime_ESL" SG_ 520 TurbineSpeed 0;
BA_ "GenSigTimeoutTime_GNMM" SG_ 520 TurbineSpeed 0;
BA_ "GenSigTimeoutTime_IPC" SG_ 520 TurbineSpeed 0;
BA_ "GenSigTimeoutTime_RFHM" SG_ 520 TurbineSpeed 0;
BA_ "GenSigTimeoutTime_TCM" SG_ 520 TurbineSpeed 0;
BA_ "GenSigTimeoutTime_ADCAM" SG_ 1450 Low_Mode_Sts 0;
BA_ "GenSigTimeoutTime_EVCU2" SG_ 1450 Low_Mode_Sts 0;
BA_ "GenSigTimeoutTime_VDCM" SG_ 1450 Low_Mode_Sts 0;
BA_ "GenSigSendType" SG_ 1450 Low_Mode_Sts 3;
BA_ "GenSigTimeoutTime_BCM" SG_ 1450 Low_Mode_Sts 0;
BA_ "GenSigTimeoutTime_BSM" SG_ 1450 Low_Mode_Sts 0;
BA_ "GenSigTimeoutTime_DTCM" SG_ 1450 Low_Mode_Sts 0;
BA_ "GenSigTimeoutTime_ESL" SG_ 1450 Low_Mode_Sts 0;
BA_ "GenSigTimeoutTime_RFHM" SG_ 1450 Low_Mode_Sts 0;
BA_ "GenSigTimeoutTime_SGW" SG_ 1450 Low_Mode_Sts 0;
BA_ "GenSigTimeoutTime_TCM" SG_ 1450 Low_Mode_Sts 0;
BA_ "GenSigTimeoutTime_EVCU2" SG_ 1450 MessageCounter_TRANSM4 0;
BA_ "GenSigTimeoutTime_VDCM" SG_ 1450 MessageCounter_TRANSM4 0;
BA_ "GenSigTimeoutTime_BCM" SG_ 1450 MessageCounter_TRANSM4 0;
BA_ "GenSigTimeoutTime_SGW" SG_ 1450 MessageCounter_TRANSM4 0;
BA_ "GenSigTimeoutTime_ADCAM" SG_ 1450 ShiftMapNotAchieved 0;
BA_ "GenSigTimeoutTime_EVCU2" SG_ 1450 ShiftMapNotAchieved 0;
BA_ "GenSigTimeoutTime_VDCM" SG_ 1450 ShiftMapNotAchieved 0;
BA_ "GenSigTimeoutTime_EVCU2" SG_ 1450 GearEngaged 0;
BA_ "GenSigTimeoutTime_VDCM" SG_ 1450 GearEngaged 0;
BA_ "GenSigTimeoutTime_EVCU2" SG_ 1450 CRC_TRANSM4 0;
BA_ "GenSigTimeoutTime_VDCM" SG_ 1450 CRC_TRANSM4 0;
BA_ "GenSigTimeoutTime_BCM" SG_ 1450 CRC_TRANSM4 0;
BA_ "GenSigTimeoutTime_SGW" SG_ 1450 CRC_TRANSM4 0;
BA_ "GenSigTimeoutTime_ADCAM" SG_ 1450 MIReq 0;
BA_ "GenSigTimeoutTime_EVCU2" SG_ 1450 MIReq 0;
BA_ "GenSigTimeoutTime_VDCM" SG_ 1450 MIReq 0;
BA_ "GenSigTimeoutTime_ASBS" SG_ 1450 MessageCounter_TRANSM4 0;
BA_ "GenSigTimeoutTime_ELSDM" SG_ 1450 MessageCounter_TRANSM4 0;
BA_ "GenSigTimeoutTime_ESL" SG_ 1450 MessageCounter_TRANSM4 0;
BA_ "GenSigTimeoutTime_GNMM" SG_ 1450 MessageCounter_TRANSM4 0;
BA_ "GenSigTimeoutTime_RFHM" SG_ 1450 MessageCounter_TRANSM4 0;
BA_ "GenSigTimeoutTime_TCM" SG_ 1450 MessageCounter_TRANSM4 0;
BA_ "GenSigSendType" SG_ 1450 ShiftMapNotAchieved 3;
BA_ "GenSigTimeoutTime_AGSM" SG_ 1450 ShiftMapNotAchieved 0;
BA_ "GenSigTimeoutTime_ASBS" SG_ 1450 ShiftMapNotAchieved 0;
BA_ "GenSigTimeoutTime_BCM" SG_ 1450 ShiftMapNotAchieved 0;
BA_ "GenSigTimeoutTime_BSM" SG_ 1450 ShiftMapNotAchieved 0;
BA_ "GenSigTimeoutTime_CADM" SG_ 1450 ShiftMapNotAchieved 0;
BA_ "GenSigTimeoutTime_DMSM" SG_ 1450 ShiftMapNotAchieved 0;
BA_ "GenSigTimeoutTime_DTCM" SG_ 1450 ShiftMapNotAchieved 0;
BA_ "GenSigTimeoutTime_ELSDM" SG_ 1450 ShiftMapNotAchieved 0;
BA_ "GenSigTimeoutTime_ESL" SG_ 1450 ShiftMapNotAchieved 0;
BA_ "GenSigTimeoutTime_GNMM" SG_ 1450 ShiftMapNotAchieved 0;
BA_ "GenSigTimeoutTime_HCP" SG_ 1450 ShiftMapNotAchieved 0;
BA_ "GenSigTimeoutTime_IPC" SG_ 1450 ShiftMapNotAchieved 0;
BA_ "GenSigTimeoutTime_RFHM" SG_ 1450 ShiftMapNotAchieved 0;
BA_ "GenSigTimeoutTime_SGW" SG_ 1450 ShiftMapNotAchieved 0;
BA_ "GenSigTimeoutTime_TCM" SG_ 1450 ShiftMapNotAchieved 0;
BA_ "GenSigSendType" SG_ 1450 CrankEnable 3;
BA_ "GenSigTimeoutTime_AGSM" SG_ 1450 CrankEnable 0;
BA_ "GenSigTimeoutTime_ASBS" SG_ 1450 CrankEnable 0;
BA_ "GenSigTimeoutTime_BCM" SG_ 1450 CrankEnable 0;
BA_ "GenSigTimeoutTime_BSM" SG_ 1450 CrankEnable 0;
BA_ "GenSigTimeoutTime_CADM" SG_ 1450 CrankEnable 0;
BA_ "GenSigTimeoutTime_DMSM" SG_ 1450 CrankEnable 0;
BA_ "GenSigTimeoutTime_DTCM" SG_ 1450 CrankEnable 0;
BA_ "GenSigTimeoutTime_ELSDM" SG_ 1450 CrankEnable 0;
BA_ "GenSigTimeoutTime_ESL" SG_ 1450 CrankEnable 0;
BA_ "GenSigTimeoutTime_GNMM" SG_ 1450 CrankEnable 0;
BA_ "GenSigTimeoutTime_HCP" SG_ 1450 CrankEnable 0;
BA_ "GenSigTimeoutTime_IPC" SG_ 1450 CrankEnable 0;
BA_ "GenSigTimeoutTime_TCM" SG_ 1450 CrankEnable 0;
BA_ "GenSigSendType" SG_ 1450 GearEngaged 3;
BA_ "GenSigTimeoutTime_AGSM" SG_ 1450 GearEngaged 0;
BA_ "GenSigTimeoutTime_ASBS" SG_ 1450 GearEngaged 0;
BA_ "GenSigTimeoutTime_DMSM" SG_ 1450 GearEngaged 0;
BA_ "GenSigTimeoutTime_ELSDM" SG_ 1450 GearEngaged 0;
BA_ "GenSigTimeoutTime_ESL" SG_ 1450 GearEngaged 0;
BA_ "GenSigTimeoutTime_GNMM" SG_ 1450 GearEngaged 0;
BA_ "GenSigTimeoutTime_HCP" SG_ 1450 GearEngaged 0;
BA_ "GenSigTimeoutTime_TCM" SG_ 1450 GearEngaged 0;
BA_ "GenSigSendType" SG_ 1450 LimpHomeSts 3;
BA_ "GenSigTimeoutTime_AGSM" SG_ 1450 LimpHomeSts 0;
BA_ "GenSigTimeoutTime_ASBS" SG_ 1450 LimpHomeSts 0;
BA_ "GenSigTimeoutTime_BSM" SG_ 1450 LimpHomeSts 0;
BA_ "GenSigTimeoutTime_DMSM" SG_ 1450 LimpHomeSts 0;
BA_ "GenSigTimeoutTime_DTCM" SG_ 1450 LimpHomeSts 0;
BA_ "GenSigTimeoutTime_ELSDM" SG_ 1450 LimpHomeSts 0;
BA_ "GenSigTimeoutTime_ESL" SG_ 1450 LimpHomeSts 0;
BA_ "GenSigTimeoutTime_GNMM" SG_ 1450 LimpHomeSts 0;
BA_ "GenSigTimeoutTime_IPC" SG_ 1450 LimpHomeSts 0;
BA_ "GenSigTimeoutTime_RFHM" SG_ 1450 LimpHomeSts 0;
BA_ "GenSigTimeoutTime_SGW" SG_ 1450 LimpHomeSts 0;
BA_ "GenSigTimeoutTime_TCM" SG_ 1450 LimpHomeSts 0;
BA_ "GenSigSendType" SG_ 1450 TxDisengaged_Fault 3;
BA_ "GenSigTimeoutTime_AGSM" SG_ 1450 TxDisengaged_Fault 0;
BA_ "GenSigTimeoutTime_ASBS" SG_ 1450 TxDisengaged_Fault 0;
BA_ "GenSigTimeoutTime_BCM" SG_ 1450 TxDisengaged_Fault 0;
BA_ "GenSigTimeoutTime_BSM" SG_ 1450 TxDisengaged_Fault 0;
BA_ "GenSigTimeoutTime_CADM" SG_ 1450 TxDisengaged_Fault 0;
BA_ "GenSigTimeoutTime_DMSM" SG_ 1450 TxDisengaged_Fault 0;
BA_ "GenSigTimeoutTime_DTCM" SG_ 1450 TxDisengaged_Fault 0;
BA_ "GenSigTimeoutTime_ELSDM" SG_ 1450 TxDisengaged_Fault 0;
BA_ "GenSigTimeoutTime_ESL" SG_ 1450 TxDisengaged_Fault 0;
BA_ "GenSigTimeoutTime_GNMM" SG_ 1450 TxDisengaged_Fault 0;
BA_ "GenSigTimeoutTime_HCP" SG_ 1450 TxDisengaged_Fault 0;
BA_ "GenSigTimeoutTime_IPC" SG_ 1450 TxDisengaged_Fault 0;
BA_ "GenSigTimeoutTime_RFHM" SG_ 1450 TxDisengaged_Fault 0;
BA_ "GenSigTimeoutTime_SGW" SG_ 1450 TxDisengaged_Fault 0;
BA_ "GenSigTimeoutTime_TCM" SG_ 1450 TxDisengaged_Fault 0;
BA_ "GenSigTimeoutTime_ASBS" SG_ 1450 CRC_TRANSM4 0;
BA_ "GenSigTimeoutTime_ELSDM" SG_ 1450 CRC_TRANSM4 0;
BA_ "GenSigTimeoutTime_ESL" SG_ 1450 CRC_TRANSM4 0;
BA_ "GenSigTimeoutTime_GNMM" SG_ 1450 CRC_TRANSM4 0;
BA_ "GenSigTimeoutTime_RFHM" SG_ 1450 CRC_TRANSM4 0;
BA_ "GenSigTimeoutTime_TCM" SG_ 1450 CRC_TRANSM4 0;
BA_ "GenSigSendType" SG_ 1450 MIReq 3;
BA_ "GenSigTimeoutTime_AGSM" SG_ 1450 MIReq 0;
BA_ "GenSigTimeoutTime_ASBS" SG_ 1450 MIReq 0;
BA_ "GenSigTimeoutTime_BCM" SG_ 1450 MIReq 0;
BA_ "GenSigTimeoutTime_BSM" SG_ 1450 MIReq 0;
BA_ "GenSigTimeoutTime_CADM" SG_ 1450 MIReq 0;
BA_ "GenSigTimeoutTime_DMSM" SG_ 1450 MIReq 0;
BA_ "GenSigTimeoutTime_DTCM" SG_ 1450 MIReq 0;
BA_ "GenSigTimeoutTime_ELSDM" SG_ 1450 MIReq 0;
BA_ "GenSigTimeoutTime_ESL" SG_ 1450 MIReq 0;
BA_ "GenSigTimeoutTime_GNMM" SG_ 1450 MIReq 0;
BA_ "GenSigTimeoutTime_HCP" SG_ 1450 MIReq 0;
BA_ "GenSigTimeoutTime_IPC" SG_ 1450 MIReq 0;
BA_ "GenSigTimeoutTime_RFHM" SG_ 1450 MIReq 0;
BA_ "GenSigTimeoutTime_TCM" SG_ 1450 MIReq 0;
BA_ "GenSigSendType" SG_ 1450 ShiftInProgress 3;
BA_ "GenSigTimeoutTime_AGSM" SG_ 1450 ShiftInProgress 0;
BA_ "GenSigTimeoutTime_ASBS" SG_ 1450 ShiftInProgress 0;
BA_ "GenSigTimeoutTime_CADM" SG_ 1450 ShiftInProgress 0;
BA_ "GenSigTimeoutTime_DMSM" SG_ 1450 ShiftInProgress 0;
BA_ "GenSigTimeoutTime_DTCM" SG_ 1450 ShiftInProgress 0;
BA_ "GenSigTimeoutTime_ELSDM" SG_ 1450 ShiftInProgress 0;
BA_ "GenSigTimeoutTime_ESL" SG_ 1450 ShiftInProgress 0;
BA_ "GenSigTimeoutTime_GNMM" SG_ 1450 ShiftInProgress 0;
BA_ "GenSigTimeoutTime_IPC" SG_ 1450 ShiftInProgress 0;
BA_ "GenSigTimeoutTime_RFHM" SG_ 1450 ShiftInProgress 0;
BA_ "GenSigTimeoutTime_TCM" SG_ 1450 ShiftInProgress 0;
BA_ "GenSigSendType" SG_ 1450 ShiftLeverPosition 3;
BA_ "GenSigTimeoutTime_ASBS" SG_ 1450 ShiftLeverPosition 0;
BA_ "GenSigTimeoutTime_DMSM" SG_ 1450 ShiftLeverPosition 0;
BA_ "GenSigTimeoutTime_DTCM" SG_ 1450 ShiftLeverPosition 0;
BA_ "GenSigTimeoutTime_ELSDM" SG_ 1450 ShiftLeverPosition 0;
BA_ "GenSigTimeoutTime_ESL" SG_ 1450 ShiftLeverPosition 0;
BA_ "GenSigTimeoutTime_GNMM" SG_ 1450 ShiftLeverPosition 0;
BA_ "GenSigTimeoutTime_RFHM" SG_ 1450 ShiftLeverPosition 0;
BA_ "GenSigTimeoutTime_TCM" SG_ 1450 ShiftLeverPosition 0;
BA_ "GenSigSendType" SG_ 1450 ShiftModeSts 3;
BA_ "GenSigTimeoutTime_AGSM" SG_ 1450 ShiftModeSts 0;
BA_ "GenSigTimeoutTime_ASBS" SG_ 1450 ShiftModeSts 0;
BA_ "GenSigTimeoutTime_BCM" SG_ 1450 ShiftModeSts 0;
BA_ "GenSigTimeoutTime_BSM" SG_ 1450 ShiftModeSts 0;
BA_ "GenSigTimeoutTime_DMSM" SG_ 1450 ShiftModeSts 0;
BA_ "GenSigTimeoutTime_ELSDM" SG_ 1450 ShiftModeSts 0;
BA_ "GenSigTimeoutTime_ESL" SG_ 1450 ShiftModeSts 0;
BA_ "GenSigTimeoutTime_GNMM" SG_ 1450 ShiftModeSts 0;
BA_ "GenSigTimeoutTime_RFHM" SG_ 1450 ShiftModeSts 0;
BA_ "GenSigTimeoutTime_TCM" SG_ 1450 ShiftModeSts 0;
BA_ "GenSigSendType" SG_ 1450 TransmissionFailSts 3;
BA_ "GenSigTimeoutTime_ASBS" SG_ 1450 TransmissionFailSts 0;
BA_ "GenSigTimeoutTime_BSM" SG_ 1450 TransmissionFailSts 0;
BA_ "GenSigTimeoutTime_CADM" SG_ 1450 TransmissionFailSts 0;
BA_ "GenSigTimeoutTime_DMSM" SG_ 1450 TransmissionFailSts 0;
BA_ "GenSigTimeoutTime_DTCM" SG_ 1450 TransmissionFailSts 0;
BA_ "GenSigTimeoutTime_ELSDM" SG_ 1450 TransmissionFailSts 0;
BA_ "GenSigTimeoutTime_ESL" SG_ 1450 TransmissionFailSts 0;
BA_ "GenSigTimeoutTime_GNMM" SG_ 1450 TransmissionFailSts 0;
BA_ "GenSigTimeoutTime_HCP" SG_ 1450 TransmissionFailSts 0;
BA_ "GenSigTimeoutTime_IPC" SG_ 1450 TransmissionFailSts 0;
BA_ "GenSigTimeoutTime_RFHM" SG_ 1450 TransmissionFailSts 0;
BA_ "GenSigTimeoutTime_TCM" SG_ 1450 TransmissionFailSts 0;
BA_ "GenSigSendType" SG_ 1450 TxDisengaged 3;
BA_ "GenSigTimeoutTime_AGSM" SG_ 1450 TxDisengaged 0;
BA_ "GenSigTimeoutTime_ASBS" SG_ 1450 TxDisengaged 0;
BA_ "GenSigTimeoutTime_BCM" SG_ 1450 TxDisengaged 0;
BA_ "GenSigTimeoutTime_BSM" SG_ 1450 TxDisengaged 0;
BA_ "GenSigTimeoutTime_CADM" SG_ 1450 TxDisengaged 0;
BA_ "GenSigTimeoutTime_DMSM" SG_ 1450 TxDisengaged 0;
BA_ "GenSigTimeoutTime_DTCM" SG_ 1450 TxDisengaged 0;
BA_ "GenSigTimeoutTime_ELSDM" SG_ 1450 TxDisengaged 0;
BA_ "GenSigTimeoutTime_ESL" SG_ 1450 TxDisengaged 0;
BA_ "GenSigTimeoutTime_GNMM" SG_ 1450 TxDisengaged 0;
BA_ "GenSigTimeoutTime_IPC" SG_ 1450 TxDisengaged 0;
BA_ "GenSigTimeoutTime_RFHM" SG_ 1450 TxDisengaged 0;
BA_ "GenSigTimeoutTime_SGW" SG_ 1450 TxDisengaged 0;
BA_ "GenSigTimeoutTime_TCM" SG_ 1450 TxDisengaged 0;
BA_ "GenSigTimeoutTime_ESL" SG_ 1053 VIN_DATA 0;
BA_ "GenSigTimeoutTime_ESL" SG_ 1053 VIN_MSG 0;
BA_ "GenSigTimeoutTime_BCM" SG_ 1053 VIN_DATA 0;
BA_ "GenSigStartValue" SG_ 1053 VIN_MSG 3;
BA_ "GenSigTimeoutTime_BCM" SG_ 1053 VIN_MSG 0;
BA_ "GenSigTimeoutTime_ADCAM" SG_ 2564502513 N_PDU_18DB33F1 0;
BA_ "GenSigTimeoutTime_EVCU2" SG_ 2564502513 N_PDU_18DB33F1 0;
BA_ "GenSigTimeoutTime_VDCM" SG_ 2564502513 N_PDU_18DB33F1 0;
BA_ "GenSigTimeoutTime_AGSM" SG_ 2564502513 N_PDU_18DB33F1 0;
BA_ "GenSigTimeoutTime_ASBS" SG_ 2564502513 N_PDU_18DB33F1 0;
BA_ "GenSigTimeoutTime_BCM" SG_ 2564502513 N_PDU_18DB33F1 0;
BA_ "GenSigTimeoutTime_BSM" SG_ 2564502513 N_PDU_18DB33F1 0;
VAL_ 264 LwsAngle 65535 "SNA";
VAL_ 264 LwsSpeed 4095 "SNA";
VAL_ 1053 VIN_MSG 0 "VIN_LO" 1 "VIN_MID" 2 "VIN_HI" 3 "SNA";
VAL_ 1450 TxDisengaged 0 "Engaged" 1 "Disengaged";
VAL_ 1450 TransmissionFailSts 0 "Fail_not_present" 1 "Fail_present";
VAL_ 1450 ShiftModeSts 0 "Manual" 1 "Automatic";
VAL_ 1450 ShiftLeverPosition 0 "No_Selection_Active_Or_Available" 1 "P" 2 "R" 3 "N" 4 "D" 5 "L" 6 "TIP_Autostick" 7 "Plus" 8 "Minus" 9 "Sport" 10 "Not_Used" 11 "Not_Used" 12 "Not_Used" 13 "Not_Used" 14 "Not_Used" 15 "SNA";
VAL_ 1450 ShiftInProgress 0 "No Shift in progress" 1 "Shift in progress";
VAL_ 1450 MIReq 0 "No_EOBD_error" 1 "EOBD_error";
VAL_ 1450 LimpHomeSts 0 "NotActive" 1 "Active";
VAL_ 1450 GearEngaged 0 "Neutral" 1 "ForwardGear_1" 2 "ForwardGear_2" 3 "ForwardGear_3" 4 "ForwardGear_4" 5 "ForwardGear_5" 6 "ForwardGear_6" 7 "ForwardGear_7" 8 "ForwardGear_8" 9 "ForwardGear_9" 13 "Parking" 14 "ReverseGear" 15 "SNA";
VAL_ 1450 CrankEnable 0 "Disabled" 1 "Enabled";
VAL_ 520 TurbineSpeed 65535 "SNA";
VAL_ 520 TRNS_StpSt_FLT 0 "Not_Present" 1 "Present";
VAL_ 520 Trns_EMCC_Achvd 0 "False" 1 "True";
VAL_ 520 TransReadyForESS 0 "Not_Ready" 1 "Ready";
VAL_ 520 TransmissionTemperature 63 "SNA";
VAL_ 520 OUTPUT_SPEED 65535 "SNA";
VAL_ 520 APCM_Rq 0 "OFF" 1 "ON" 2 "PENDING" 3 "SNA";
VAL_ 519 IgnPosSts 0 "Initialization" 1 "IGN_LK" 3 "ACC" 4 "RUN" 5 "START" 7 "SNA";
VAL_ 274 LongAcceleration 4095 "SNA";
VAL_ 274 LatAcceleration 4095 "SNA";
VAL_ 1058 InputsGDFail 0 "False" 1 "True";
VAL_ 1058 Inp_ICC_Fail 0 "Fail_Not_Present" 1 "Fail_Present";
VAL_ 1058 IgnCntrTrue 0 "False" 1 "True";
VAL_ 1058 GenDenominator 0 "False" 1 "True";
VAL_ 1058 EngineOFFTime 1023 "SNA";
VAL_ 1058 CldStrtDenominator 0 "Not_Active" 1 "Active";
VAL_ 1058 CarbWarmUp 0 "False" 1 "True";
VAL_ 1058 CARB_PERM 0 "False" 1 "True";
VAL_ 600 OilChgRst 0 "Not_Active" 1 "Active";
VAL_ 1626 IMPACTConfirm 0 "Actuate" 1 "Do_Not_Actuate";
VAL_ 1626 IMPACTCommand 0 "Do_Not_Actuate" 1 "Actuate";
VAL_ 104 MKKey2org22 85 "FIX__MKKey_2";
VAL_ 104 MKKey1org21 84 "FIX__MKKey_1";
VAL_ 104 MKKey_6 77 "FIX__MKKey_6";
VAL_ 104 MKKey_5 1 "FIX__MKKey_5";
VAL_ 104 MKKey_4 214 "FIX__MKKey_4";
VAL_ 104 MKKey_3 36 "FIX__MKKey_3";
VAL_ 100 rnd_4 0 "Val1_rnd_4" 170 "Val5_rnd_4" 203 "Val2_rnd_4" 221 "Val3_rnd_4" 238 "Val4_rnd_4";
VAL_ 100 rnd_3 0 "Val1_rnd_3" 19 "Val3_rnd_3" 21 "Val5_rnd_3" 32 "Val4_rnd_3" 129 "Val2_rnd_3";
VAL_ 100 rnd_2 0 "Val1_rnd_2" 26 "Val3_rnd_2" 43 "Val5_rnd_2" 79 "Val2_rnd_2" 168 "Val4_rnd_2";
VAL_ 100 rnd_1 0 "Val1_rnd_1" 58 "Val2_rnd_1" 59 "Val3_rnd_1" 60 "Val4_rnd_1" 61 "Val5_rnd_1" 62 "Val6_rnd_1" 63 "Val7_rnd_1" 64 "Val8_rnd_1" 65 "Val9_rnd_1" 66 "ValA_rnd_1" 67 "ValB_rnd_1" 68 "ValC_rnd_1" 69 "ValD_rnd_1" 70 "ValE_rnd_1" 71 "ValF_rnd_1";
VAL_ 100 f1_2 0 "Val1_f1_2" 5 "Val2_f1_2" 13 "Val4_f1_2" 14 "Val3_f1_2" 15 "Val5_f1_2";
VAL_ 100 f1_1 0 "Val1_f1_1" 81 "Val5_f1_1" 119 "Val2_f1_1" 145 "Val3_f1_1" 159 "Val4_f1_1";
VAL_ 100 ControlEncodingReq 5 "ControlEncoding_ENQ" 6 "ControlEncoding_ACK" 21 "ControlEncoding_NACK" 132 "ControlEncoding_EOTp" 133 "ControlEncoding_ENQp" 134 "ControlEncoding_ACK1p" 135 "ControlEncoding_ACK2p";
VAL_ 1955 IBS3_T_BATT 255 "SNA";
VAL_ 1955 IBS3_SOH_Q 127 "SNA";
VAL_ 1955 IBS3_SOC 127 "SNA";
VAL_ 1450 ShiftMapNotAchieved 0 "Achieved" 1 "Not_Achieved";
VAL_ 520 EngShutOffRq_TCM 0 "FALSE" 1 "TRUE";
VAL_ 274 LongAccelerationFailSts 0 "Fail_Not_Present" 1 "Fail_Present";
VAL_ 274 LatAccelerationFailSts 0 "Fail_Not_Present" 1 "Fail_Present";
VAL_ 1058 OAT_PT_EstV 0 "Valid" 1 "Not_Valid";
VAL_ 1058 EstCatCnvTmp 255 "SNA";
VAL_ 1058 EngOffTmPTV 1 "SNA";
VAL_ 1058 EngOffTmPT 0 "SNA";
VAL_ 1058 EngIntAirTmpV 0 "Valid" 1 "Not_Valid";
VAL_ 1058 EngIntAirTmp 255 "SNA";
VAL_ 1058 ECM_HoodAjar 0 "Closed" 1 "Ajar" 2 "Faulted" 3 "Indetermine (SNA)";
VAL_ 1058 BarPrsAbsV 0 "Valid" 1 "Not_Valid";
VAL_ 1626 IMPACTThreshold 0 "Threshold_Not_Met" 1 "Threshold_Met";
VAL_ 264 EngineFanRequestActivation 0 "False" 1 "True";
VAL_ 520 Trans_ESS_Inhibit 0 "False" 1 "True";
VAL_ 520 GearEngagedForDisplay 0 "Initialize" 1 "1st_gear" 2 "2nd_gear" 3 "3rd_gear" 4 "4th_gear" 5 "5th_gear" 6 "6th_gear" 7 "7th_gear" 8 "8th_gear " 9 "9th_gear" 10 "Not_used1" 11 "Not_Used2" 12 "P" 13 "N" 14 "R" 15 "D" 16 "L" 17 "M" 18 "S" 31 "SNA";
VAL_ 520 AirFlowRequest_TCM 127 "SNA";
VAL_ 600 DisplayedSpeedLimSts 0 "Sign_Not_Detected" 1 "Speed_Limit_0" 2 "Speed_Limit_1" 3 "Speed_Limit_2" 4 "Speed_Limit_3" 5 "Speed_Limit_4" 6 "Speed_Limit_5" 7 "Speed_Limit_6" 8 "Speed_Limit_7" 9 "Speed_Limit_8" 10 "Speed_Limit_9" 11 "Speed_Limit_10" 12 "Speed_Limit_11" 13 "Speed_Limit_12" 14 "Speed_Limit_13" 15 "Speed_Limit_14" 16 "Speed_Limit_15" 17 "Speed_Limit_16" 18 "Speed_Limit_17" 19 "Speed_Limit_18" 20 "Speed_Limit_19" 21 "Speed_Limit_20" 22 "Speed_Limit_21" 23 "Speed_Limit_22" 24 "Speed_Limit_23" 25 "Speed_Limit_24" 26 "Speed_Limit_25" 27 "Speed_Limit_26" 28 "Speed_Limit_27" 29 "Speed_Limit_28" 30 "Speed_Limit_29" 31 "Speed_Limit_30" 32 "Speed_Limit_31" 33 "Speed_Limit_32" 34 "Speed_Limit_33" 35 "Speed_Limit_34" 36 "Speed_Limit_35" 37 "Speed_Limit_36" 38 "Speed_Limit_37" 39 "Speed_Limit_38" 40 "Speed_Limit_39" 41 "Speed_Limit_40" 42 "Speed_Limit_41" 43 "Speed_Limit_42" 44 "Speed_Limit_43" 45 "Speed_Limit_44" 46 "Speed_Limit_45" 47 "Speed_Limit_46" 48 "Speed_Limit_47" 49 "Speed_Limit_48" 50 "Speed_Limit_49" 51 "Speed_Limit_50" 52 "Speed_Limit_51" 53 "Speed_Limit_52" 54 "Speed_Limit_53" 55 "Speed_Limit_54" 56 "Speed_Limit_55" 57 "Speed_Limit_56" 58 "Speed_Limit_57" 59 "Speed_Limit_58" 60 "Speed_Limit_59" 61 "Speed_Limit_60" 62 "Speed_Limit_61" 63 "Speed_Limit_62" 64 "Speed_Limit_63" 65 "Speed_Limit_64" 66 "Speed_Limit_65" 67 "Speed_Limit_66" 68 "Speed_Limit_67" 69 "Speed_Limit_68" 70 "Speed_Limit_69" 71 "Speed_Limit_70" 72 "Speed_Limit_71" 73 "Speed_Limit_72" 74 "Speed_Limit_73" 75 "Speed_Limit_74" 76 "Speed_Limit_75" 77 "Speed_Limit_76" 78 "Speed_Limit_77" 79 "Speed_Limit_78" 80 "Speed_Limit_79" 81 "Speed_Limit_80" 82 "Speed_Limit_81" 83 "Speed_Limit_82" 84 "Speed_Limit_83" 85 "Speed_Limit_84" 86 "Speed_Limit_85" 87 "Speed_Limit_86" 88 "Speed_Limit_87" 89 "Speed_Limit_88" 90 "Speed_Limit_89" 91 "Speed_Limit_90" 92 "Speed_Limit_91" 93 "Speed_Limit_92" 94 "Speed_Limit_93" 95 "Speed_Limit_94" 96 "Speed_Limit_95" 97 "Speed_Limit_96" 98 "Speed_Limit_97" 99 "Speed_Limit_98" 100 "Speed_Limit_99" 101 "Speed_Limit_100" 102 "Speed_Limit_101" 103 "Speed_Limit_102" 104 "Speed_Limit_103" 105 "Speed_Limit_104" 106 "Speed_Limit_105" 107 "Speed_Limit_106" 108 "Speed_Limit_107" 109 "Speed_Limit_108" 110 "Speed_Limit_109" 111 "Speed_Limit_110" 112 "Speed_Limit_111" 113 "Speed_Limit_112" 114 "Speed_Limit_113" 115 "Speed_Limit_114" 116 "Speed_Limit_115" 117 "Speed_Limit_116" 118 "Speed_Limit_117" 119 "Speed_Limit_118" 120 "Speed_Limit_119" 121 "Speed_Limit_120" 122 "Speed_Limit_121" 123 "Speed_Limit_122" 124 "Speed_Limit_123" 125 "Speed_Limit_124" 126 "Speed_Limit_125" 127 "Speed_Limit_126" 128 "Speed_Limit_127" 129 "Speed_Limit_128" 130 "Speed_Limit_129" 131 "Speed_Limit_130" 132 "Speed_Limit_131" 133 "Speed_Limit_132" 134 "Speed_Limit_133" 135 "Speed_Limit_134" 136 "Speed_Limit_135" 137 "Speed_Limit_136" 138 "Speed_Limit_137" 139 "Speed_Limit_138" 140 "Speed_Limit_139" 141 "Speed_Limit_140" 142 "Speed_Limit_141" 143 "Speed_Limit_142" 144 "Speed_Limit_143" 145 "Speed_Limit_144" 146 "Speed_Limit_145" 147 "Speed_Limit_146" 148 "Speed_Limit_147" 149 "Speed_Limit_148" 150 "Speed_Limit_149" 151 "Speed_Limit_150" 152 "Speed_Limit_151" 153 "Speed_Limit_152" 154 "Speed_Limit_153" 155 "Speed_Limit_154" 156 "Speed_Limit_155" 157 "Speed_Limit_156" 158 "Speed_Limit_157" 159 "Speed_Limit_158" 160 "Speed_Limit_159" 161 "Speed_Limit_160" 162 "Speed_Limit_161" 163 "Speed_Limit_162" 164 "Speed_Limit_163" 165 "Speed_Limit_164" 166 "Speed_Limit_165" 167 "Speed_Limit_166" 168 "Speed_Limit_167" 169 "Speed_Limit_168" 170 "Speed_Limit_169" 171 "Speed_Limit_170" 172 "Speed_Limit_171" 173 "Speed_Limit_172" 174 "Speed_Limit_173" 175 "Speed_Limit_174" 176 "Speed_Limit_175" 177 "Speed_Limit_176" 178 "Speed_Limit_177" 179 "Speed_Limit_178" 180 "Speed_Limit_179" 181 "Speed_Limit_180" 182 "Speed_Limit_181" 183 "Speed_Limit_182" 184 "Speed_Limit_183" 185 "Speed_Limit_184" 186 "Speed_Limit_185" 187 "Speed_Limit_186" 188 "Speed_Limit_187" 189 "Speed_Limit_188" 190 "Speed_Limit_189" 191 "Speed_Limit_190" 192 "Speed_Limit_191" 193 "Speed_Limit_192" 194 "Speed_Limit_193" 195 "Speed_Limit_194" 196 "Speed_Limit_195" 197 "Speed_Limit_196" 198 "Speed_Limit_197" 199 "Speed_Limit_198" 200 "Speed_Limit_199" 201 "Speed_Limit_200" 202 "Speed_Limit_201" 203 "Speed_Limit_202" 204 "Speed_Limit_203" 205 "Speed_Limit_204" 206 "Speed_Limit_205" 207 "Speed_Limit_206" 208 "Speed_Limit_207" 209 "Speed_Limit_208" 210 "Speed_Limit_209" 211 "Speed_Limit_210" 212 "Speed_Limit_211" 213 "Speed_Limit_212" 214 "Speed_Limit_213" 215 "Speed_Limit_214" 216 "Speed_Limit_215" 217 "Speed_Limit_216" 218 "Speed_Limit_217" 219 "Speed_Limit_218" 220 "Speed_Limit_219" 221 "Speed_Limit_220" 222 "Speed_Limit_221" 223 "Speed_Limit_222" 224 "Speed_Limit_223" 225 "Speed_Limit_224" 226 "Speed_Limit_225" 227 "Speed_Limit_226" 228 "Speed_Limit_227" 229 "Speed_Limit_228" 230 "Speed_Limit_229" 231 "Speed_Limit_230" 232 "Speed_Limit_231" 233 "Speed_Limit_232" 234 "Speed_Limit_233" 254 "Speed_Limit_Unlimited" 255 "End_Speed_Limit";
VAL_ 1955 IBS3_TempFailStatus 0 "Fail_not_present" 1 "Fail_present";
VAL_ 1955 IBS3_SOH_Q_Accuracy 0 "Inaccurate" 1 "Accurate";
VAL_ 1955 IBS3_SOC_Accuracy 0 "Inaccurate" 1 "Accurate";
VAL_ 1955 IBS3_FLAG_DISCONNECT 0 "No_Disconnect" 1 "Disconnect";
VAL_ 1450 TxDisengaged_Fault 0 "No_Fault" 1 "Fault";
VAL_ 1450 Low_Mode_Sts 0 "Not_Active" 1 "Active" 3 "SNA";
VAL_ 1428 GlobDrvMdRq 0 "Not_Pressed" 1 "Auto" 2 "Sport" 3 "Track" 4 "Wet_Snow" 5 "Valet" 6 "Rock" 7 "Tow" 8 "ECO" 9 "Launch_Control" 10 "All" 11 "Custom" 12 "Mud" 13 "Sand" 14 "Plus" 15 "Ice" 16 "Dynamic" 17 "OffRoad" 18 "Baja" 19 "Mud_Sand" 20 "Drag" 21 "Line_Lock" 22 "Drift" 23 "Donut" 24 "RWD" 31 "SNA";
VAL_ 1483 Ajar 0 "False" 1 "True";
VAL_ 1483 Pawl 0 "False" 1 "True";
VAL_ 1483 Pre_Rest 0 "False" 1 "True";
VAL_ 1483 Rewind 0 "False" 1 "True";

SIG_GROUP_ 1450 TRANSM_FD_4_Pkt 1 : TxDisengaged TransmissionFailSts ShiftModeSts ShiftLeverPosition ShiftInProgress MIReq LimpHomeSts GearEngaged CrankEnable ShiftMapNotAchieved MessageCounter_TRANSM4 CRC_TRANSM4 TxDisengaged_Fault Low_Mode_Sts;
SIG_GROUP_ 520 TRANSM_FD_2_Pkt 1 : TurbineSpeed TRNS_StpSt_FLT Trns_EMCC_Achvd TransReadyForESS TransmissionTemperature OUTPUT_SPEED APCM_Rq MessageCounter_TRANSM2 EngShutOffRq_TCM CRC_TRANSM2 Trans_ESS_Inhibit GearEngagedForDisplay AirFlowRequest_TCM;
SIG_GROUP_ 274 ORC_FD_3_Pkt 1 : LongAcceleration LatAcceleration MessageCounter_ORC3 LongAccelerationFailSts LatAccelerationFailSts CRC_ORC3;
SIG_GROUP_ 1954 ORC_FD_2_Pkt 1 : MessageCounter_ORC2 CRC_ORC2 DrvSbltUnFltr_1;
SIG_GROUP_ 104 IMMO_CODE_RESPONSE_Pkt 1 : MKKey2org22 MKKey1org21 MKKey_6 MKKey_5 MKKey_4 MKKey_3 ControlEncodingRsp;
SIG_GROUP_ 100 IMMO_CODE_REQUEST_Pkt 1 : rnd_4 rnd_3 rnd_2 rnd_1 f1_2 f1_1 ControlEncodingReq;
SIG_GROUP_ 264 EPS_FD_1_Pkt 1 : LwsAngle LwsSpeed MessageCounter_EPS1 CRC_EPS1 EngineFanRequestActivation;
